VERSION ""

NS_ :

BS_:

BU_: Vector__XXX

BO_ 2566751742 EFL_P8: 8 Vector__XXX
SG_ EngIntkValveActOilPressForCyl13 : 0|16@1+ (0.1,0) [0|6425.5] "kPa" Vector__XXX
SG_ EngIntkValveActOilPressForCyl14 : 16|16@1+ (0.1,0) [0|6425.5] "kPa" Vector__XXX
SG_ EngIntkValveActOilPressForCyl15 : 32|16@1+ (0.1,0) [0|6425.5] "kPa" Vector__XXX
SG_ EngIntkValveActOilPressForCyl16 : 48|16@1+ (0.1,0) [0|6425.5] "kPa" Vector__XXX

BO_ 2566751998 EFL_P7: 8 Vector__XXX
SG_ EngIntkValveActOilPressForCyl9 : 0|16@1+ (0.1,0) [0|6425.5] "kPa" Vector__XXX
SG_ EngIntkValveActOilPressForCyl10 : 16|16@1+ (0.1,0) [0|6425.5] "kPa" Vector__XXX
SG_ EngIntkValveActOilPressForCyl11 : 32|16@1+ (0.1,0) [0|6425.5] "kPa" Vector__XXX
SG_ EngIntkValveActOilPressForCyl12 : 48|16@1+ (0.1,0) [0|6425.5] "kPa" Vector__XXX

BO_ 2566752254 EFL_P6: 8 Vector__XXX
SG_ EngIntkValveActOilPressForCyl5 : 0|16@1+ (0.1,0) [0|6425.5] "kPa" Vector__XXX
SG_ EngIntkValveActOilPressForCyl6 : 16|16@1+ (0.1,0) [0|6425.5] "kPa" Vector__XXX
SG_ EngIntkValveActOilPressForCyl7 : 32|16@1+ (0.1,0) [0|6425.5] "kPa" Vector__XXX
SG_ EngIntkValveActOilPressForCyl8 : 48|16@1+ (0.1,0) [0|6425.5] "kPa" Vector__XXX

BO_ 2566752510 EFL_P5: 8 Vector__XXX
SG_ EngIntkValveActOilPressForCyl1 : 0|16@1+ (0.1,0) [0|6425.5] "kPa" Vector__XXX
SG_ EngIntkValveActOilPressForCyl2 : 16|16@1+ (0.1,0) [0|6425.5] "kPa" Vector__XXX
SG_ EngIntkValveActOilPressForCyl3 : 32|16@1+ (0.1,0) [0|6425.5] "kPa" Vector__XXX
SG_ EngIntkValveActOilPressForCyl4 : 48|16@1+ (0.1,0) [0|6425.5] "kPa" Vector__XXX

BO_ 2566752766 VDS2: 8 Vector__XXX
SG_ VehicleRoll : 0|16@1+ (0.0078125,-200) [-200|301.99] "deg" Vector__XXX

BO_ 2633861886 J2012: 8 Vector__XXX
SG_ NumberOfJ2012DTCs : 0|8@1+ (1,0) [0|250] "" Vector__XXX
SG_ J2012DTC : 15|40@0+ (1,0) [0|0] "ASCII" Vector__XXX
SG_ J2012DTCStatus : 48|1@1+ (1,0) [0|1] "" Vector__XXX
SG_ J2012DTCOccurrenceCount : 49|7@1+ (1,0) [0|127] "" Vector__XXX

BO_ 2566753278 AT2GP: 8 Vector__XXX
SG_ Aftrtrtmnt2DslPFIntkPressure : 0|16@1+ (0.1,0) [0|6425.5] "kPa" Vector__XXX
SG_ Aftrtrtmnt2DslPFOtltPressure : 16|16@1+ (0.1,0) [0|6425.5] "kPa" Vector__XXX

BO_ 2566753534 AT1GP: 8 Vector__XXX
SG_ Aftrtrtmnt1DslPFIntkPressure : 0|16@1+ (0.1,0) [0|6425.5] "kPa" Vector__XXX
SG_ Aftrtrtmnt1DslPFOtltPressure : 16|16@1+ (0.1,0) [0|6425.5] "kPa" Vector__XXX

BO_ 2566753790 UTACER: 8 Vector__XXX
SG_ UtilityTotalKVArHoursExport : 0|32@1+ (1,0) [0|4211081215] "kVArh" Vector__XXX
SG_ UtilityTotalKVArHoursImport : 32|32@1+ (1,0) [0|4211081215] "kVArh" Vector__XXX

BO_ 2566754046 GTACER: 8 Vector__XXX
SG_ GeneratorTotalKVArHoursExport : 0|32@1+ (1,0) [0|4211081215] "kVArh" Vector__XXX
SG_ GeneratorTotalKVArHoursImport : 32|32@1+ (1,0) [0|4211081215] "kVArh" Vector__XXX

BO_ 2566754302 GTACPP: 8 Vector__XXX
SG_ GeneratorTotalPercentKW : 0|16@1+ (0.0078125,-251) [-251|250.99] "%" Vector__XXX
SG_ GeneratorTotalPercentKVA : 16|16@1+ (0.0078125,-251) [-251|250.99] "%" Vector__XXX
SG_ GeneratorTotalPercentKVAr : 32|16@1+ (0.0078125,-251) [-251|250.99] "%" Vector__XXX

BO_ 2566754558 AETC: 8 Vector__XXX
SG_ AETCDataCollectionStandard : 0|4@1+ (1,0) [0|15] "" Vector__XXX
SG_ NumberOfAETCDataPoints : 4|4@1+ (1,0) [0|15] "" Vector__XXX

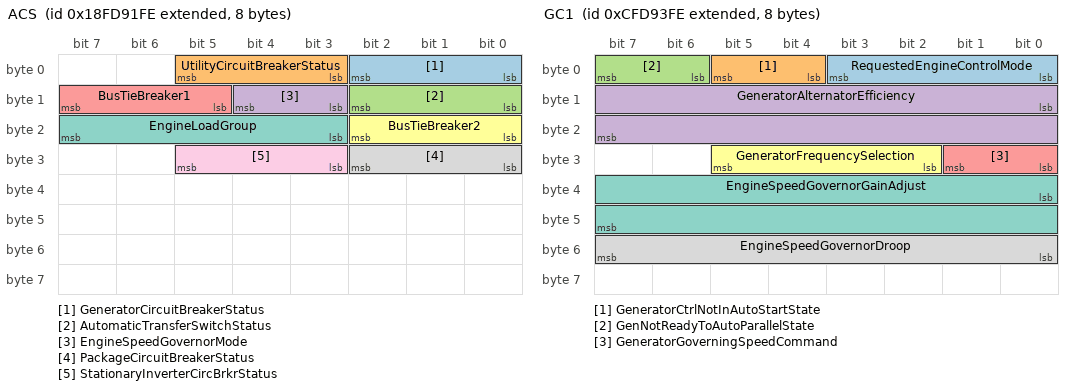
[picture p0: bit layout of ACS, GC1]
BO_ 2566754814 ACS: 8 Vector__XXX
SG_ GeneratorCircuitBreakerStatus : 0|3@1+ (1,0) [0|7] "" Vector__XXX
SG_ UtilityCircuitBreakerStatus : 3|3@1+ (1,0) [0|7] "" Vector__XXX
SG_ AutomaticTransferSwitchStatus : 8|3@1+ (1,0) [0|7] "" Vector__XXX
SG_ EngineSpeedGovernorMode : 11|2@1+ (1,0) [0|3] "" Vector__XXX
SG_ BusTieBreaker1 : 13|3@1+ (1,0) [0|7] "" Vector__XXX
SG_ BusTieBreaker2 : 16|3@1+ (1,0) [0|7] "" Vector__XXX
SG_ EngineLoadGroup : 19|5@1+ (1,0) [0|31] "" Vector__XXX
SG_ PackageCircuitBreakerStatus : 24|3@1+ (1,0) [0|7] "" Vector__XXX
SG_ StationaryInverterCircBrkrStatus : 27|3@1+ (1,0) [0|7] "" Vector__XXX

BO_ 2365428478 EOI: 8 Vector__XXX
SG_ EngineOperatingState : 0|4@1+ (1,0) [0|15] "" Vector__XXX
SG_ FuelPumpPrimerControl : 4|2@1+ (1,0) [0|3] "" Vector__XXX
SG_ EngineStarterMotorRelayControl : 6|2@1+ (1,0) [0|3] "" Vector__XXX
SG_ TimeRemainingInEngOperatingState : 8|16@1+ (1,0) [0|64255] "s" Vector__XXX
SG_ EngineFuelShutoffVentControl : 24|2@1+ (1,0) [0|3] "" Vector__XXX
SG_ EngineFuelShutoff1Control : 26|2@1+ (1,0) [0|3] "" Vector__XXX
SG_ EngineFuelShutoff2Control : 28|2@1+ (1,0) [0|3] "" Vector__XXX
SG_ EngFuelShutoffValveLeakTestCtrl : 30|2@1+ (1,0) [0|3] "" Vector__XXX
SG_ EngineOilPrimingPumpControl : 32|2@1+ (1,0) [0|3] "" Vector__XXX
SG_ EngineOilPreHeaterControl : 34|2@1+ (1,0) [0|3] "" Vector__XXX
SG_ EngElectrclSystemPwrConservCtrl : 36|2@1+ (1,0) [0|3] "" Vector__XXX
SG_ EnginePreHeaterControl : 38|2@1+ (1,0) [0|3] "" Vector__XXX
SG_ EngineCoolantPumpControl : 40|2@1+ (1,0) [0|3] "" Vector__XXX
SG_ EngineControlledShutdownRequest : 42|2@1+ (1,0) [0|3] "" Vector__XXX
SG_ EngineEmrgncyShutdownIndication : 44|2@1+ (1,0) [0|3] "" Vector__XXX
SG_ EngColdAmbientElevatedIdleStatus : 46|2@1+ (1,0) [0|3] "" Vector__XXX
SG_ EngineDesiredTorqueRequest : 48|8@1+ (1,-125) [-125|125] "%" Vector__XXX
SG_ EngineDerateRequest : 56|8@1+ (0.4,0) [0|100] "%" Vector__XXX

BO_ 2365428734 GC1: 8 Vector__XXX
SG_ RequestedEngineControlMode : 0|4@1+ (1,0) [0|15] "" Vector__XXX
SG_ GeneratorCtrlNotInAutoStartState : 4|2@1+ (1,0) [0|3] "" Vector__XXX
SG_ GenNotReadyToAutoParallelState : 6|2@1+ (1,0) [0|3] "" Vector__XXX
SG_ GeneratorAlternatorEfficiency : 8|16@1+ (0.0025,0) [0|160.6375] "%" Vector__XXX
SG_ GeneratorGoverningSpeedCommand : 24|2@1+ (1,0) [0|3] "" Vector__XXX
SG_ GeneratorFrequencySelection : 26|4@1+ (1,0) [0|15] "" Vector__XXX
SG_ EngineSpeedGovernorGainAdjust : 32|16@1+ (1,-32128) [-32128|32127] "" Vector__XXX
SG_ EngineSpeedGovernorDroop : 48|8@1+ (0.04,0) [0|10] "%" Vector__XXX

BO_ 2566755582 EEC7: 8 Vector__XXX
SG_ EngExhstGasRecirc1ValvePos : 0|16@1+ (0.0025,0) [0|160.6375] "%" Vector__XXX
SG_ EngExhstGasRecirc1Valve2Pos : 16|16@1+ (0.0025,0) [0|160.6375] "%" Vector__XXX
SG_ EngCrankCsBrearOilSeparatorSpd : 32|16@1+ (1,0) [0|64255] "rpm" Vector__XXX
SG_ EngIntakeManifoldCmdedPressure : 48|16@1+ (0.125,0) [0|8031.875] "kPa" Vector__XXX

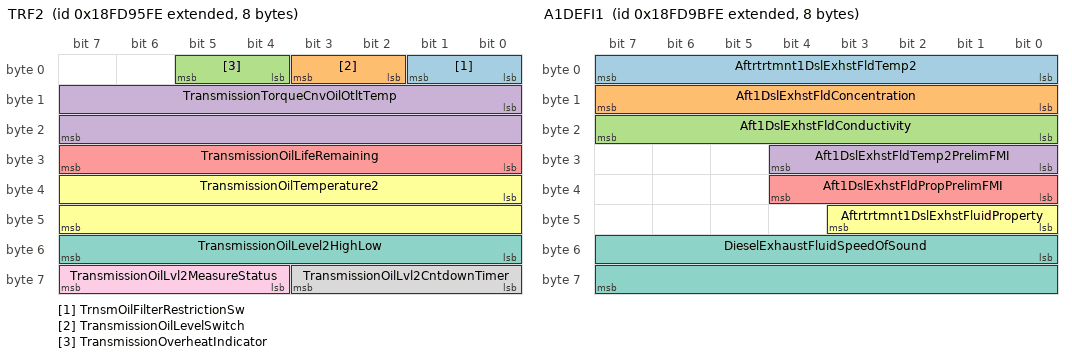
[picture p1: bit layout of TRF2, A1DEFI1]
BO_ 2566755838 TRF2: 8 Vector__XXX
SG_ TrnsmOilFilterRestrictionSw : 0|2@1+ (1,0) [0|3] "" Vector__XXX
SG_ TransmissionOilLevelSwitch : 2|2@1+ (1,0) [0|3] "" Vector__XXX
SG_ TransmissionOverheatIndicator : 4|2@1+ (1,0) [0|3] "" Vector__XXX
SG_ TransmissionTorqueCnvOilOtltTemp : 8|16@1+ (0.03125,-273) [-273|1734.96875] "deg C" Vector__XXX
SG_ TransmissionOilLifeRemaining : 24|8@1+ (0.4,0) [0|100] "%" Vector__XXX
SG_ TransmissionOilTemperature2 : 32|16@1+ (0.03125,-273) [-273|1734.96875] "deg C" Vector__XXX
SG_ TransmissionOilLevel2HighLow : 48|8@1+ (0.5,-62.5) [-62.5|62.5] "l" Vector__XXX
SG_ TransmissionOilLvl2CntdownTimer : 56|4@1+ (1,0) [0|15] "" Vector__XXX
SG_ TransmissionOilLvl2MeasureStatus : 60|4@1+ (1,0) [0|15] "" Vector__XXX

BO_ 2566756094 LFI2: 8 Vector__XXX
SG_ EngineFuelSupplyFlowRate : 0|32@1+ (0.001,0) [0|4211081.215] "l/h" Vector__XXX
SG_ EngineFuelReturnFlowRate : 32|32@1+ (0.001,0) [0|4211081.215] "l/h" Vector__XXX

BO_ 2566756350 LFI3: 8 Vector__XXX
SG_ EngineFuelSupplyTemperature : 0|8@1+ (1,-40) [-40|210] "deg C" Vector__XXX
SG_ EngineFuelReturnTemperature : 8|8@1+ (1,-40) [-40|210] "deg C" Vector__XXX

BO_ 2566756606 AT1HI1: 40 Vector__XXX
SG_ Aftertreatment1TotalFuelUsed : 0|32@1+ (0.5,0) [0|2105540607.5] "l" Vector__XXX
SG_ Aftrtrtmnt1TotalRegenerationTime : 32|32@1+ (1,0) [0|4211081215] "s" Vector__XXX
SG_ Aftertreatment1TotalDisabledTime : 64|32@1+ (1,0) [0|4211081215] "s" Vector__XXX
SG_ Aftrtrtmnt1TotalNoOfActvRegens : 96|32@1+ (1,0) [0|4211081215] "" Vector__XXX
SG_ Aft1DslPFTotalPassiveRegenTme : 128|32@1+ (1,0) [0|4211081215] "s" Vector__XXX
SG_ Aft1DslPFTotalNoOfPassiveRegens : 160|32@1+ (1,0) [0|4211081215] "" Vector__XXX
SG_ Aft1DPFTotalNoOfActRegenInhbtRqs : 192|32@1+ (1,0) [0|4211081215] "" Vector__XXX
SG_ Aft1DslPFTotalNoOfActRegenManRqs : 224|32@1+ (1,0) [0|4211081215] "" Vector__XXX
SG_ Aft1DPFAvrgTmeBetweenActvRegens : 256|32@1+ (1,0) [0|4211081215] "s" Vector__XXX
SG_ Aft1DPFAvrgDistBetweenActvRegens : 288|32@1+ (0.125,0) [0|526385151.875] "km" Vector__XXX

BO_ 2566756862 AT2HI1: 40 Vector__XXX
SG_ Aftertreatment2TotalFuelUsed : 0|32@1+ (0.5,0) [0|2105540607.5] "l" Vector__XXX
SG_ Aftrtrtmnt2TotalRegenerationTime : 32|32@1+ (1,0) [0|4211081215] "s" Vector__XXX
SG_ Aftertreatment2TotalDisabledTime : 64|32@1+ (1,0) [0|4211081215] "s" Vector__XXX
SG_ Aftrtrtmnt2TotalNoOfActvRegens : 96|32@1+ (1,0) [0|4211081215] "" Vector__XXX
SG_ Aft2DslPFTotalPassiveRegenTme : 128|32@1+ (1,0) [0|4211081215] "s" Vector__XXX
SG_ Aft2DslPFTotalNoOfPassiveRegens : 160|32@1+ (1,0) [0|4211081215] "" Vector__XXX
SG_ Aft2DPFTotalNoOfActRegenInhbtRqs : 192|32@1+ (1,0) [0|4211081215] "" Vector__XXX
SG_ Aft2DslPFTotalNoOfActRegenManRqs : 224|32@1+ (1,0) [0|4211081215] "" Vector__XXX
SG_ Aft2DPFAvrgTmeBetweenActvRegens : 256|32@1+ (1,0) [0|4211081215] "s" Vector__XXX
SG_ Aft2DPFAvrgDistBetweenActvRegens : 288|32@1+ (0.125,0) [0|526385151.875] "km" Vector__XXX

BO_ 2566757374 A1DEFI1: 8 Vector__XXX
SG_ Aftrtrtmnt1DslExhstFldTemp2 : 0|8@1+ (1,-40) [-40|210] "deg C" Vector__XXX
SG_ Aft1DslExhstFldConcentration : 8|8@1+ (0.25,0) [0|62.5] "%" Vector__XXX
SG_ Aft1DslExhstFldConductivity : 16|8@1+ (5,0) [0|1250] "uSiemens/mm" Vector__XXX
SG_ Aft1DslExhstFldTemp2PrelimFMI : 24|5@1+ (1,0) [0|31] "" Vector__XXX
SG_ Aft1DslExhstFldPropPrelimFMI : 32|5@1+ (1,0) [0|31] "" Vector__XXX
SG_ Aftrtrtmnt1DslExhstFluidProperty : 40|4@1+ (1,0) [0|15] "" Vector__XXX
SG_ DieselExhaustFluidSpeedOfSound : 48|16@1+ (0.1,0) [0|6425.5] "m/s" Vector__XXX

BO_ 2566757630 SEP2: 8 Vector__XXX
SG_ SensorSupplyVoltage5 : 0|16@1+ (0.05,0) [0|3212.75] "V" Vector__XXX
SG_ SensorSupplyVoltage6 : 16|16@1+ (0.05,0) [0|3212.75] "V" Vector__XXX
SG_ SensorSupplyVoltage7 : 32|16@1+ (0.05,0) [0|3212.75] "V" Vector__XXX
SG_ SensorSupplyVoltage8 : 48|16@1+ (0.05,0) [0|3212.75] "V" Vector__XXX

BO_ 2566757886 SEP1: 8 Vector__XXX
SG_ SensorSupplyVoltage1 : 0|16@1+ (0.05,0) [0|3212.75] "V" Vector__XXX
SG_ SensorSupplyVoltage2 : 16|16@1+ (0.05,0) [0|3212.75] "V" Vector__XXX
SG_ SensorSupplyVoltage3 : 32|16@1+ (0.05,0) [0|3212.75] "V" Vector__XXX
SG_ SensorSupplyVoltage4 : 48|16@1+ (0.05,0) [0|3212.75] "V" Vector__XXX

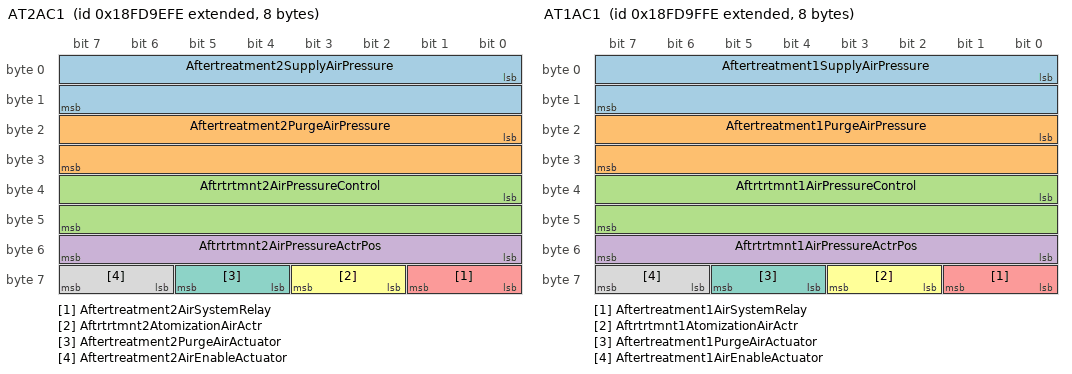
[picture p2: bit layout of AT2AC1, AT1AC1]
BO_ 2566758142 AT2AC1: 8 Vector__XXX
SG_ Aftertreatment2SupplyAirPressure : 0|16@1+ (0.1,0) [0|6425.5] "kPa" Vector__XXX
SG_ Aftertreatment2PurgeAirPressure : 16|16@1+ (0.1,0) [0|6425.5] "kPa" Vector__XXX
SG_ Aftrtrtmnt2AirPressureControl : 32|16@1+ (0.0025,0) [0|160.6375] "%" Vector__XXX
SG_ Aftrtrtmnt2AirPressureActrPos : 48|8@1+ (0.4,0) [0|100] "%" Vector__XXX
SG_ Aftertreatment2AirSystemRelay : 56|2@1+ (1,0) [0|3] "" Vector__XXX
SG_ Aftrtrtmnt2AtomizationAirActr : 58|2@1+ (1,0) [0|3] "" Vector__XXX
SG_ Aftertreatment2PurgeAirActuator : 60|2@1+ (1,0) [0|3] "" Vector__XXX
SG_ Aftertreatment2AirEnableActuator : 62|2@1+ (1,0) [0|3] "" Vector__XXX

BO_ 2566758398 AT1AC1: 8 Vector__XXX
SG_ Aftertreatment1SupplyAirPressure : 0|16@1+ (0.1,0) [0|6425.5] "kPa" Vector__XXX
SG_ Aftertreatment1PurgeAirPressure : 16|16@1+ (0.1,0) [0|6425.5] "kPa" Vector__XXX
SG_ Aftrtrtmnt1AirPressureControl : 32|16@1+ (0.0025,0) [0|160.6375] "%" Vector__XXX
SG_ Aftrtrtmnt1AirPressureActrPos : 48|8@1+ (0.4,0) [0|100] "%" Vector__XXX
SG_ Aftertreatment1AirSystemRelay : 56|2@1+ (1,0) [0|3] "" Vector__XXX
SG_ Aftrtrtmnt1AtomizationAirActr : 58|2@1+ (1,0) [0|3] "" Vector__XXX
SG_ Aftertreatment1PurgeAirActuator : 60|2@1+ (1,0) [0|3] "" Vector__XXX
SG_ Aftertreatment1AirEnableActuator : 62|2@1+ (1,0) [0|3] "" Vector__XXX

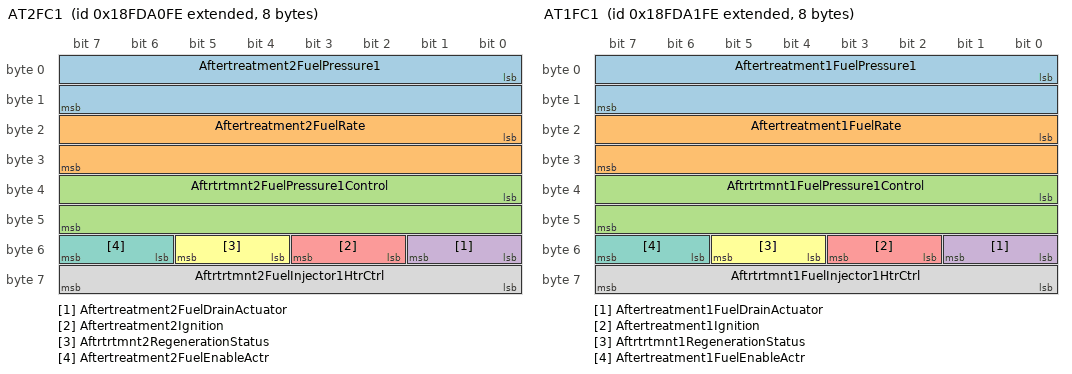
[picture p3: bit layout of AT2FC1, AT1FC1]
BO_ 2566758654 AT2FC1: 8 Vector__XXX
SG_ Aftertreatment2FuelPressure1 : 0|16@1+ (0.1,0) [0|6425.5] "kPa" Vector__XXX
SG_ Aftertreatment2FuelRate : 16|16@1+ (0.05,0) [0|3212.75] "l/h" Vector__XXX
SG_ Aftrtrtmnt2FuelPressure1Control : 32|16@1+ (0.0025,0) [0|160.6375] "%" Vector__XXX
SG_ Aftertreatment2FuelDrainActuator : 48|2@1+ (1,0) [0|3] "" Vector__XXX
SG_ Aftertreatment2Ignition : 50|2@1+ (1,0) [0|3] "" Vector__XXX
SG_ Aftrtrtmnt2RegenerationStatus : 52|2@1+ (1,0) [0|3] "" Vector__XXX
SG_ Aftertreatment2FuelEnableActr : 54|2@1+ (1,0) [0|3] "" Vector__XXX
SG_ Aftrtrtmnt2FuelInjector1HtrCtrl : 56|8@1+ (0.4,0) [0|100] "%" Vector__XXX

BO_ 2566758910 AT1FC1: 8 Vector__XXX
SG_ Aftertreatment1FuelPressure1 : 0|16@1+ (0.1,0) [0|6425.5] "kPa" Vector__XXX
SG_ Aftertreatment1FuelRate : 16|16@1+ (0.05,0) [0|3212.75] "l/h" Vector__XXX
SG_ Aftrtrtmnt1FuelPressure1Control : 32|16@1+ (0.0025,0) [0|160.6375] "%" Vector__XXX
SG_ Aftertreatment1FuelDrainActuator : 48|2@1+ (1,0) [0|3] "" Vector__XXX
SG_ Aftertreatment1Ignition : 50|2@1+ (1,0) [0|3] "" Vector__XXX
SG_ Aftrtrtmnt1RegenerationStatus : 52|2@1+ (1,0) [0|3] "" Vector__XXX
SG_ Aftertreatment1FuelEnableActr : 54|2@1+ (1,0) [0|3] "" Vector__XXX
SG_ Aftrtrtmnt1FuelInjector1HtrCtrl : 56|8@1+ (0.4,0) [0|100] "%" Vector__XXX

BO_ 2432541438 GFI3: 8 Vector__XXX
SG_ EngFuelValve2IntakeAbsPressure : 0|16@1+ (0.1,0) [0|6425.5] "kPa" Vector__XXX
SG_ EngineFuelSystem2GasMassFlowRate : 16|16@1+ (0.05,0) [0|3212.75] "kg/h" Vector__XXX
SG_ EngineFuelTemperature2 : 32|8@1+ (1,-40) [-40|210] "deg C" Vector__XXX
SG_ EngFuelValve2OutletAbsPressure : 48|16@1+ (0.1,0) [0|6425.5] "kPa" Vector__XXX

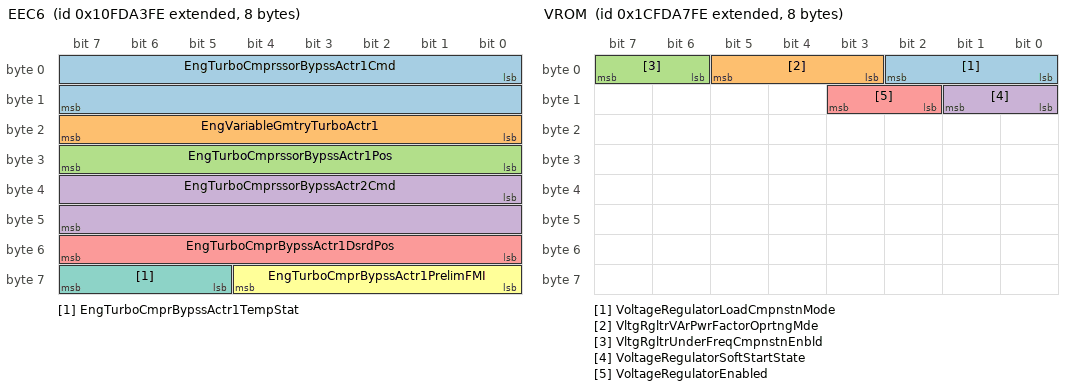
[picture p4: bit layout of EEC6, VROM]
BO_ 2432541694 EEC6: 8 Vector__XXX
SG_ EngTurboCmprssorBypssActr1Cmd : 0|16@1+ (0.0025,0) [0|160.6375] "%" Vector__XXX
SG_ EngVariableGmtryTurboActr1 : 16|8@1+ (0.4,0) [0|100] "%" Vector__XXX
SG_ EngTurboCmprssorBypssActr1Pos : 24|8@1+ (0.4,0) [0|100] "%" Vector__XXX
SG_ EngTurboCmprssorBypssActr2Cmd : 32|16@1+ (0.0025,0) [0|160.6375] "%" Vector__XXX
SG_ EngTurboCmprBypssActr1DsrdPos : 48|8@1+ (0.4,0) [0|100] "%" Vector__XXX
SG_ EngTurboCmprBypssActr1PrelimFMI : 56|5@1+ (1,0) [0|31] "" Vector__XXX
SG_ EngTurboCmprBypssActr1TempStat : 61|3@1+ (1,0) [0|7] "" Vector__XXX

BO_ 2566759678 PTODE: 8 Vector__XXX
SG_ EnblSwitchTransferCsOutptShftPTO : 0|2@1+ (1,0) [0|3] "" Vector__XXX
SG_ EnblSwTransmissionOutptShftPTO : 2|2@1+ (1,0) [0|3] "" Vector__XXX
SG_ EnblSwTransmissionInputShftPTO2 : 4|2@1+ (1,0) [0|3] "" Vector__XXX
SG_ EnblSwTransmissionInputShftPTO1 : 6|2@1+ (1,0) [0|3] "" Vector__XXX
SG_ EnableSwitchPTOEngineFlywheel : 8|2@1+ (1,0) [0|3] "" Vector__XXX
SG_ EnableSwitchPTOEngineAccssryDrv1 : 10|2@1+ (1,0) [0|3] "" Vector__XXX
SG_ EnableSwitchPTOEngineAccssryDrv2 : 12|2@1+ (1,0) [0|3] "" Vector__XXX
SG_ EngmntConsntTrnsfrCsOutptShftPTO : 16|2@1+ (1,0) [0|3] "" Vector__XXX
SG_ EngmntConsntTrnsmOutptShftPTO : 18|2@1+ (1,0) [0|3] "" Vector__XXX
SG_ EngmntConsntTrnsmInputShftPTO2 : 20|2@1+ (1,0) [0|3] "" Vector__XXX
SG_ EngmntConsntTrnsmInputShftPTO1 : 22|2@1+ (1,0) [0|3] "" Vector__XXX
SG_ EngmntConsntPTOEngineFlywheel : 24|2@1+ (1,0) [0|3] "" Vector__XXX
SG_ EngmntConsntPTOEngineAccssryDrv1 : 26|2@1+ (1,0) [0|3] "" Vector__XXX
SG_ EngmntConsntPTOEngineAccssryDrv2 : 28|2@1+ (1,0) [0|3] "" Vector__XXX
SG_ EngmntStatTransferCsOutptShftPTO : 32|2@1+ (1,0) [0|3] "" Vector__XXX
SG_ EngmntStatTrnsmOutptShftPTO : 34|2@1+ (1,0) [0|3] "" Vector__XXX
SG_ EngmntStatTrnsmInputShftPTO2 : 36|2@1+ (1,0) [0|3] "" Vector__XXX
SG_ EngmntStatTrnsmInputShftPTO1 : 38|2@1+ (1,0) [0|3] "" Vector__XXX
SG_ EngmntStatusPTOEngineFlywheel : 40|2@1+ (1,0) [0|3] "" Vector__XXX
SG_ EngmntStatusPTOEngineAccssryDrv1 : 42|2@1+ (1,0) [0|3] "" Vector__XXX
SG_ EngmntStatusPTOEngineAccssryDrv2 : 44|2@1+ (1,0) [0|3] "" Vector__XXX
SG_ AtLeastOnePTOEngaged : 48|2@1+ (1,0) [0|3] "" Vector__XXX

BO_ 2566759934 DC2: 8 Vector__XXX
SG_ LockStatusOfDoor1 : 0|2@1+ (1,0) [0|3] "" Vector__XXX
SG_ OpenStatusOfDoor1 : 2|2@1+ (1,0) [0|3] "" Vector__XXX
SG_ EnableStatusOfDoor1 : 4|2@1+ (1,0) [0|3] "" Vector__XXX
SG_ LockStatusOfDoor2 : 6|2@1+ (1,0) [0|3] "" Vector__XXX
SG_ OpenStatusOfDoor2 : 8|2@1+ (1,0) [0|3] "" Vector__XXX
SG_ EnableStatusOfDoor2 : 10|2@1+ (1,0) [0|3] "" Vector__XXX
SG_ LockStatusOfDoor3 : 12|2@1+ (1,0) [0|3] "" Vector__XXX
SG_ OpenStatusOfDoor3 : 14|2@1+ (1,0) [0|3] "" Vector__XXX
SG_ EnableStatusOfDoor3 : 16|2@1+ (1,0) [0|3] "" Vector__XXX
SG_ LockStatusOfDoor4 : 18|2@1+ (1,0) [0|3] "" Vector__XXX
SG_ OpenStatusOfDoor4 : 20|2@1+ (1,0) [0|3] "" Vector__XXX
SG_ EnableStatusOfDoor4 : 22|2@1+ (1,0) [0|3] "" Vector__XXX
SG_ LockStatusOfDoor5 : 24|2@1+ (1,0) [0|3] "" Vector__XXX
SG_ OpenStatusOfDoor5 : 26|2@1+ (1,0) [0|3] "" Vector__XXX
SG_ EnableStatusOfDoor5 : 28|2@1+ (1,0) [0|3] "" Vector__XXX
SG_ LockStatusOfDoor6 : 30|2@1+ (1,0) [0|3] "" Vector__XXX
SG_ OpenStatusOfDoor6 : 32|2@1+ (1,0) [0|3] "" Vector__XXX
SG_ EnableStatusOfDoor6 : 34|2@1+ (1,0) [0|3] "" Vector__XXX
SG_ LockStatusOfDoor7 : 36|2@1+ (1,0) [0|3] "" Vector__XXX
SG_ OpenStatusOfDoor7 : 38|2@1+ (1,0) [0|3] "" Vector__XXX
SG_ EnableStatusOfDoor7 : 40|2@1+ (1,0) [0|3] "" Vector__XXX
SG_ LockStatusOfDoor8 : 42|2@1+ (1,0) [0|3] "" Vector__XXX
SG_ OpenStatusOfDoor8 : 44|2@1+ (1,0) [0|3] "" Vector__XXX
SG_ EnableStatusOfDoor8 : 46|2@1+ (1,0) [0|3] "" Vector__XXX
SG_ LockStatusOfDoor9 : 48|2@1+ (1,0) [0|3] "" Vector__XXX
SG_ OpenStatusOfDoor9 : 50|2@1+ (1,0) [0|3] "" Vector__XXX
SG_ EnableStatusOfDoor9 : 52|2@1+ (1,0) [0|3] "" Vector__XXX
SG_ LockStatusOfDoor10 : 54|2@1+ (1,0) [0|3] "" Vector__XXX
SG_ OpenStatusOfDoor10 : 56|2@1+ (1,0) [0|3] "" Vector__XXX
SG_ EnableStatusOfDoor10 : 58|2@1+ (1,0) [0|3] "" Vector__XXX

BO_ 2365433598 VREP: 8 Vector__XXX
SG_ GeneratorExcitationFieldVoltage : 0|16@1+ (0.05,-1606) [-1606|1606.75] "V" Vector__XXX
SG_ GeneratorExcitationFieldCurrent : 16|16@1+ (0.05,0) [0|3212.75] "A" Vector__XXX
SG_ GenOutputVoltageBiasPercentage : 32|16@1+ (0.1,-3212.75) [-3212.75|3212.75] "%" Vector__XXX

BO_ 2633869310 VROM: 8 Vector__XXX
SG_ VoltageRegulatorLoadCmpnstnMode : 0|3@1+ (1,0) [0|7] "" Vector__XXX
SG_ VltgRgltrVArPwrFactorOprtngMde : 3|3@1+ (1,0) [0|7] "" Vector__XXX
SG_ VltgRgltrUnderFreqCmpnstnEnbld : 6|2@1+ (1,0) [0|3] "" Vector__XXX
SG_ VoltageRegulatorSoftStartState : 8|2@1+ (1,0) [0|3] "" Vector__XXX
SG_ VoltageRegulatorEnabled : 10|2@1+ (1,0) [0|3] "" Vector__XXX

BO_ 2566760702 WCM2: 8 Vector__XXX
SG_ NetworkTransceiverStatus2 : 0|8@1+ (1,0) [0|255] "" Vector__XXX
SG_ NetworkServiceStatus2 : 8|8@1+ (1,0) [0|255] "" Vector__XXX
SG_ NetworkAntennaStatus2 : 16|8@1+ (1,0) [0|255] "" Vector__XXX
SG_ NetworkSignalStrength2 : 24|8@1+ (0.4,0) [0|100] "%" Vector__XXX
SG_ WirelessCommNetworkType2 : 32|8@1+ (1,0) [0|255] "" Vector__XXX

BO_ 2566760958 WCM1: 8 Vector__XXX
SG_ NetworkTransceiverStatus1 : 0|8@1+ (1,0) [0|255] "" Vector__XXX
SG_ NetworkServiceStatus1 : 8|8@1+ (1,0) [0|255] "" Vector__XXX
SG_ NetworkAntennaStatus1 : 16|8@1+ (1,0) [0|255] "" Vector__XXX
SG_ NetworkSignalStrength1 : 24|8@1+ (0.4,0) [0|100] "%" Vector__XXX
SG_ WirelessCommNetworkType1 : 32|8@1+ (1,0) [0|255] "" Vector__XXX

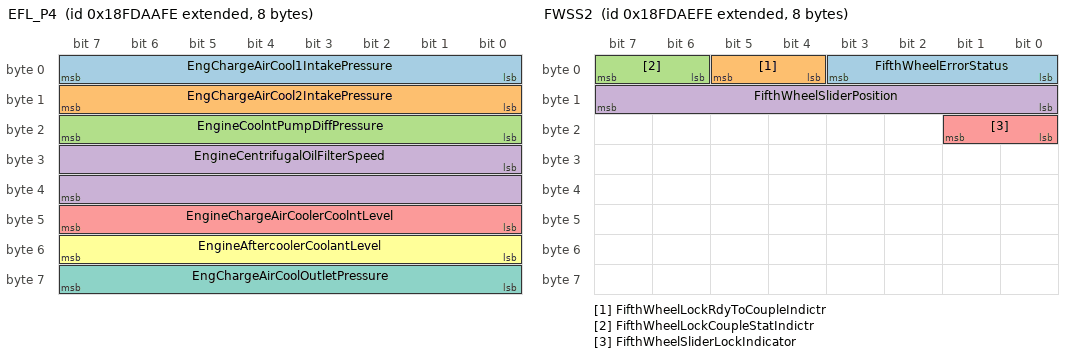
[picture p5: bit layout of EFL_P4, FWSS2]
BO_ 2566761214 EFL_P4: 8 Vector__XXX
SG_ EngChargeAirCool1IntakePressure : 0|8@1+ (2,0) [0|500] "kPa" Vector__XXX
SG_ EngChargeAirCool2IntakePressure : 8|8@1+ (2,0) [0|500] "kPa" Vector__XXX
SG_ EngineCoolntPumpDiffPressure : 16|8@1+ (1.64,-7) [-7|403] "kPa" Vector__XXX
SG_ EngineCentrifugalOilFilterSpeed : 24|16@1+ (4,0) [0|257020] "rpm" Vector__XXX
SG_ EngineChargeAirCoolerCoolntLevel : 40|8@1+ (0.4,0) [0|100] "%" Vector__XXX
SG_ EngineAftercoolerCoolantLevel : 48|8@1+ (0.4,0) [0|100] "%" Vector__XXX
SG_ EngChargeAirCoolOutletPressure : 56|8@1+ (2,0) [0|500] "kPa" Vector__XXX

BO_ 2566761726 EFI: 8 Vector__XXX
SG_ NoFuelCnsmptnMontingTransducers : 0|8@1+ (1,0) [0|250] "" Vector__XXX
SG_ EngineIdleFuelFlowRateThreshold : 8|32@1+ (0.001,0) [0|4211081.215] "l/h" Vector__XXX

BO_ 2566761982 RCMS: 8 Vector__XXX
SG_ MessageSelectionControl : 0|8@1+ (1,0) [0|250] "" Vector__XXX
SG_ PGNOfConfigurableMessageDesired : 8|24@1+ (1,0) [0|16777215] "" Vector__XXX

BO_ 2566762238 FWSS2: 8 Vector__XXX
SG_ FifthWheelErrorStatus : 0|4@1+ (1,0) [0|15] "" Vector__XXX
SG_ FifthWheelLockRdyToCoupleIndictr : 4|2@1+ (1,0) [0|3] "" Vector__XXX
SG_ FifthWheelLockCoupleStatIndictr : 6|2@1+ (1,0) [0|3] "" Vector__XXX
SG_ FifthWheelSliderPosition : 8|8@1+ (10,0) [0|2500] "mm" Vector__XXX
SG_ FifthWheelSliderLockIndicator : 16|2@1+ (1,0) [0|3] "" Vector__XXX

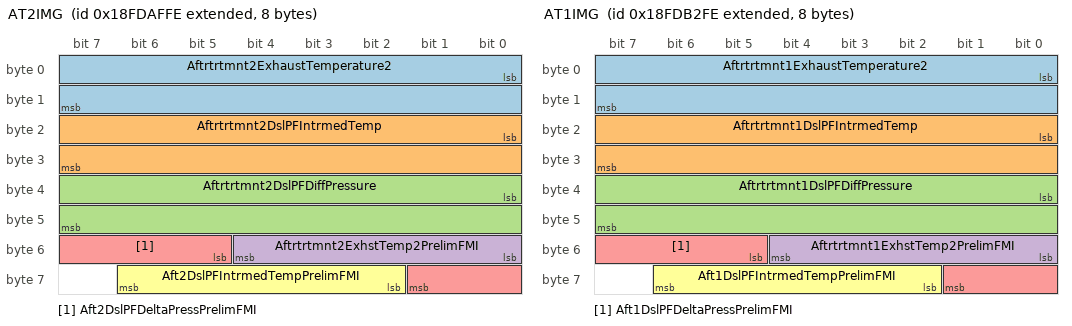
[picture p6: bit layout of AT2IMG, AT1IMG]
BO_ 2566762494 AT2IMG: 8 Vector__XXX
SG_ Aftrtrtmnt2ExhaustTemperature2 : 0|16@1+ (0.03125,-273) [-273|1734.96875] "deg C" Vector__XXX
SG_ Aftrtrtmnt2DslPFIntrmedTemp : 16|16@1+ (0.03125,-273) [-273|1734.96875] "deg C" Vector__XXX
SG_ Aftrtrtmnt2DslPFDiffPressure : 32|16@1+ (0.1,0) [0|6425.5] "kPa" Vector__XXX
SG_ Aftrtrtmnt2ExhstTemp2PrelimFMI : 48|5@1+ (1,0) [0|31] "" Vector__XXX
SG_ Aft2DslPFDeltaPressPrelimFMI : 53|5@1+ (1,0) [0|31] "" Vector__XXX
SG_ Aft2DslPFIntrmedTempPrelimFMI : 58|5@1+ (1,0) [0|31] "" Vector__XXX

BO_ 2566762750 AT2OG2: 8 Vector__XXX
SG_ Aftrtrtmnt2ExhaustTemperature3 : 0|16@1+ (0.03125,-273) [-273|1734.96875] "deg C" Vector__XXX
SG_ Aftrtrtmnt2DslPFOtltTemperature : 16|16@1+ (0.03125,-273) [-273|1734.96875] "deg C" Vector__XXX
SG_ Aftrtrtmnt2ExhstTemp3PrelimFMI : 32|5@1+ (1,0) [0|31] "" Vector__XXX
SG_ Aft2DslPFExhstTempPrelimFMI : 40|5@1+ (1,0) [0|31] "" Vector__XXX

BO_ 2566763006 AT2IG2: 8 Vector__XXX
SG_ Aftrtrtmnt2ExhaustTemperature1 : 0|16@1+ (0.03125,-273) [-273|1734.96875] "deg C" Vector__XXX
SG_ Aftrtrtmnt2DslPFIntkTemperature : 16|16@1+ (0.03125,-273) [-273|1734.96875] "deg C" Vector__XXX
SG_ Aftrtrtmnt2ExhstTemp1PrelimFMI : 32|5@1+ (1,0) [0|31] "" Vector__XXX
SG_ Aft2DslPFIntkTempPrelimFMI : 40|5@1+ (1,0) [0|31] "" Vector__XXX

BO_ 2566763262 AT1IMG: 8 Vector__XXX
SG_ Aftrtrtmnt1ExhaustTemperature2 : 0|16@1+ (0.03125,-273) [-273|1734.96875] "deg C" Vector__XXX
SG_ Aftrtrtmnt1DslPFIntrmedTemp : 16|16@1+ (0.03125,-273) [-273|1734.96875] "deg C" Vector__XXX
SG_ Aftrtrtmnt1DslPFDiffPressure : 32|16@1+ (0.1,0) [0|6425.5] "kPa" Vector__XXX
SG_ Aftrtrtmnt1ExhstTemp2PrelimFMI : 48|5@1+ (1,0) [0|31] "" Vector__XXX
SG_ Aft1DslPFDeltaPressPrelimFMI : 53|5@1+ (1,0) [0|31] "" Vector__XXX
SG_ Aft1DslPFIntrmedTempPrelimFMI : 58|5@1+ (1,0) [0|31] "" Vector__XXX

BO_ 2566763518 AT1OG2: 8 Vector__XXX
SG_ Aftrtrtmnt1ExhaustTemperature3 : 0|16@1+ (0.03125,-273) [-273|1734.96875] "deg C" Vector__XXX
SG_ Aftrtrtmnt1DslPFOtltTemperature : 16|16@1+ (0.03125,-273) [-273|1734.96875] "deg C" Vector__XXX
SG_ Aftrtrtmnt1ExhstTemp3PrelimFMI : 32|5@1+ (1,0) [0|31] "" Vector__XXX
SG_ Aft1DslPFOtltExhstTempPrelimFMI : 40|5@1+ (1,0) [0|31] "" Vector__XXX

BO_ 2566763774 AT1IG2: 8 Vector__XXX
SG_ Aftrtrtmnt1ExhaustTemperature1 : 0|16@1+ (0.03125,-273) [-273|1734.96875] "deg C" Vector__XXX
SG_ Aftrtrtmnt1DslPFIntkTemperature : 16|16@1+ (0.03125,-273) [-273|1734.96875] "deg C" Vector__XXX
SG_ Aftrtrtmnt1ExhstTemp1PrelimFMI : 32|5@1+ (1,0) [0|31] "" Vector__XXX
SG_ Aft1DslPFIntkTempPrelimFMI : 40|5@1+ (1,0) [0|31] "" Vector__XXX

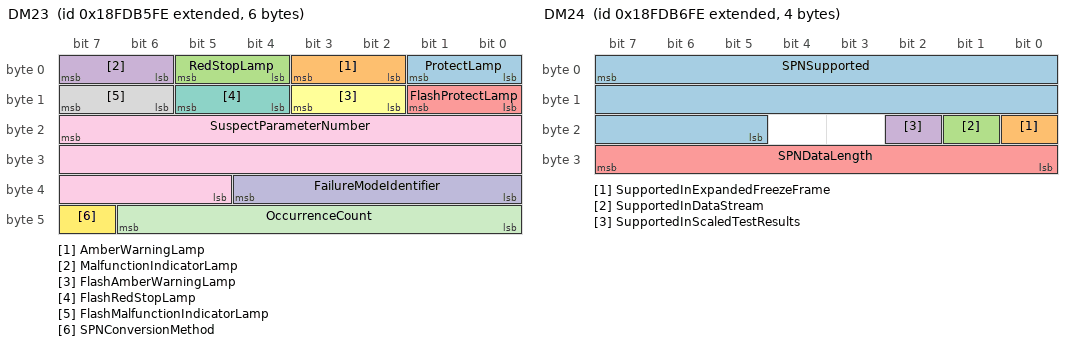
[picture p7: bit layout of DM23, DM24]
BO_ 2566764030 DM23: 6 Vector__XXX
SG_ ProtectLamp : 0|2@1+ (1,0) [0|3] "" Vector__XXX
SG_ AmberWarningLamp : 2|2@1+ (1,0) [0|3] "" Vector__XXX
SG_ RedStopLamp : 4|2@1+ (1,0) [0|3] "" Vector__XXX
SG_ MalfunctionIndicatorLamp : 6|2@1+ (1,0) [0|3] "" Vector__XXX
SG_ FlashProtectLamp : 8|2@1+ (1,0) [0|3] "" Vector__XXX
SG_ FlashAmberWarningLamp : 10|2@1+ (1,0) [0|3] "" Vector__XXX
SG_ FlashRedStopLamp : 12|2@1+ (1,0) [0|3] "" Vector__XXX
SG_ FlashMalfunctionIndicatorLamp : 14|2@1+ (1,0) [0|3] "" Vector__XXX
SG_ SuspectParameterNumber : 23|19@0+ (1,0) [0|524287] "" Vector__XXX
SG_ FailureModeIdentifier : 32|5@1+ (1,0) [0|31] "" Vector__XXX
SG_ OccurrenceCount : 40|7@1+ (1,0) [0|127] "" Vector__XXX
SG_ SPNConversionMethod : 47|1@1+ (1,0) [0|1] "" Vector__XXX

BO_ 2566764286 DM24: 4 Vector__XXX
SG_ SPNSupported : 7|19@0+ (1,0) [0|524287] "" Vector__XXX
SG_ SupportedInExpandedFreezeFrame : 16|1@1+ (1,0) [0|1] "" Vector__XXX
SG_ SupportedInDataStream : 17|1@1+ (1,0) [0|1] "" Vector__XXX
SG_ SupportedInScaledTestResults : 18|1@1+ (1,0) [0|1] "" Vector__XXX
SG_ SPNDataLength : 24|8@1+ (1,0) [0|250] "" Vector__XXX

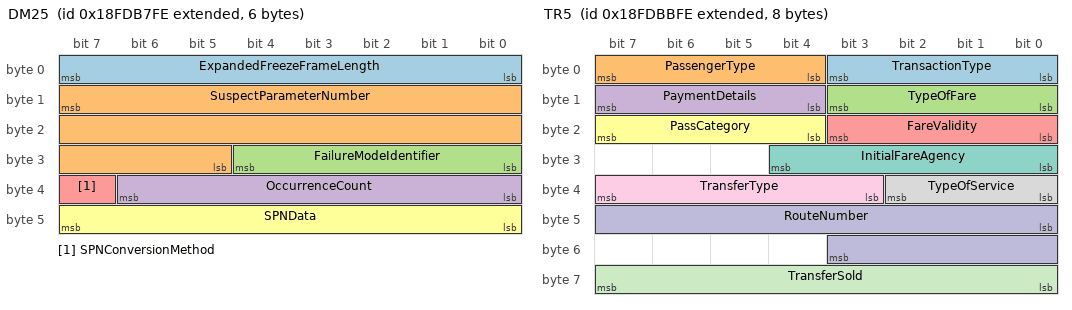
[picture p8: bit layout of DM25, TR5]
BO_ 2566764542 DM25: 6 Vector__XXX
SG_ ExpandedFreezeFrameLength : 0|8@1+ (1,0) [0|255] "" Vector__XXX
SG_ SuspectParameterNumber : 15|19@0+ (1,0) [0|524287] "" Vector__XXX
SG_ FailureModeIdentifier : 24|5@1+ (1,0) [0|31] "" Vector__XXX
SG_ OccurrenceCount : 32|7@1+ (1,0) [0|127] "" Vector__XXX
SG_ SPNConversionMethod : 39|1@1+ (1,0) [0|1] "" Vector__XXX
SG_ SPNData : 40|8@1+ (1,0) [0|255] "" Vector__XXX

BO_ 2566764798 DM26: 8 Vector__XXX
SG_ TimeSinceEngineStart : 0|16@1+ (1,0) [0|64255] "s" Vector__XXX
SG_ NoWarmUpsSncDiagTroubleCodesClrd : 16|8@1+ (1,0) [0|250] "" Vector__XXX
SG_ CntinlyMontrdSysEnbldCmpltdStat : 24|8@1+ (1,0) [0|255] "" Vector__XXX
SG_ NonCntinlyMontrdSystemsEnbldStat : 32|16@1+ (1,0) [0|65535] "" Vector__XXX
SG_ NonCntinlyMontrdSysCompleteStat : 48|16@1+ (1,0) [0|65535] "" Vector__XXX

BO_ 2566765054 TPRI: 8 Vector__XXX
SG_ TireLocation : 0|8@1+ (1,0) [0|255] "" Vector__XXX
SG_ ReferenceTirePressure : 8|8@1+ (8,0) [0|2000] "kPa" Vector__XXX

BO_ 2566765310 TR6: 8 Vector__XXX
SG_ FareboxEmergencyStatus : 0|2@1+ (1,0) [0|3] "" Vector__XXX
SG_ FareboxAlarmIdentifier : 8|7@1+ (1,0) [0|127] "" Vector__XXX

BO_ 2566765566 TR5: 8 Vector__XXX
SG_ TransactionType : 0|4@1+ (1,0) [0|15] "" Vector__XXX
SG_ PassengerType : 4|4@1+ (1,0) [0|15] "" Vector__XXX
SG_ TypeOfFare : 8|4@1+ (1,0) [0|15] "" Vector__XXX
SG_ PaymentDetails : 12|4@1+ (1,0) [0|15] "" Vector__XXX
SG_ FareValidity : 16|4@1+ (1,0) [0|15] "" Vector__XXX
SG_ PassCategory : 20|4@1+ (1,0) [0|15] "" Vector__XXX
SG_ InitialFareAgency : 24|5@1+ (1,0) [0|31] "" Vector__XXX
SG_ TypeOfService : 32|3@1+ (1,0) [0|7] "" Vector__XXX
SG_ TransferType : 35|5@1+ (1,0) [0|31] "" Vector__XXX
SG_ RouteNumber : 40|12@1+ (1,0) [0|4095] "" Vector__XXX
SG_ TransferSold : 56|8@1+ (1,0) [0|255] "" Vector__XXX

BO_ 2566765822 TR4: 15 Vector__XXX
SG_ FareboxServiceStatus : 0|2@1+ (1,0) [0|3] "" Vector__XXX
SG_ TripStatus : 2|3@1+ (1,0) [0|7] "" Vector__XXX
SG_ TripDirection : 8|4@1+ (1,0) [0|15] "" Vector__XXX
SG_ FarePresets : 16|8@1+ (1,0) [0|255] "" Vector__XXX
SG_ TripNumber : 24|16@1+ (1,0) [0|65535] "" Vector__XXX
SG_ PatternNumber : 40|16@1+ (1,0) [0|65535] "" Vector__XXX
SG_ AssignedRoute : 56|16@1+ (1,0) [0|65535] "" Vector__XXX
SG_ AssignedRun : 72|16@1+ (1,0) [0|65535] "" Vector__XXX
SG_ AssignedBlock : 88|16@1+ (1,0) [0|65535] "" Vector__XXX
SG_ DriversFareboxSecurityCode : 104|16@1+ (1,0) [0|65535] "" Vector__XXX

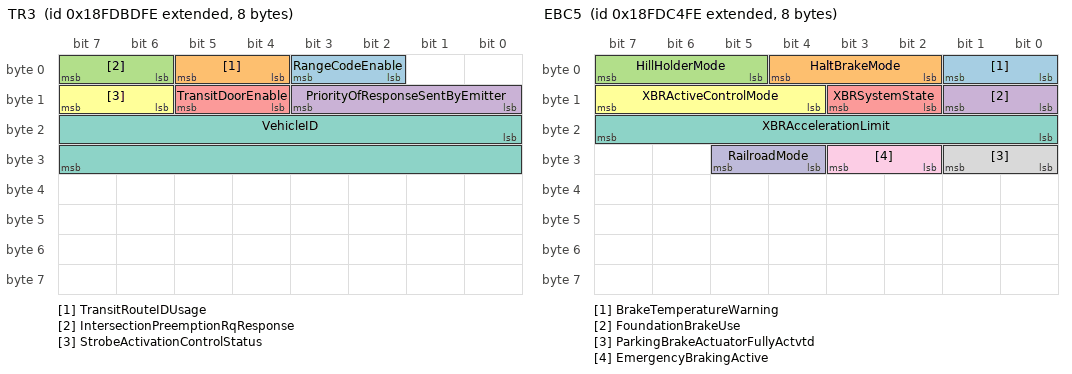
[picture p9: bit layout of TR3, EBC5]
BO_ 2566766078 TR3: 8 Vector__XXX
SG_ RangeCodeEnable : 2|2@1+ (1,0) [0|3] "" Vector__XXX
SG_ TransitRouteIDUsage : 4|2@1+ (1,0) [0|3] "" Vector__XXX
SG_ IntersectionPreemptionRqResponse : 6|2@1+ (1,0) [0|3] "" Vector__XXX
SG_ PriorityOfResponseSentByEmitter : 8|4@1+ (1,0) [0|15] "" Vector__XXX
SG_ TransitDoorEnable : 12|2@1+ (1,0) [0|3] "" Vector__XXX
SG_ StrobeActivationControlStatus : 14|2@1+ (1,0) [0|3] "" Vector__XXX
SG_ VehicleID : 16|16@1+ (1,0) [0|65535] "" Vector__XXX

BO_ 2566766334 TR1: 8 Vector__XXX
SG_ Agency : 0|8@1+ (1,0) [0|255] "" Vector__XXX
SG_ NoOfBytsInTrnstAssgndRteIdntty : 8|8@1+ (1,0) [0|250] "Bytes" Vector__XXX
SG_ NoOfBytsInTrnstAssgndRunIdntty : 16|8@1+ (1,0) [0|250] "Bytes" Vector__XXX
SG_ NoOfBytsInTrnstAssgndBlckIdntty : 24|8@1+ (1,0) [0|250] "Bytes" Vector__XXX

BO_ 2566766590 TR2: 100 Vector__XXX
SG_ NoOfBytsInMilePstIdentification : 0|8@1+ (1,0) [0|250] "Bytes" Vector__XXX
SG_ MilepostIdentification : 7|800@0+ (1,0) [0|0] "ASCII" Vector__XXX

BO_ 2566766846 TR7: 8 Vector__XXX
SG_ TypeOfPassengerCount : 0|8@1+ (1,0) [0|255] "" Vector__XXX
SG_ PatronCount : 8|8@1+ (1,0) [0|250] "" Vector__XXX
SG_ SilentAlarmStatus : 16|2@1+ (1,0) [0|3] "" Vector__XXX
SG_ VehicleUseStatus : 18|2@1+ (1,0) [0|3] "" Vector__XXX
SG_ TransitRunStatus : 20|2@1+ (1,0) [0|3] "" Vector__XXX

BO_ 2566767102 EFL_P3: 8 Vector__XXX
SG_ EngIntkValveActSystemOilPressure : 0|16@1+ (0.00390625,0) [0|250.996] "MPa" Vector__XXX
SG_ EngExhstGasRecirc1IntkPress : 16|8@1+ (2,0) [0|500] "kPa" Vector__XXX
SG_ EngExhstValveActSystemOilPress : 24|16@1+ (0.00390625,0) [0|250.996] "MPa" Vector__XXX
SG_ EngExhstGasRecirc1OtltPress : 40|8@1+ (2,0) [0|500] "kPa" Vector__XXX
SG_ EngineThrottleValve1DiffPressure : 48|16@1+ (0.1,0) [0|6425.5] "kPa" Vector__XXX

BO_ 2566767358 EEC14: 8 Vector__XXX
SG_ EngExhstGasRecirc1Valve1PosError : 0|16@1+ (0.004,-125) [-125|132.02] "%" Vector__XXX
SG_ EngExhstGasRecirc1Valve2PosError : 16|16@1+ (0.004,-125) [-125|132.02] "%" Vector__XXX
SG_ EngineFuelMassFlowRate : 32|16@1+ (0.005,0) [0|321.275] "g/s" Vector__XXX
SG_ FuelType : 48|8@1+ (1,0) [0|255] "" Vector__XXX
SG_ EngineFuelIsolationControl : 56|2@1+ (1,0) [0|3] "" Vector__XXX

BO_ 2566767614 EEC15: 8 Vector__XXX
SG_ AcceleratorPedal1Channel2 : 0|8@1+ (0.4,0) [0|100] "%" Vector__XXX
SG_ AcceleratorPedal1Channel3 : 8|8@1+ (0.4,0) [0|100] "%" Vector__XXX
SG_ AcceleratorPedal2Channel2 : 16|8@1+ (0.4,0) [0|100] "%" Vector__XXX
SG_ AcceleratorPedal2Channel3 : 24|8@1+ (0.4,0) [0|100] "%" Vector__XXX
SG_ EngExhstGasRestrictionValveCtrl : 32|16@1+ (0.0025,0) [0|160.6375] "%" Vector__XXX

BO_ 2566767870 EBC5: 8 Vector__XXX
SG_ BrakeTemperatureWarning : 0|2@1+ (1,0) [0|3] "" Vector__XXX
SG_ HaltBrakeMode : 2|3@1+ (1,0) [0|7] "" Vector__XXX
SG_ HillHolderMode : 5|3@1+ (1,0) [0|7] "" Vector__XXX
SG_ FoundationBrakeUse : 8|2@1+ (1,0) [0|3] "" Vector__XXX
SG_ XBRSystemState : 10|2@1+ (1,0) [0|3] "" Vector__XXX
SG_ XBRActiveControlMode : 12|4@1+ (1,0) [0|15] "" Vector__XXX
SG_ XBRAccelerationLimit : 16|8@1+ (0.1,-12.5) [-12.5|12.5] "m/s^2" Vector__XXX
SG_ ParkingBrakeActuatorFullyActvtd : 24|2@1+ (1,0) [0|3] "" Vector__XXX
SG_ EmergencyBrakingActive : 26|2@1+ (1,0) [0|3] "" Vector__XXX
SG_ RailroadMode : 28|2@1+ (1,0) [0|3] "" Vector__XXX

BO_ 2566768126 ECUID: 200 Vector__XXX
SG_ ECUHardwareID : 7|1600@0+ (1,0) [0|0] "ASCII" Vector__XXX
SG_ ECUDateOfManufacture : 7|1600@0+ (1,0) [0|0] "ASCII" Vector__XXX

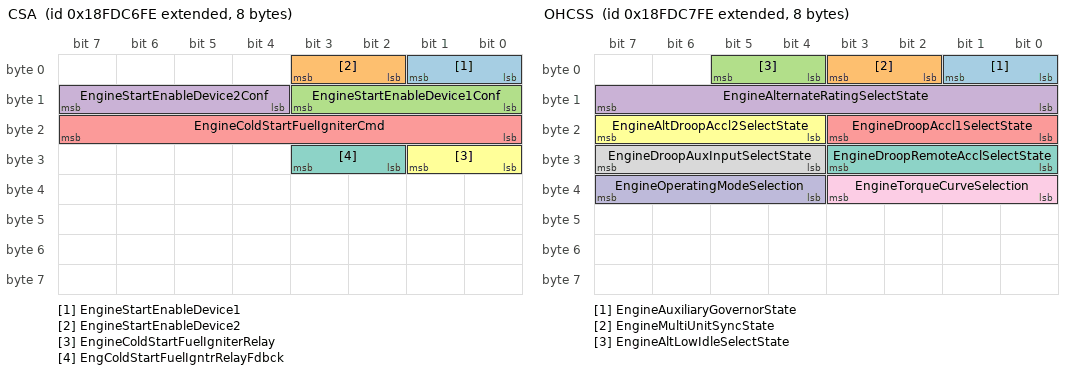
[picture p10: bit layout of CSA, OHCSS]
BO_ 2566768382 CSA: 8 Vector__XXX
SG_ EngineStartEnableDevice1 : 0|2@1+ (1,0) [0|3] "" Vector__XXX
SG_ EngineStartEnableDevice2 : 2|2@1+ (1,0) [0|3] "" Vector__XXX
SG_ EngineStartEnableDevice1Conf : 8|4@1+ (1,0) [0|15] "" Vector__XXX
SG_ EngineStartEnableDevice2Conf : 12|4@1+ (1,0) [0|15] "" Vector__XXX
SG_ EngineColdStartFuelIgniterCmd : 16|8@1+ (0.4,0) [0|100] "%" Vector__XXX
SG_ EngineColdStartFuelIgniterRelay : 24|2@1+ (1,0) [0|3] "" Vector__XXX
SG_ EngColdStartFuelIgntrRelayFdbck : 26|2@1+ (1,0) [0|3] "" Vector__XXX

BO_ 2566768638 OHCSS: 8 Vector__XXX
SG_ EngineAuxiliaryGovernorState : 0|2@1+ (1,0) [0|3] "" Vector__XXX
SG_ EngineMultiUnitSyncState : 2|2@1+ (1,0) [0|3] "" Vector__XXX
SG_ EngineAltLowIdleSelectState : 4|2@1+ (1,0) [0|3] "" Vector__XXX
SG_ EngineAlternateRatingSelectState : 8|8@1+ (1,0) [0|255] "" Vector__XXX
SG_ EngineDroopAccl1SelectState : 16|4@1+ (1,0) [0|15] "" Vector__XXX
SG_ EngineAltDroopAccl2SelectState : 20|4@1+ (1,0) [0|15] "" Vector__XXX
SG_ EngineDroopRemoteAcclSelectState : 24|4@1+ (1,0) [0|15] "" Vector__XXX
SG_ EngineDroopAuxInputSelectState : 28|4@1+ (1,0) [0|15] "" Vector__XXX
SG_ EngineTorqueCurveSelection : 32|4@1+ (1,0) [0|15] "" Vector__XXX
SG_ EngineOperatingModeSelection : 36|4@1+ (1,0) [0|15] "" Vector__XXX

BO_ 2566768894 ISCS: 8 Vector__XXX
SG_ EngOprtrPrmryIntrmedSpdSlctState : 0|4@1+ (1,0) [0|15] "" Vector__XXX

BO_ 2633878014 CMI: 8 Vector__XXX
SG_ TotalCountOfConfChangesMade : 0|16@1+ (1,0) [0|64255] "" Vector__XXX

BO_ 2566769406 ISC: 8 Vector__XXX
SG_ EngOprtrPrmryIntrmedSpeedSelect : 0|4@1+ (1,0) [0|15] "" Vector__XXX

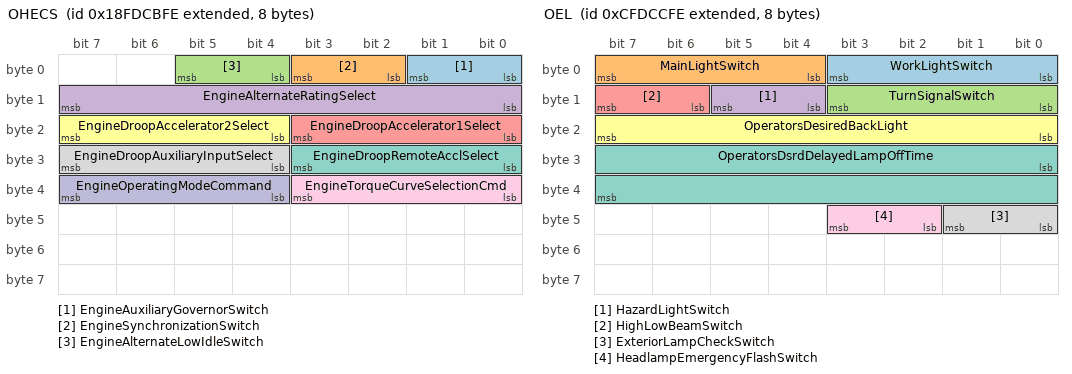
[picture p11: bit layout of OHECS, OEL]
BO_ 2566769662 OHECS: 8 Vector__XXX
SG_ EngineAuxiliaryGovernorSwitch : 0|2@1+ (1,0) [0|3] "" Vector__XXX
SG_ EngineSynchronizationSwitch : 2|2@1+ (1,0) [0|3] "" Vector__XXX
SG_ EngineAlternateLowIdleSwitch : 4|2@1+ (1,0) [0|3] "" Vector__XXX
SG_ EngineAlternateRatingSelect : 8|8@1+ (1,0) [0|255] "" Vector__XXX
SG_ EngineDroopAccelerator1Select : 16|4@1+ (1,0) [0|15] "" Vector__XXX
SG_ EngineDroopAccelerator2Select : 20|4@1+ (1,0) [0|15] "" Vector__XXX
SG_ EngineDroopRemoteAcclSelect : 24|4@1+ (1,0) [0|15] "" Vector__XXX
SG_ EngineDroopAuxiliaryInputSelect : 28|4@1+ (1,0) [0|15] "" Vector__XXX
SG_ EngineTorqueCurveSelectionCmd : 32|4@1+ (1,0) [0|15] "" Vector__XXX
SG_ EngineOperatingModeCommand : 36|4@1+ (1,0) [0|15] "" Vector__XXX

BO_ 2365443326 OEL: 8 Vector__XXX
SG_ WorkLightSwitch : 0|4@1+ (1,0) [0|15] "" Vector__XXX
SG_ MainLightSwitch : 4|4@1+ (1,0) [0|15] "" Vector__XXX
SG_ TurnSignalSwitch : 8|4@1+ (1,0) [0|15] "" Vector__XXX
SG_ HazardLightSwitch : 12|2@1+ (1,0) [0|3] "" Vector__XXX
SG_ HighLowBeamSwitch : 14|2@1+ (1,0) [0|3] "" Vector__XXX
SG_ OperatorsDesiredBackLight : 16|8@1+ (0.4,0) [0|100] "%" Vector__XXX
SG_ OperatorsDsrdDelayedLampOffTime : 24|16@1+ (1,0) [0|64255] "s" Vector__XXX
SG_ ExteriorLampCheckSwitch : 40|2@1+ (1,0) [0|3] "" Vector__XXX
SG_ HeadlampEmergencyFlashSwitch : 42|2@1+ (1,0) [0|3] "" Vector__XXX

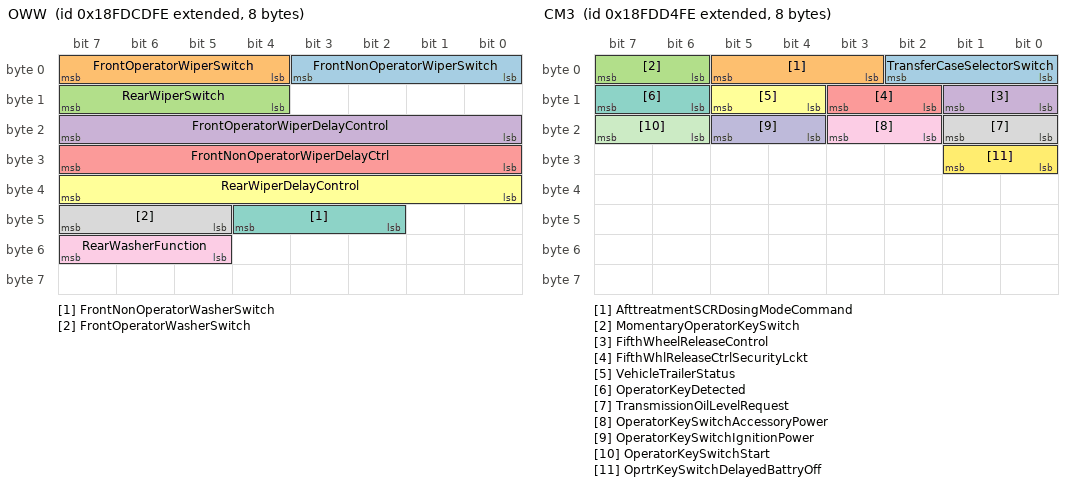
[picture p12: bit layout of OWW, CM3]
BO_ 2566770174 OWW: 8 Vector__XXX
SG_ FrontNonOperatorWiperSwitch : 0|4@1+ (1,0) [0|15] "" Vector__XXX
SG_ FrontOperatorWiperSwitch : 4|4@1+ (1,0) [0|15] "" Vector__XXX
SG_ RearWiperSwitch : 12|4@1+ (1,0) [0|15] "" Vector__XXX
SG_ FrontOperatorWiperDelayControl : 16|8@1+ (0.4,0) [0|100] "%" Vector__XXX
SG_ FrontNonOperatorWiperDelayCtrl : 24|8@1+ (0.4,0) [0|100] "%" Vector__XXX
SG_ RearWiperDelayControl : 32|8@1+ (0.4,0) [0|100] "%" Vector__XXX
SG_ FrontNonOperatorWasherSwitch : 42|3@1+ (1,0) [0|7] "" Vector__XXX
SG_ FrontOperatorWasherSwitch : 45|3@1+ (1,0) [0|7] "" Vector__XXX
SG_ RearWasherFunction : 53|3@1+ (1,0) [0|7] "" Vector__XXX

BO_ 2566770430 WSMM: 8 Vector__XXX
SG_ NAMEOfWorkingSetMember : 0|64@1+ (1,0) [0|1.84467440737096E019] "" Vector__XXX

BO_ 2566770686 WSM: 8 Vector__XXX
SG_ NumberOfMembersInWorkingSet : 0|8@1+ (1,0) [0|250] "" Vector__XXX

BO_ 2566770942 IC2: 8 Vector__XXX
SG_ EngineAirFilter2DiffPressure : 0|8@1+ (0.05,0) [0|12.5] "kPa" Vector__XXX
SG_ EngineAirFilter3DiffPressure : 8|8@1+ (0.05,0) [0|12.5] "kPa" Vector__XXX
SG_ EngineAirFilter4DiffPressure : 16|8@1+ (0.05,0) [0|12.5] "kPa" Vector__XXX
SG_ EngineIntakeManifold2Pressure : 24|8@1+ (2,0) [0|500] "kPa" Vector__XXX
SG_ EngineIntakeManifold1AbsPressure : 32|8@1+ (2,0) [0|500] "kPa" Vector__XXX
SG_ EngineIntkManifld1AbsPressHghRes : 40|16@1+ (0.1,0) [0|6425.5] "kPa" Vector__XXX
SG_ EngineIntakeManifold2AbsPressure : 56|8@1+ (2,0) [0|500] "kPa" Vector__XXX

BO_ 2633880062 FMS: 8 Vector__XXX
SG_ FMSStandardDiagnosticsSupported : 0|2@1+ (1,0) [0|3] "" Vector__XXX
SG_ FMSStandardRequestsSupported : 2|2@1+ (1,0) [0|3] "" Vector__XXX
SG_ FMSStandardSWVersionSupported : 15|32@0+ (1,0) [0|0] "ASCII" Vector__XXX

BO_ 2566771454 EP: 8 Vector__XXX
SG_ KeepAliveBatteryConsumption : 0|16@1+ (1,0) [0|64255] "mAh" Vector__XXX
SG_ DataMemoryUsage : 16|8@1+ (0.4,0) [0|100] "%" Vector__XXX

BO_ 2566771710 TCI6: 8 Vector__XXX
SG_ EngTurbocharger1CmprssorOtltTemp : 0|16@1+ (0.03125,-273) [-273|1734.96875] "deg C" Vector__XXX
SG_ EngTurbocharger2CmprssorOtltTemp : 16|16@1+ (0.03125,-273) [-273|1734.96875] "deg C" Vector__XXX
SG_ EngTurbocharger3CmprssorOtltTemp : 32|16@1+ (0.03125,-273) [-273|1734.96875] "deg C" Vector__XXX
SG_ EngTurbocharger4CmprssorOtltTemp : 48|16@1+ (0.03125,-273) [-273|1734.96875] "deg C" Vector__XXX

BO_ 2566771966 CM3: 8 Vector__XXX
SG_ TransferCaseSelectorSwitch : 0|3@1+ (1,0) [0|7] "" Vector__XXX
SG_ AfttreatmentSCRDosingModeCommand : 3|3@1+ (1,0) [0|7] "" Vector__XXX
SG_ MomentaryOperatorKeySwitch : 6|2@1+ (1,0) [0|3] "" Vector__XXX
SG_ FifthWheelReleaseControl : 8|2@1+ (1,0) [0|3] "" Vector__XXX
SG_ FifthWhlReleaseCtrlSecurityLckt : 10|2@1+ (1,0) [0|3] "" Vector__XXX
SG_ VehicleTrailerStatus : 12|2@1+ (1,0) [0|3] "" Vector__XXX
SG_ OperatorKeyDetected : 14|2@1+ (1,0) [0|3] "" Vector__XXX
SG_ TransmissionOilLevelRequest : 16|2@1+ (1,0) [0|3] "" Vector__XXX
SG_ OperatorKeySwitchAccessoryPower : 18|2@1+ (1,0) [0|3] "" Vector__XXX
SG_ OperatorKeySwitchIgnitionPower : 20|2@1+ (1,0) [0|3] "" Vector__XXX
SG_ OperatorKeySwitchStart : 22|2@1+ (1,0) [0|3] "" Vector__XXX
SG_ OprtrKeySwitchDelayedBattryOff : 24|2@1+ (1,0) [0|3] "" Vector__XXX

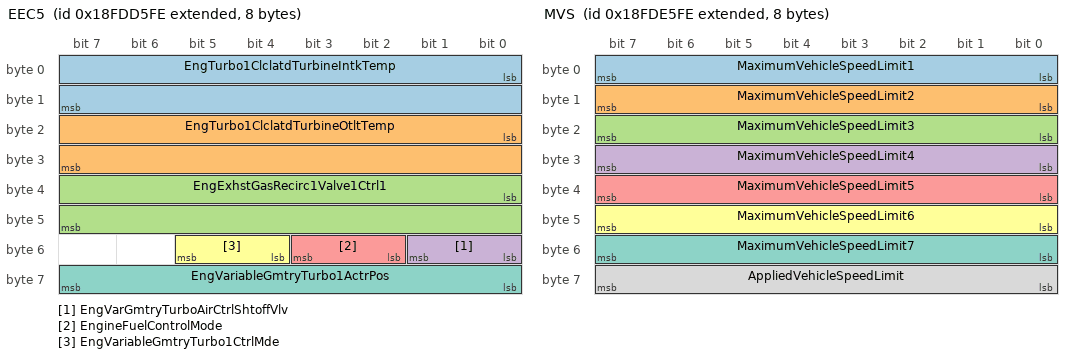
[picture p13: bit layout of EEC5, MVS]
BO_ 2566772222 EEC5: 8 Vector__XXX
SG_ EngTurbo1ClclatdTurbineIntkTemp : 0|16@1+ (0.03125,-273) [-273|1734.96875] "deg C" Vector__XXX
SG_ EngTurbo1ClclatdTurbineOtltTemp : 16|16@1+ (0.03125,-273) [-273|1734.96875] "deg C" Vector__XXX
SG_ EngExhstGasRecirc1Valve1Ctrl1 : 32|16@1+ (0.0025,0) [0|160.6375] "%" Vector__XXX
SG_ EngVarGmtryTurboAirCtrlShtoffVlv : 48|2@1+ (1,0) [0|3] "" Vector__XXX
SG_ EngineFuelControlMode : 50|2@1+ (1,0) [0|3] "" Vector__XXX
SG_ EngVariableGmtryTurbo1CtrlMde : 52|2@1+ (1,0) [0|3] "" Vector__XXX
SG_ EngVariableGmtryTurbo1ActrPos : 56|8@1+ (0.4,0) [0|100] "%" Vector__XXX

BO_ 2365445886 BJM1: 8 Vector__XXX
SG_ Jystck1XAxsNeutralPositionStatus : 0|2@1+ (1,0) [0|3] "" Vector__XXX
SG_ Jystck1XAxsLvrLftNegPosStatus : 2|2@1+ (1,0) [0|3] "" Vector__XXX
SG_ Jystck1XAxsLvrRightPstvPosStatus : 4|2@1+ (1,0) [0|3] "" Vector__XXX
SG_ Joystick1XAxisPosition : 6|10@1+ (0.1,0) [0|102] "%" Vector__XXX
SG_ Jystck1YAxsNeutralPositionStatus : 16|2@1+ (1,0) [0|3] "" Vector__XXX
SG_ Jystck1YAxsLvrBackNegPosStatus : 18|2@1+ (1,0) [0|3] "" Vector__XXX
SG_ Jystck1YAxsLvrFrwdPstvPosStatus : 20|2@1+ (1,0) [0|3] "" Vector__XXX
SG_ Joystick1YAxisPosition : 22|10@1+ (0.1,0) [0|102] "%" Vector__XXX
SG_ Jystck1YAxsDetentPositionStatus : 36|2@1+ (1,0) [0|3] "" Vector__XXX
SG_ Jystck1XAxsDetentPositionStatus : 38|2@1+ (1,0) [0|3] "" Vector__XXX
SG_ Joystick1Button4PressedStatus : 40|2@1+ (1,0) [0|3] "" Vector__XXX
SG_ Joystick1Button3PressedStatus : 42|2@1+ (1,0) [0|3] "" Vector__XXX
SG_ Joystick1Button2PressedStatus : 44|2@1+ (1,0) [0|3] "" Vector__XXX
SG_ Joystick1Button1PressedStatus : 46|2@1+ (1,0) [0|3] "" Vector__XXX
SG_ Joystick1Button8PressedStatus : 48|2@1+ (1,0) [0|3] "" Vector__XXX
SG_ Joystick1Button7PressedStatus : 50|2@1+ (1,0) [0|3] "" Vector__XXX
SG_ Joystick1Button6PressedStatus : 52|2@1+ (1,0) [0|3] "" Vector__XXX
SG_ Joystick1Button5PressedStatus : 54|2@1+ (1,0) [0|3] "" Vector__XXX
SG_ Joystick1Button12PressedStatus : 56|2@1+ (1,0) [0|3] "" Vector__XXX
SG_ Joystick1Button11PressedStatus : 58|2@1+ (1,0) [0|3] "" Vector__XXX
SG_ Joystick1Button10PressedStatus : 60|2@1+ (1,0) [0|3] "" Vector__XXX
SG_ Joystick1Button9PressedStatus : 62|2@1+ (1,0) [0|3] "" Vector__XXX

BO_ 2365446142 EJM1: 8 Vector__XXX
SG_ Jystck1GrpXAxsNtrlPositionStatus : 0|2@1+ (1,0) [0|3] "" Vector__XXX
SG_ Jystck1GrpXAxsLvrLftNegPosStatus : 2|2@1+ (1,0) [0|3] "" Vector__XXX
SG_ Jystck1GrpXAxsLvrRghtPstvPosStat : 4|2@1+ (1,0) [0|3] "" Vector__XXX
SG_ Joystick1GripXAxisPosition : 6|10@1+ (0.1,0) [0|102] "%" Vector__XXX
SG_ Jystck1GrpYAxsNtrlPositionStatus : 16|2@1+ (1,0) [0|3] "" Vector__XXX
SG_ Jystck1GrpYAxsLvrBackNegPosStat : 18|2@1+ (1,0) [0|3] "" Vector__XXX
SG_ Jystck1GrpYAxsLvrFrwdPstvPosStat : 20|2@1+ (1,0) [0|3] "" Vector__XXX
SG_ Joystick1GripYAxisPosition : 22|10@1+ (0.1,0) [0|102] "%" Vector__XXX
SG_ Jystck1ThetaAxsNtrlPosStatus : 32|2@1+ (1,0) [0|3] "" Vector__XXX
SG_ Jystck1ThtAxsCntrClckwsNegPsStat : 34|2@1+ (1,0) [0|3] "" Vector__XXX
SG_ Jystck1ThetaAxsClckwsPstvPosStat : 36|2@1+ (1,0) [0|3] "" Vector__XXX
SG_ Joystick1ThetaAxisPosition : 38|10@1+ (0.1,0) [0|102] "%" Vector__XXX
SG_ Jystck1ThetaAxsDetentPosStatus : 50|2@1+ (1,0) [0|3] "" Vector__XXX
SG_ Jystck1GrpYAxsDetentPosStatus : 52|2@1+ (1,0) [0|3] "" Vector__XXX
SG_ Jystck1GrpXAxsDetentPosStatus : 54|2@1+ (1,0) [0|3] "" Vector__XXX
SG_ Joystick1Button16PressedStatus : 56|2@1+ (1,0) [0|3] "" Vector__XXX
SG_ Joystick1Button15PressedStatus : 58|2@1+ (1,0) [0|3] "" Vector__XXX
SG_ Joystick1Button14PressedStatus : 60|2@1+ (1,0) [0|3] "" Vector__XXX
SG_ Joystick1Button13PressedStatus : 62|2@1+ (1,0) [0|3] "" Vector__XXX

BO_ 2365446398 BJM2: 8 Vector__XXX
SG_ Jystck2XAxsNeutralPositionStatus : 0|2@1+ (1,0) [0|3] "" Vector__XXX
SG_ Jystck2XAxsLvrLftNegPosStatus : 2|2@1+ (1,0) [0|3] "" Vector__XXX
SG_ Jystck2XAxsLvrRightPstvPosStatus : 4|2@1+ (1,0) [0|3] "" Vector__XXX
SG_ Joystick2XAxisPosition : 6|10@1+ (0.1,0) [0|102] "%" Vector__XXX
SG_ Jystck2YAxsNeutralPositionStatus : 16|2@1+ (1,0) [0|3] "" Vector__XXX
SG_ Jystck2YAxsLvrBackNegPosStatus : 18|2@1+ (1,0) [0|3] "" Vector__XXX
SG_ Jystck2YAxsLvrFrwdPstvPosStatus : 20|2@1+ (1,0) [0|3] "" Vector__XXX
SG_ Joystick2YAxisPosition : 22|10@1+ (0.1,0) [0|102] "%" Vector__XXX
SG_ Jystck2YAxsDetentPositionStatus : 36|2@1+ (1,0) [0|3] "" Vector__XXX
SG_ Jystck2XAxsDetentPositionStatus : 38|2@1+ (1,0) [0|3] "" Vector__XXX
SG_ Joystick2Button4PressedStatus : 40|2@1+ (1,0) [0|3] "" Vector__XXX
SG_ Joystick2Button3PressedStatus : 42|2@1+ (1,0) [0|3] "" Vector__XXX
SG_ Joystick2Button2PressedStatus : 44|2@1+ (1,0) [0|3] "" Vector__XXX
SG_ Joystick2Button1PressedStatus : 46|2@1+ (1,0) [0|3] "" Vector__XXX
SG_ Joystick2Button8PressedStatus : 48|2@1+ (1,0) [0|3] "" Vector__XXX
SG_ Joystick2Button7PressedStatus : 50|2@1+ (1,0) [0|3] "" Vector__XXX
SG_ Joystick2Button6PressedStatus : 52|2@1+ (1,0) [0|3] "" Vector__XXX
SG_ Joystick2Button5PressedStatus : 54|2@1+ (1,0) [0|3] "" Vector__XXX
SG_ Joystick2Button12PressedStatus : 56|2@1+ (1,0) [0|3] "" Vector__XXX
SG_ Joystick2Button11PressedStatus : 58|2@1+ (1,0) [0|3] "" Vector__XXX
SG_ Joystick2Button10PressedStatus : 60|2@1+ (1,0) [0|3] "" Vector__XXX
SG_ Joystick2Button9PressedStatus : 62|2@1+ (1,0) [0|3] "" Vector__XXX

BO_ 2365446654 EJM2: 8 Vector__XXX
SG_ Jystck2GrpXAxsNtrlPositionStatus : 0|2@1+ (1,0) [0|3] "" Vector__XXX
SG_ Jystck2GrpXAxsLvrLftNegPosStatus : 2|2@1+ (1,0) [0|3] "" Vector__XXX
SG_ Jystck2GrpXAxsLvrRghtPstvPosStat : 4|2@1+ (1,0) [0|3] "" Vector__XXX
SG_ Joystick2GripXAxisPosition : 6|10@1+ (0.1,0) [0|102] "%" Vector__XXX
SG_ Jystck2GrpYAxsNtrlPositionStatus : 16|2@1+ (1,0) [0|3] "" Vector__XXX
SG_ Jystck2GrpYAxsLvrBackNegPosStat : 18|2@1+ (1,0) [0|3] "" Vector__XXX
SG_ Jystck2GrpYAxsLvrFrwdPstvPosStat : 20|2@1+ (1,0) [0|3] "" Vector__XXX
SG_ Joystick2GripYAxisPosition : 22|10@1+ (0.1,0) [0|102] "%" Vector__XXX
SG_ Jystck2ThetaAxsNtrlPosStatus : 32|2@1+ (1,0) [0|3] "" Vector__XXX
SG_ Jystck2ThtAxsCntrClckwsNegPsStat : 34|2@1+ (1,0) [0|3] "" Vector__XXX
SG_ Jystck2ThetaAxsClckwsPstvPosStat : 36|2@1+ (1,0) [0|3] "" Vector__XXX
SG_ Joystick2ThetaAxisPosition : 38|10@1+ (0.1,0) [0|102] "%" Vector__XXX
SG_ Jystck2ThetaAxsDetentPosStatus : 50|2@1+ (1,0) [0|3] "" Vector__XXX
SG_ Jystck2GrpYAxsDetentPosStatus : 52|2@1+ (1,0) [0|3] "" Vector__XXX
SG_ Jystck2GrpXAxsDetentPosStatus : 54|2@1+ (1,0) [0|3] "" Vector__XXX
SG_ Joystick2Button16PressedStatus : 56|2@1+ (1,0) [0|3] "" Vector__XXX
SG_ Joystick2Button15PressedStatus : 58|2@1+ (1,0) [0|3] "" Vector__XXX
SG_ Joystick2Button14PressedStatus : 60|2@1+ (1,0) [0|3] "" Vector__XXX
SG_ Joystick2Button13PressedStatus : 62|2@1+ (1,0) [0|3] "" Vector__XXX

BO_ 2365446910 BJM3: 8 Vector__XXX
SG_ Jystck3XAxsNeutralPositionStatus : 0|2@1+ (1,0) [0|3] "" Vector__XXX
SG_ Jystck3XAxsLvrLftNegPosStatus : 2|2@1+ (1,0) [0|3] "" Vector__XXX
SG_ Jystck3XAxsLvrRightPstvPosStatus : 4|2@1+ (1,0) [0|3] "" Vector__XXX
SG_ Joystick3XAxisPosition : 6|10@1+ (0.1,0) [0|102] "%" Vector__XXX
SG_ Jystck3YAxsNeutralPositionStatus : 16|2@1+ (1,0) [0|3] "" Vector__XXX
SG_ Jystck3YAxsLvrBackNegPosStatus : 18|2@1+ (1,0) [0|3] "" Vector__XXX
SG_ Jystck3YAxsLvrFrwdPstvPosStatus : 20|2@1+ (1,0) [0|3] "" Vector__XXX
SG_ Joystick3YAxisPosition : 22|10@1+ (0.1,0) [0|102] "%" Vector__XXX
SG_ Jystck3YAxsDetentPositionStatus : 36|2@1+ (1,0) [0|3] "" Vector__XXX
SG_ Jystck3XAxsDetentPositionStatus : 38|2@1+ (1,0) [0|3] "" Vector__XXX
SG_ Joystick3Button4PressedStatus : 40|2@1+ (1,0) [0|3] "" Vector__XXX
SG_ Joystick3Button3PressedStatus : 42|2@1+ (1,0) [0|3] "" Vector__XXX
SG_ Joystick3Button2PressedStatus : 44|2@1+ (1,0) [0|3] "" Vector__XXX
SG_ Joystick3Button1PressedStatus : 46|2@1+ (1,0) [0|3] "" Vector__XXX
SG_ Joystick3Button8PressedStatus : 48|2@1+ (1,0) [0|3] "" Vector__XXX
SG_ Joystick3Button7PressedStatus : 50|2@1+ (1,0) [0|3] "" Vector__XXX
SG_ Joystick3Button6PressedStatus : 52|2@1+ (1,0) [0|3] "" Vector__XXX
SG_ Joystick3Button5PressedStatus : 54|2@1+ (1,0) [0|3] "" Vector__XXX
SG_ Joystick3Button12PressedStatus : 56|2@1+ (1,0) [0|3] "" Vector__XXX
SG_ Joystick3Button11PressedStatus : 58|2@1+ (1,0) [0|3] "" Vector__XXX
SG_ Joystick3Button10PressedStatus : 60|2@1+ (1,0) [0|3] "" Vector__XXX
SG_ Joystick3Button9PressedStatus : 62|2@1+ (1,0) [0|3] "" Vector__XXX

BO_ 2365447166 EJM3: 8 Vector__XXX
SG_ Jystck3GrpXAxsNtrlPositionStatus : 0|2@1+ (1,0) [0|3] "" Vector__XXX
SG_ Jystck3GrpXAxsLvrLftNegPosStatus : 2|2@1+ (1,0) [0|3] "" Vector__XXX
SG_ Jystck3GrpXAxsLvrRghtPstvPosStat : 4|2@1+ (1,0) [0|3] "" Vector__XXX
SG_ Joystick3GripXAxisPosition : 6|10@1+ (0.1,0) [0|102] "%" Vector__XXX
SG_ Jystck3GrpYAxsNtrlPositionStatus : 16|2@1+ (1,0) [0|3] "" Vector__XXX
SG_ Jystck3GrpYAxsLvrBackNegPosStat : 18|2@1+ (1,0) [0|3] "" Vector__XXX
SG_ Jystck3GrpYAxsLvrFrwdPstvPosStat : 20|2@1+ (1,0) [0|3] "" Vector__XXX
SG_ Joystick3GripYAxisPosition : 22|10@1+ (0.1,0) [0|102] "%" Vector__XXX
SG_ Jystck3ThetaAxsNtrlPosStatus : 32|2@1+ (1,0) [0|3] "" Vector__XXX
SG_ Jystck3ThtAxsCntrClckwsNegPsStat : 34|2@1+ (1,0) [0|3] "" Vector__XXX
SG_ Jystck3ThetaAxsClckwsPstvPosStat : 36|2@1+ (1,0) [0|3] "" Vector__XXX
SG_ Joystick3ThetaAxisPosition : 38|10@1+ (0.1,0) [0|102] "%" Vector__XXX
SG_ Jystck3ThetaAxsDetentPosStatus : 50|2@1+ (1,0) [0|3] "" Vector__XXX
SG_ Jystck3GrpYAxsDetentPosStatus : 52|2@1+ (1,0) [0|3] "" Vector__XXX
SG_ Jystck3GrpXAxsDetentPosStatus : 54|2@1+ (1,0) [0|3] "" Vector__XXX
SG_ Joystick3Button16PressedStatus : 56|2@1+ (1,0) [0|3] "" Vector__XXX
SG_ Joystick3Button15PressedStatus : 58|2@1+ (1,0) [0|3] "" Vector__XXX
SG_ Joystick3Button14PressedStatus : 60|2@1+ (1,0) [0|3] "" Vector__XXX
SG_ Joystick3Button13PressedStatus : 62|2@1+ (1,0) [0|3] "" Vector__XXX

BO_ 2566774014 MCI: 8 Vector__XXX
SG_ EngThrottleSyncMdeStat : 0|4@1+ (1,0) [0|15] "" Vector__XXX
SG_ TrollingModeStatus : 4|2@1+ (1,0) [0|3] "" Vector__XXX
SG_ SlowVesselModeStatus : 6|2@1+ (1,0) [0|3] "" Vector__XXX
SG_ EngineMarineOperatingModeStatus : 8|3@1+ (1,0) [0|7] "" Vector__XXX

BO_ 2633883646 FWD: 8 Vector__XXX
SG_ FrontWheelDriveActuatorStatus : 0|2@1+ (1,0) [0|3] "" Vector__XXX

BO_ 2566775038 AMB2: 8 Vector__XXX
SG_ SolarIntensityPercent : 0|8@1+ (0.4,0) [0|100] "%" Vector__XXX
SG_ SolarSensorMaximum : 8|8@1+ (0.4,0) [0|100] "mW/cm^2" Vector__XXX
SG_ SpecificHumidity : 16|16@1+ (0.01,0) [0|642.55] "g/kg" Vector__XXX
SG_ CalculatedAmbientAirTemperature : 32|16@1+ (0.03125,-273) [-273|1734.96875] "deg C" Vector__XXX
SG_ BarometricAbsolutePressure : 48|16@1+ (0.1,0) [0|6425.5] "kPa" Vector__XXX

BO_ 2566775294 CCSI1: 8 Vector__XXX
SG_ CabACRefrigCmprssorOtltPress : 0|8@1+ (16,0) [0|4000] "kPa" Vector__XXX
SG_ AirConditionerCompressorStatus : 8|2@1+ (1,0) [0|3] "" Vector__XXX

BO_ 2566775550 SPR: 8 Vector__XXX
SG_ PneumaticSupplyPressureRequest : 0|8@1+ (8,0) [0|2000] "kPa" Vector__XXX
SG_ PrkAndOrTrailerAirPressRequest : 8|8@1+ (8,0) [0|2000] "kPa" Vector__XXX
SG_ ServiceBrkAirPressRq_Circuit1 : 16|8@1+ (8,0) [0|2000] "kPa" Vector__XXX
SG_ ServiceBrkAirPressRq_Circuit2 : 24|8@1+ (8,0) [0|2000] "kPa" Vector__XXX
SG_ AuxEquipmentSupplyPressRequest : 32|8@1+ (8,0) [0|2000] "kPa" Vector__XXX
SG_ AirSuspensionSupplyPressRequest : 40|8@1+ (8,0) [0|2000] "kPa" Vector__XXX
SG_ PwrtrainCircuitAirSupplyPressRq : 48|8@1+ (8,0) [0|2000] "kPa" Vector__XXX

BO_ 2566775806 EOAC: 8 Vector__XXX
SG_ TravelVelocityControlPosition : 0|8@1+ (1,-125) [-125|125] "%" Vector__XXX

BO_ 2566776062 EPD: 8 Vector__XXX
SG_ PayloadPercentage : 0|8@1+ (1,0) [0|250] "%" Vector__XXX
SG_ PayloadWeight : 8|24@1+ (2,0) [0|32899070] "kg" Vector__XXX
SG_ PayloadWeightConfidence : 32|8@1+ (0.5,0) [0|125] "%" Vector__XXX
SG_ PayloadCarryBackWeight : 40|16@1+ (2,0) [0|128510] "kg" Vector__XXX
SG_ PayloadCapacityPercentage : 56|8@1+ (1,0) [0|250] "%" Vector__XXX

BO_ 2566776318 MVS: 8 Vector__XXX
SG_ MaximumVehicleSpeedLimit1 : 0|8@1+ (1,0) [0|250] "km/h" Vector__XXX
SG_ MaximumVehicleSpeedLimit2 : 8|8@1+ (1,0) [0|250] "km/h" Vector__XXX
SG_ MaximumVehicleSpeedLimit3 : 16|8@1+ (1,0) [0|250] "km/h" Vector__XXX
SG_ MaximumVehicleSpeedLimit4 : 24|8@1+ (1,0) [0|250] "km/h" Vector__XXX
SG_ MaximumVehicleSpeedLimit5 : 32|8@1+ (1,0) [0|250] "km/h" Vector__XXX
SG_ MaximumVehicleSpeedLimit6 : 40|8@1+ (1,0) [0|250] "km/h" Vector__XXX
SG_ MaximumVehicleSpeedLimit7 : 48|8@1+ (1,0) [0|250] "km/h" Vector__XXX
SG_ AppliedVehicleSpeedLimit : 56|8@1+ (1,0) [0|250] "km/h" Vector__XXX

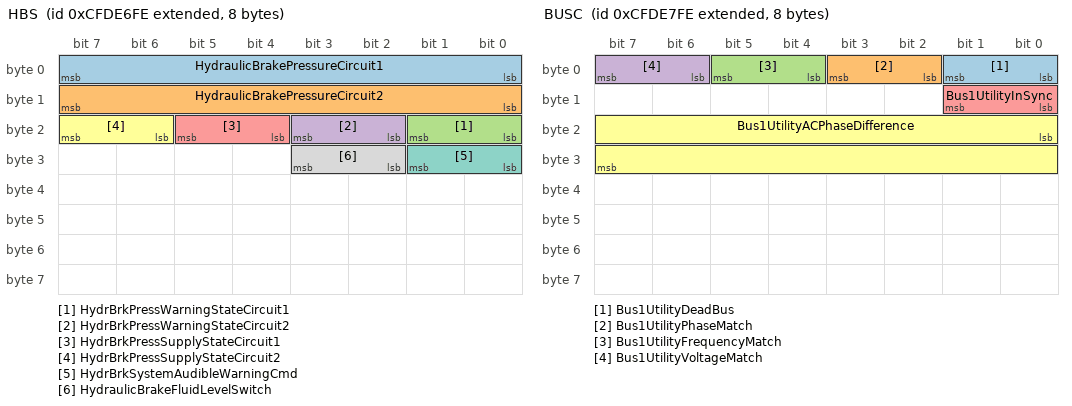
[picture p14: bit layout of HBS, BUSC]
BO_ 2365449982 HBS: 8 Vector__XXX
SG_ HydraulicBrakePressureCircuit1 : 0|8@1+ (100,0) [0|25000] "kPa" Vector__XXX
SG_ HydraulicBrakePressureCircuit2 : 8|8@1+ (100,0) [0|25000] "kPa" Vector__XXX
SG_ HydrBrkPressWarningStateCircuit1 : 16|2@1+ (1,0) [0|3] "" Vector__XXX
SG_ HydrBrkPressWarningStateCircuit2 : 18|2@1+ (1,0) [0|3] "" Vector__XXX
SG_ HydrBrkPressSupplyStateCircuit1 : 20|2@1+ (1,0) [0|3] "" Vector__XXX
SG_ HydrBrkPressSupplyStateCircuit2 : 22|2@1+ (1,0) [0|3] "" Vector__XXX
SG_ HydrBrkSystemAudibleWarningCmd : 24|2@1+ (1,0) [0|3] "" Vector__XXX
SG_ HydraulicBrakeFluidLevelSwitch : 26|2@1+ (1,0) [0|3] "" Vector__XXX

BO_ 2365450238 BUSC: 8 Vector__XXX
SG_ Bus1UtilityDeadBus : 0|2@1+ (1,0) [0|3] "" Vector__XXX
SG_ Bus1UtilityPhaseMatch : 2|2@1+ (1,0) [0|3] "" Vector__XXX
SG_ Bus1UtilityFrequencyMatch : 4|2@1+ (1,0) [0|3] "" Vector__XXX
SG_ Bus1UtilityVoltageMatch : 6|2@1+ (1,0) [0|3] "" Vector__XXX
SG_ Bus1UtilityInSync : 8|2@1+ (1,0) [0|3] "" Vector__XXX
SG_ Bus1UtilityACPhaseDifference : 16|16@1+ (0.0078125,-200) [-200|301.99] "deg" Vector__XXX

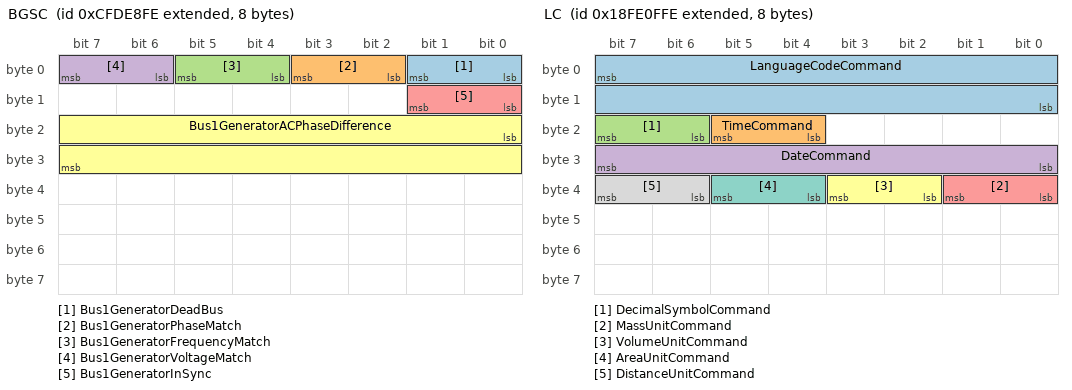
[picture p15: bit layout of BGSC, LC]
BO_ 2365450494 BGSC: 8 Vector__XXX
SG_ Bus1GeneratorDeadBus : 0|2@1+ (1,0) [0|3] "" Vector__XXX
SG_ Bus1GeneratorPhaseMatch : 2|2@1+ (1,0) [0|3] "" Vector__XXX
SG_ Bus1GeneratorFrequencyMatch : 4|2@1+ (1,0) [0|3] "" Vector__XXX
SG_ Bus1GeneratorVoltageMatch : 6|2@1+ (1,0) [0|3] "" Vector__XXX
SG_ Bus1GeneratorInSync : 8|2@1+ (1,0) [0|3] "" Vector__XXX
SG_ Bus1GeneratorACPhaseDifference : 16|16@1+ (0.0078125,-200) [-200|301.99] "deg" Vector__XXX

BO_ 2365450750 BPCAC: 8 Vector__XXX
SG_ Bus1PhaseCALineLineACRMSVoltage : 0|16@1+ (1,0) [0|64255] "V" Vector__XXX
SG_ Bus1PhaseCLineNtrlACRMSVoltage : 16|16@1+ (1,0) [0|64255] "V" Vector__XXX
SG_ Bus1PhaseCACFrequency : 32|16@1+ (0.0078125,0) [0|501.9921875] "Hz" Vector__XXX

BO_ 2365451006 BPBAC: 8 Vector__XXX
SG_ Bus1PhaseBCLineLineACRMSVoltage : 0|16@1+ (1,0) [0|64255] "V" Vector__XXX
SG_ Bus1PhaseBLineNtrlACRMSVoltage : 16|16@1+ (1,0) [0|64255] "V" Vector__XXX
SG_ Bus1PhaseBACFrequency : 32|16@1+ (0.0078125,0) [0|501.9921875] "Hz" Vector__XXX

BO_ 2365451262 BPAAC: 8 Vector__XXX
SG_ Bus1PhaseABLineLineACRMSVoltage : 0|16@1+ (1,0) [0|64255] "V" Vector__XXX
SG_ Bus1PhaseALineNtrlACRMSVoltage : 16|16@1+ (1,0) [0|64255] "V" Vector__XXX
SG_ Bus1PhaseAACFrequency : 32|16@1+ (0.0078125,0) [0|501.9921875] "Hz" Vector__XXX

BO_ 2365451518 BAAC: 8 Vector__XXX
SG_ Bus1AverageLineLineACRMSVoltage : 0|16@1+ (1,0) [0|64255] "V" Vector__XXX
SG_ Bus1AvrgLineNeutralACRMSVoltage : 16|16@1+ (1,0) [0|64255] "V" Vector__XXX
SG_ Bus1AverageACFrequency : 32|16@1+ (0.0078125,0) [0|501.9921875] "Hz" Vector__XXX

BO_ 2365451774 UTACE: 8 Vector__XXX
SG_ UtilityTotalKWHoursExport : 0|32@1+ (1,0) [0|4211081215] "kWh" Vector__XXX
SG_ UtilityTotalKWHoursImport : 32|32@1+ (1,0) [0|4211081215] "kWh" Vector__XXX

BO_ 2365452030 UPCACR: 8 Vector__XXX
SG_ UtilityPhaseCReactivePower : 0|32@1+ (1,-2000000000) [-2000000000|2211081215] "VAr" Vector__XXX
SG_ UtilityPhaseCPowerFactor : 32|16@1+ (6.103515625E-005,-1) [-1|2.921814] "" Vector__XXX
SG_ UtilityPhaseCPowerFactorLagging : 48|2@1+ (1,0) [0|3] "" Vector__XXX

BO_ 2365452286 UPCACP: 8 Vector__XXX
SG_ UtilityPhaseCRealPower : 0|32@1+ (1,-2000000000) [-2000000000|2211081215] "W" Vector__XXX
SG_ UtilityPhaseCApparentPower : 32|32@1+ (1,-2000000000) [-2000000000|2211081215] "VA" Vector__XXX

BO_ 2365452542 UPCAC: 8 Vector__XXX
SG_ UtilityPhaseCALineLineACRMSVltg : 0|16@1+ (1,0) [0|64255] "V" Vector__XXX
SG_ UtilityPhaseCLineNtrlACRMSVltg : 16|16@1+ (1,0) [0|64255] "V" Vector__XXX
SG_ UtilityPhaseCACFrequency : 32|16@1+ (0.0078125,0) [0|501.9921875] "Hz" Vector__XXX
SG_ UtilityPhaseCACRMSCurrent : 48|16@1+ (1,0) [0|64255] "A" Vector__XXX

BO_ 2365452798 UPBACR: 8 Vector__XXX
SG_ UtilityPhaseBReactivePower : 0|32@1+ (1,-2000000000) [-2000000000|2211081215] "VAr" Vector__XXX
SG_ UtilityPhaseBPowerFactor : 32|16@1+ (6.103515625E-005,-1) [-1|2.921814] "" Vector__XXX
SG_ UtilityPhaseBPowerFactorLagging : 48|2@1+ (1,0) [0|3] "" Vector__XXX

BO_ 2365453054 UPBACP: 8 Vector__XXX
SG_ UtilityPhaseBRealPower : 0|32@1+ (1,-2000000000) [-2000000000|2211081215] "W" Vector__XXX
SG_ UtilityPhaseBApparentPower : 32|32@1+ (1,-2000000000) [-2000000000|2211081215] "VA" Vector__XXX

BO_ 2365453310 UPBAC: 8 Vector__XXX
SG_ UtilityPhaseBCLineLineACRMSVltg : 0|16@1+ (1,0) [0|64255] "V" Vector__XXX
SG_ UtilityPhaseBLineNtrlACRMSVltg : 16|16@1+ (1,0) [0|64255] "V" Vector__XXX
SG_ UtilityPhaseBACFrequency : 32|16@1+ (0.0078125,0) [0|501.9921875] "Hz" Vector__XXX
SG_ UtilityPhaseBACRMSCurrent : 48|16@1+ (1,0) [0|64255] "A" Vector__XXX

BO_ 2365453566 UPACCR: 8 Vector__XXX
SG_ UtilityPhaseAReactivePower : 0|32@1+ (1,-2000000000) [-2000000000|2211081215] "VAr" Vector__XXX
SG_ UtilityPhaseAPowerFactor : 32|16@1+ (6.103515625E-005,-1) [-1|2.921814] "" Vector__XXX
SG_ UtilityPhaseAPowerFactorLagging : 48|2@1+ (1,0) [0|3] "" Vector__XXX

BO_ 2365453822 UPAACP: 8 Vector__XXX
SG_ UtilityPhaseARealPower : 0|32@1+ (1,-2000000000) [-2000000000|2211081215] "W" Vector__XXX
SG_ UtilityPhaseAApparentPower : 32|32@1+ (1,-2000000000) [-2000000000|2211081215] "VA" Vector__XXX

BO_ 2365454078 UPAAC: 8 Vector__XXX
SG_ UtilityPhaseABLineLineACRMSVltg : 0|16@1+ (1,0) [0|64255] "V" Vector__XXX
SG_ UtilityPhaseALineNtrlACRMSVltg : 16|16@1+ (1,0) [0|64255] "V" Vector__XXX
SG_ UtilityPhaseAACFrequency : 32|16@1+ (0.0078125,0) [0|501.9921875] "Hz" Vector__XXX
SG_ UtilityPhaseAACRMSCurrent : 48|16@1+ (1,0) [0|64255] "A" Vector__XXX

BO_ 2365454334 UTACR: 8 Vector__XXX
SG_ UtilityTotalReactivePower : 0|32@1+ (1,-2000000000) [-2000000000|2211081215] "VAr" Vector__XXX
SG_ UtilityOverallPowerFactor : 32|16@1+ (6.103515625E-005,-1) [-1|2.921814] "" Vector__XXX
SG_ UtilityOverallPowerFactorLagging : 48|2@1+ (1,0) [0|3] "" Vector__XXX

BO_ 2365454590 UTACP: 8 Vector__XXX
SG_ UtilityTotalRealPower : 0|32@1+ (1,-2000000000) [-2000000000|2211081215] "W" Vector__XXX
SG_ UtilityTotalApparentPower : 32|32@1+ (1,-2000000000) [-2000000000|2211081215] "VA" Vector__XXX

BO_ 2365454846 UAAC: 8 Vector__XXX
SG_ UtilityAvrgLineLineACRMSVoltage : 0|16@1+ (1,0) [0|64255] "V" Vector__XXX
SG_ UtilityAvrgLineNtrlACRMSVoltage : 16|16@1+ (1,0) [0|64255] "V" Vector__XXX
SG_ UtilityAverageACFrequency : 32|16@1+ (0.0078125,0) [0|501.9921875] "Hz" Vector__XXX
SG_ UtilityAverageACRMSCurrent : 48|16@1+ (1,0) [0|64255] "A" Vector__XXX

BO_ 2365455102 GTACE: 8 Vector__XXX
SG_ GeneratorTotalKWHoursExport : 0|32@1+ (1,0) [0|4211081215] "kWh" Vector__XXX
SG_ GeneratorTotalKWHoursImport : 32|32@1+ (1,0) [0|4211081215] "kWh" Vector__XXX

BO_ 2365455358 GPCACR: 8 Vector__XXX
SG_ GeneratorPhaseCReactivePower : 0|32@1+ (1,-2000000000) [-2000000000|2211081215] "VAr" Vector__XXX
SG_ GeneratorPhaseCPowerFactor : 32|16@1+ (6.103515625E-005,-1) [-1|2.921814] "" Vector__XXX
SG_ GenPhaseCPowerFactorLagging : 48|2@1+ (1,0) [0|3] "" Vector__XXX

BO_ 2365455614 GPCACP: 8 Vector__XXX
SG_ GeneratorPhaseCRealPower : 0|32@1+ (1,-2000000000) [-2000000000|2211081215] "W" Vector__XXX
SG_ GeneratorPhaseCApparentPower : 32|32@1+ (1,-2000000000) [-2000000000|2211081215] "VA" Vector__XXX

BO_ 2365455870 GPCAC: 8 Vector__XXX
SG_ GenPhaseCALineLineACRMSVoltage : 0|16@1+ (1,0) [0|64255] "V" Vector__XXX
SG_ GenPhaseCLineNeutralACRMSVoltage : 16|16@1+ (1,0) [0|64255] "V" Vector__XXX
SG_ GeneratorPhaseCACFrequency : 32|16@1+ (0.0078125,0) [0|501.9921875] "Hz" Vector__XXX
SG_ GeneratorPhaseCACRMSCurrent : 48|16@1+ (1,0) [0|64255] "A" Vector__XXX

BO_ 2365456126 GPBACRP: 8 Vector__XXX
SG_ GeneratorPhaseBReactivePower : 0|32@1+ (1,-2000000000) [-2000000000|2211081215] "VAr" Vector__XXX
SG_ GeneratorPhaseBPowerFactor : 32|16@1+ (6.103515625E-005,-1) [-1|2.921814] "" Vector__XXX
SG_ GenPhaseBPowerFactorLagging : 48|2@1+ (1,0) [0|3] "" Vector__XXX

BO_ 2365456382 GPBACP: 8 Vector__XXX
SG_ GeneratorPhaseBRealPower : 0|32@1+ (1,-2000000000) [-2000000000|2211081215] "W" Vector__XXX
SG_ GeneratorPhaseBApparentPower : 32|32@1+ (1,-2000000000) [-2000000000|2211081215] "VA" Vector__XXX

BO_ 2365456638 GPBAC: 8 Vector__XXX
SG_ GenPhaseBCLineLineACRMSVoltage : 0|16@1+ (1,0) [0|64255] "V" Vector__XXX
SG_ GenPhaseBLineNeutralACRMSVoltage : 16|16@1+ (1,0) [0|64255] "V" Vector__XXX
SG_ GeneratorPhaseBACFrequency : 32|16@1+ (0.0078125,0) [0|501.9921875] "Hz" Vector__XXX
SG_ GeneratorPhaseBACRMSCurrent : 48|16@1+ (1,0) [0|64255] "A" Vector__XXX

BO_ 2365456894 GPAACR: 8 Vector__XXX
SG_ GeneratorPhaseAReactivePower : 0|32@1+ (1,-2000000000) [-2000000000|2211081215] "VAr" Vector__XXX
SG_ GeneratorPhaseAPowerFactor : 32|16@1+ (6.103515625E-005,-1) [-1|2.921814] "" Vector__XXX
SG_ GenPhaseAPowerFactorLagging : 48|2@1+ (1,0) [0|3] "" Vector__XXX

BO_ 2365457150 GPAACP: 8 Vector__XXX
SG_ GeneratorPhaseARealPower : 0|32@1+ (1,-2000000000) [-2000000000|2211081215] "W" Vector__XXX
SG_ GeneratorPhaseAApparentPower : 32|32@1+ (1,-2000000000) [-2000000000|2211081215] "VA" Vector__XXX

BO_ 2365457406 GPAAC: 8 Vector__XXX
SG_ GenPhaseABLineLineACRMSVoltage : 0|16@1+ (1,0) [0|64255] "V" Vector__XXX
SG_ GenPhaseALineNeutralACRMSVoltage : 16|16@1+ (1,0) [0|64255] "V" Vector__XXX
SG_ GeneratorPhaseAACFrequency : 32|16@1+ (0.0078125,0) [0|501.9921875] "Hz" Vector__XXX
SG_ GeneratorPhaseAACRMSCurrent : 48|16@1+ (1,0) [0|64255] "A" Vector__XXX

BO_ 2365457662 GTACR: 8 Vector__XXX
SG_ GeneratorTotalReactivePower : 0|32@1+ (1,-2000000000) [-2000000000|2211081215] "VAr" Vector__XXX
SG_ GeneratorOverallPowerFactor : 32|16@1+ (6.103515625E-005,-1) [-1|2.921814] "" Vector__XXX
SG_ GenOverallPowerFactorLagging : 48|2@1+ (1,0) [0|3] "" Vector__XXX

BO_ 2365457918 GTACP: 8 Vector__XXX
SG_ GeneratorTotalRealPower : 0|32@1+ (1,-2000000000) [-2000000000|2211081215] "W" Vector__XXX
SG_ GeneratorTotalApparentPower : 32|32@1+ (1,-2000000000) [-2000000000|2211081215] "VA" Vector__XXX

BO_ 2365458174 GAAC: 8 Vector__XXX
SG_ GenAvrgLineLineACRMSVoltage : 0|16@1+ (1,0) [0|64255] "V" Vector__XXX
SG_ GenAvrgLineNeutralACRMSVoltage : 16|16@1+ (1,0) [0|64255] "V" Vector__XXX
SG_ GeneratorAverageACFrequency : 32|16@1+ (0.0078125,0) [0|501.9921875] "Hz" Vector__XXX
SG_ GeneratorAverageACRMSCurrent : 48|16@1+ (1,0) [0|64255] "A" Vector__XXX

BO_ 2566785022 ET: 8 Vector__XXX
SG_ EngExhstManifoldBnk2Temperature1 : 0|16@1+ (0.03125,-273) [-273|1734.96875] "deg C" Vector__XXX
SG_ EngExhstManifoldBnk1Temperature1 : 16|16@1+ (0.03125,-273) [-273|1734.96875] "deg C" Vector__XXX
SG_ EngExhstManifoldBnk2Temperature2 : 32|16@1+ (0.03125,-273) [-273|1734.96875] "deg C" Vector__XXX
SG_ EngExhstManifoldBnk1Temperature2 : 48|16@1+ (0.03125,-273) [-273|1734.96875] "deg C" Vector__XXX

BO_ 2566785278 RTF: 0 Vector__XXX

BO_ 2566785534 TFR: 0 Vector__XXX

BO_ 2566785790 IRCR: 0 Vector__XXX

BO_ 2566786046 IRC: 0 Vector__XXX

BO_ 2566786302 WSMEM: 0 Vector__XXX

BO_ 2566786558 WSMSTR: 8 Vector__XXX
SG_ NumberOfMembersInWorkingSet : 0|8@1+ (1,0) [0|250] "" Vector__XXX

BO_ 2566786814 RESRR: 8 Vector__XXX
SG_ RepetitionRateParameter : 24|16@1+ (1,0) [0|64.255] "ms" Vector__XXX

BO_ 2566787070 LC: 8 Vector__XXX
SG_ LanguageCodeCommand : 7|16@0+ (1,0) [0|0] "ASCII" Vector__XXX
SG_ TimeCommand : 20|2@1+ (1,0) [0|3] "" Vector__XXX
SG_ DecimalSymbolCommand : 22|2@1+ (1,0) [0|3] "" Vector__XXX
SG_ DateCommand : 24|8@1+ (1,0) [0|255] "" Vector__XXX
SG_ MassUnitCommand : 32|2@1+ (1,0) [0|3] "" Vector__XXX
SG_ VolumeUnitCommand : 34|2@1+ (1,0) [0|3] "" Vector__XXX
SG_ AreaUnitCommand : 36|2@1+ (1,0) [0|3] "" Vector__XXX
SG_ DistanceUnitCommand : 38|2@1+ (1,0) [0|3] "" Vector__XXX

BO_ 2566787326 AV00EF: 8 Vector__XXX
SG_ AuxValve0ExtendPortEstimatedFlow : 0|8@1+ (1,-125) [-125|125] "%" Vector__XXX
SG_ AuxValve0RetractPortEstFlow : 8|8@1+ (1,-125) [-125|125] "%" Vector__XXX
SG_ AuxValve0State : 16|4@1+ (1,0) [0|15] "" Vector__XXX
SG_ AuxValve0FailSafeMode : 22|2@1+ (1,0) [0|3] "" Vector__XXX
SG_ AuxiliaryValve0ExitReasonCode : 32|6@1+ (1,0) [0|63] "" Vector__XXX

BO_ 2566787582 AV01EF: 8 Vector__XXX
SG_ AuxValve1ExtendPortEstimatedFlow : 0|8@1+ (1,-125) [-125|125] "%" Vector__XXX
SG_ AuxValve1RetractPortEstFlow : 8|8@1+ (1,-125) [-125|125] "%" Vector__XXX
SG_ AuxValve1State : 16|4@1+ (1,0) [0|15] "" Vector__XXX
SG_ AuxValve1FailSafeMode : 22|2@1+ (1,0) [0|3] "" Vector__XXX
SG_ AuxiliaryValve1ExitReasonCode : 32|6@1+ (1,0) [0|63] "" Vector__XXX

BO_ 2566787838 AV02EF: 8 Vector__XXX
SG_ AuxValve2ExtendPortEstimatedFlow : 0|8@1+ (1,-125) [-125|125] "%" Vector__XXX
SG_ AuxValve2RetractPortEstFlow : 8|8@1+ (1,-125) [-125|125] "%" Vector__XXX
SG_ AuxValve2State : 16|4@1+ (1,0) [0|15] "" Vector__XXX
SG_ AuxValve2FailSafeMode : 22|2@1+ (1,0) [0|3] "" Vector__XXX
SG_ AuxiliaryValve2ExitReasonCode : 32|6@1+ (1,0) [0|63] "" Vector__XXX

BO_ 2566788094 AV03EF: 8 Vector__XXX
SG_ AuxValve3ExtendPortEstimatedFlow : 0|8@1+ (1,-125) [-125|125] "%" Vector__XXX
SG_ AuxValve3RetractPortEstFlow : 8|8@1+ (1,-125) [-125|125] "%" Vector__XXX
SG_ AuxValve3State : 16|4@1+ (1,0) [0|15] "" Vector__XXX
SG_ AuxValve3FailSafeMode : 22|2@1+ (1,0) [0|3] "" Vector__XXX
SG_ AuxiliaryValve3ExitReasonCode : 32|6@1+ (1,0) [0|63] "" Vector__XXX

BO_ 2566788350 AV04EF: 8 Vector__XXX
SG_ AuxValve4ExtendPortEstimatedFlow : 0|8@1+ (1,-125) [-125|125] "%" Vector__XXX
SG_ AuxValve4RetractPortEstFlow : 8|8@1+ (1,-125) [-125|125] "%" Vector__XXX
SG_ AuxValve4State : 16|4@1+ (1,0) [0|15] "" Vector__XXX
SG_ AuxValve4FailSafeMode : 22|2@1+ (1,0) [0|3] "" Vector__XXX
SG_ AuxiliaryValve4ExitReasonCode : 32|6@1+ (1,0) [0|63] "" Vector__XXX

BO_ 2566788606 AV05EF: 8 Vector__XXX
SG_ AuxValve5ExtendPortEstimatedFlow : 0|8@1+ (1,-125) [-125|125] "%" Vector__XXX
SG_ AuxValve5RetractPortEstFlow : 8|8@1+ (1,-125) [-125|125] "%" Vector__XXX
SG_ AuxValve5State : 16|4@1+ (1,0) [0|15] "" Vector__XXX
SG_ AuxValve5FailSafeMode : 22|2@1+ (1,0) [0|3] "" Vector__XXX
SG_ AuxiliaryValve5ExitReasonCode : 32|6@1+ (1,0) [0|63] "" Vector__XXX

BO_ 2566788862 AV06EF: 8 Vector__XXX
SG_ AuxValve6ExtendPortEstimatedFlow : 0|8@1+ (1,-125) [-125|125] "%" Vector__XXX
SG_ AuxValve6RetractPortEstFlow : 8|8@1+ (1,-125) [-125|125] "%" Vector__XXX
SG_ AuxValve6State : 16|4@1+ (1,0) [0|15] "" Vector__XXX
SG_ AuxValve6FailSafeMode : 22|2@1+ (1,0) [0|3] "" Vector__XXX
SG_ AuxiliaryValve6ExitReasonCode : 32|6@1+ (1,0) [0|63] "" Vector__XXX

BO_ 2566789118 AV07EF: 8 Vector__XXX
SG_ AuxValve7ExtendPortEstimatedFlow : 0|8@1+ (1,-125) [-125|125] "%" Vector__XXX
SG_ AuxValve7RetractPortEstFlow : 8|8@1+ (1,-125) [-125|125] "%" Vector__XXX
SG_ AuxValve7State : 16|4@1+ (1,0) [0|15] "" Vector__XXX
SG_ AuxValve7FailSafeMode : 22|2@1+ (1,0) [0|3] "" Vector__XXX
SG_ AuxiliaryValve7ExitReasonCode : 32|6@1+ (1,0) [0|63] "" Vector__XXX

BO_ 2566789374 AV08EF: 8 Vector__XXX
SG_ AuxValve8ExtendPortEstimatedFlow : 0|8@1+ (1,-125) [-125|125] "%" Vector__XXX
SG_ AuxValve8RetractPortEstFlow : 8|8@1+ (1,-125) [-125|125] "%" Vector__XXX
SG_ AuxValve8State : 16|4@1+ (1,0) [0|15] "" Vector__XXX
SG_ AuxValve8FailSafeMode : 22|2@1+ (1,0) [0|3] "" Vector__XXX
SG_ AuxiliaryValve8ExitReasonCode : 32|6@1+ (1,0) [0|63] "" Vector__XXX

BO_ 2566789630 AV09EF: 8 Vector__XXX
SG_ AuxValve9ExtendPortEstimatedFlow : 0|8@1+ (1,-125) [-125|125] "%" Vector__XXX
SG_ AuxValve9RetractPortEstFlow : 8|8@1+ (1,-125) [-125|125] "%" Vector__XXX
SG_ AuxValve9State : 16|4@1+ (1,0) [0|15] "" Vector__XXX
SG_ AuxValve9FailSafeMode : 22|2@1+ (1,0) [0|3] "" Vector__XXX
SG_ AuxiliaryValve9ExitReasonCode : 32|6@1+ (1,0) [0|63] "" Vector__XXX

BO_ 2566789886 AV10EF: 8 Vector__XXX
SG_ AuxValve10ExtendPortEstFlow : 0|8@1+ (1,-125) [-125|125] "%" Vector__XXX
SG_ AuxValve10RetractPortEstFlow : 8|8@1+ (1,-125) [-125|125] "%" Vector__XXX
SG_ AuxValve10State : 16|4@1+ (1,0) [0|15] "" Vector__XXX
SG_ AuxValve10FailSafeMode : 22|2@1+ (1,0) [0|3] "" Vector__XXX
SG_ AuxiliaryValve10ExitReasonCode : 32|6@1+ (1,0) [0|63] "" Vector__XXX

BO_ 2566790142 AV11EF: 8 Vector__XXX
SG_ AuxValve11ExtendPortEstFlow : 0|8@1+ (1,-125) [-125|125] "%" Vector__XXX
SG_ AuxValve11RetractPortEstFlow : 8|8@1+ (1,-125) [-125|125] "%" Vector__XXX
SG_ AuxValve11State : 16|4@1+ (1,0) [0|15] "" Vector__XXX
SG_ AuxValve11FailSafeMode : 22|2@1+ (1,0) [0|3] "" Vector__XXX
SG_ AuxiliaryValve11ExitReasonCode : 32|6@1+ (1,0) [0|63] "" Vector__XXX

BO_ 2566790398 AV12EF: 8 Vector__XXX
SG_ AuxValve12ExtendPortEstFlow : 0|8@1+ (1,-125) [-125|125] "%" Vector__XXX
SG_ AuxValve12RetractPortEstFlow : 8|8@1+ (1,-125) [-125|125] "%" Vector__XXX
SG_ AuxValve12State : 16|4@1+ (1,0) [0|15] "" Vector__XXX
SG_ AuxValve12FailSafeMode : 22|2@1+ (1,0) [0|3] "" Vector__XXX
SG_ AuxiliaryValve12ExitReasonCode : 32|6@1+ (1,0) [0|63] "" Vector__XXX

BO_ 2566790654 AV13EF: 8 Vector__XXX
SG_ AuxValve13ExtendPortEstFlow : 0|8@1+ (1,-125) [-125|125] "%" Vector__XXX
SG_ AuxValve13RetractPortEstFlow : 8|8@1+ (1,-125) [-125|125] "%" Vector__XXX
SG_ AuxValve13State : 16|4@1+ (1,0) [0|15] "" Vector__XXX
SG_ AuxValve13FailSafeMode : 22|2@1+ (1,0) [0|3] "" Vector__XXX
SG_ AuxiliaryValve13ExitReasonCode : 32|6@1+ (1,0) [0|63] "" Vector__XXX

BO_ 2566790910 AV14EF: 8 Vector__XXX
SG_ AuxValve14ExtendPortEstFlow : 0|8@1+ (1,-125) [-125|125] "%" Vector__XXX
SG_ AuxValve14RetractPortEstFlow : 8|8@1+ (1,-125) [-125|125] "%" Vector__XXX
SG_ AuxValve14State : 16|4@1+ (1,0) [0|15] "" Vector__XXX
SG_ AuxValve14FailSafeMode : 22|2@1+ (1,0) [0|3] "" Vector__XXX
SG_ AuxiliaryValve14ExitReasonCode : 32|6@1+ (1,0) [0|63] "" Vector__XXX

BO_ 2566791166 AV15EF: 8 Vector__XXX
SG_ AuxValve15ExtendPortEstFlow : 0|8@1+ (1,-125) [-125|125] "%" Vector__XXX
SG_ AuxValve15RetractPortEstFlow : 8|8@1+ (1,-125) [-125|125] "%" Vector__XXX
SG_ AuxValve15State : 16|4@1+ (1,0) [0|15] "" Vector__XXX
SG_ AuxValve15FailSafeMode : 22|2@1+ (1,0) [0|3] "" Vector__XXX
SG_ AuxiliaryValve15ExitReasonCode : 32|6@1+ (1,0) [0|63] "" Vector__XXX

BO_ 2566791422 AV00MF: 8 Vector__XXX
SG_ AuxValve0ExtendPortMeasuredFlow : 0|8@1+ (1,-125) [-125|125] "%" Vector__XXX
SG_ AuxValve0RetractPortMeasuredFlow : 8|8@1+ (1,-125) [-125|125] "%" Vector__XXX
SG_ AuxValve0ExtendPortPressure : 16|16@1+ (5,0) [0|321275] "kPa" Vector__XXX
SG_ AuxValve0RetractPortPressure : 32|16@1+ (5,0) [0|321275] "kPa" Vector__XXX
SG_ AuxValve0ReturnPortPressure : 48|8@1+ (16,0) [0|4000] "kPa" Vector__XXX

BO_ 2566791678 AV01MF: 8 Vector__XXX
SG_ AuxValve1ExtendPortMeasuredFlow : 0|8@1+ (1,-125) [-125|125] "%" Vector__XXX
SG_ AuxValve1RetractPortMeasuredFlow : 8|8@1+ (1,-125) [-125|125] "%" Vector__XXX
SG_ AuxValve1ExtendPortPressure : 16|16@1+ (5,0) [0|321275] "kPa" Vector__XXX
SG_ AuxValve1RetractPortPressure : 32|16@1+ (5,0) [0|321275] "kPa" Vector__XXX
SG_ AuxValve1ReturnPortPressure : 48|8@1+ (16,0) [0|4000] "kPa" Vector__XXX

BO_ 2566791934 AV02MF: 8 Vector__XXX
SG_ AuxValve2ExtendPortMeasuredFlow : 0|8@1+ (1,-125) [-125|125] "%" Vector__XXX
SG_ AuxValve2RetractPortMeasuredFlow : 8|8@1+ (1,-125) [-125|125] "%" Vector__XXX
SG_ AuxValve2ExtendPortPressure : 16|16@1+ (5,0) [0|321275] "kPa" Vector__XXX
SG_ AuxValve2RetractPortPressure : 32|16@1+ (5,0) [0|321275] "kPa" Vector__XXX
SG_ AuxValve2ReturnPortPressure : 48|8@1+ (16,0) [0|4000] "kPa" Vector__XXX

BO_ 2566792190 AV03MF: 8 Vector__XXX
SG_ AuxValve3ExtendPortMeasuredFlow : 0|8@1+ (1,-125) [-125|125] "%" Vector__XXX
SG_ AuxValve3RetractPortMeasuredFlow : 8|8@1+ (1,-125) [-125|125] "%" Vector__XXX
SG_ AuxValve3ExtendPortPressure : 16|16@1+ (5,0) [0|321275] "kPa" Vector__XXX
SG_ AuxValve3RetractPortPressure : 32|16@1+ (5,0) [0|321275] "kPa" Vector__XXX
SG_ AuxValve3ReturnPortPressure : 48|8@1+ (16,0) [0|4000] "kPa" Vector__XXX

BO_ 2566792446 AV04MF: 8 Vector__XXX
SG_ AuxValve4ExtendPortMeasuredFlow : 0|8@1+ (1,-125) [-125|125] "%" Vector__XXX
SG_ AuxValve4RetractPortMeasuredFlow : 8|8@1+ (1,-125) [-125|125] "%" Vector__XXX
SG_ AuxValve4ExtendPortPressure : 16|16@1+ (5,0) [0|321275] "kPa" Vector__XXX
SG_ AuxValve4RetractPortPressure : 32|16@1+ (5,0) [0|321275] "kPa" Vector__XXX
SG_ AuxValve4ReturnPortPressure : 48|8@1+ (16,0) [0|4000] "kPa" Vector__XXX

BO_ 2566792702 AV05MF: 8 Vector__XXX
SG_ AuxValve5ExtendPortMeasuredFlow : 0|8@1+ (1,-125) [-125|125] "%" Vector__XXX
SG_ AuxValve5RetractPortMeasuredFlow : 8|8@1+ (1,-125) [-125|125] "%" Vector__XXX
SG_ AuxValve5ExtendPortPressure : 16|16@1+ (5,0) [0|321275] "kPa" Vector__XXX
SG_ AuxValve5RetractPortPressure : 32|16@1+ (5,0) [0|321275] "kPa" Vector__XXX
SG_ AuxValve5ReturnPortPressure : 48|8@1+ (16,0) [0|4000] "kPa" Vector__XXX

BO_ 2566792958 AV06MF: 8 Vector__XXX
SG_ AuxValve6ExtendPortMeasuredFlow : 0|8@1+ (1,-125) [-125|125] "%" Vector__XXX
SG_ AuxValve6RetractPortMeasuredFlow : 8|8@1+ (1,-125) [-125|125] "%" Vector__XXX
SG_ AuxValve6ExtendPortPressure : 16|16@1+ (5,0) [0|321275] "kPa" Vector__XXX
SG_ AuxValve6RetractPortPressure : 32|16@1+ (5,0) [0|321275] "kPa" Vector__XXX
SG_ AuxValve6ReturnPortPressure : 48|8@1+ (16,0) [0|4000] "kPa" Vector__XXX

BO_ 2566793214 AV07MF: 8 Vector__XXX
SG_ AuxValve7ExtendPortMeasuredFlow : 0|8@1+ (1,-125) [-125|125] "%" Vector__XXX
SG_ AuxValve7RetractPortMeasuredFlow : 8|8@1+ (1,-125) [-125|125] "%" Vector__XXX
SG_ AuxValve7ExtendPortPressure : 16|16@1+ (5,0) [0|321275] "kPa" Vector__XXX
SG_ AuxValve7RetractPortPressure : 32|16@1+ (5,0) [0|321275] "kPa" Vector__XXX
SG_ AuxValve7ReturnPortPressure : 48|8@1+ (16,0) [0|4000] "kPa" Vector__XXX

BO_ 2566793470 AV08MF: 8 Vector__XXX
SG_ AuxValve8ExtendPortMeasuredFlow : 0|8@1+ (1,-125) [-125|125] "%" Vector__XXX
SG_ AuxValve8RetractPortMeasuredFlow : 8|8@1+ (1,-125) [-125|125] "%" Vector__XXX
SG_ AuxValve8ExtendPortPressure : 16|16@1+ (5,0) [0|321275] "kPa" Vector__XXX
SG_ AuxValve8RetractPortPressure : 32|16@1+ (5,0) [0|321275] "kPa" Vector__XXX
SG_ AuxValve8ReturnPortPressure : 48|8@1+ (16,0) [0|4000] "kPa" Vector__XXX

BO_ 2566793726 AV09MF: 8 Vector__XXX
SG_ AuxValve9ExtendPortMeasuredFlow : 0|8@1+ (1,-125) [-125|125] "%" Vector__XXX
SG_ AuxValve9RetractPortMeasuredFlow : 8|8@1+ (1,-125) [-125|125] "%" Vector__XXX
SG_ AuxValve9ExtendPortPressure : 16|16@1+ (5,0) [0|321275] "kPa" Vector__XXX
SG_ AuxValve9RetractPortPressure : 32|16@1+ (5,0) [0|321275] "kPa" Vector__XXX
SG_ AuxValve9ReturnPortPressure : 48|8@1+ (16,0) [0|4000] "kPa" Vector__XXX

BO_ 2566793982 AV10MF: 8 Vector__XXX
SG_ AuxValve10ExtendPortMeasuredFlow : 0|8@1+ (1,-125) [-125|125] "%" Vector__XXX
SG_ AuxValve10RetractPortMeasuredFlw : 8|8@1+ (1,-125) [-125|125] "%" Vector__XXX
SG_ AuxValve10ExtendPortPressure : 16|16@1+ (5,0) [0|321275] "kPa" Vector__XXX
SG_ AuxValve10RetractPortPressure : 32|16@1+ (5,0) [0|321275] "kPa" Vector__XXX
SG_ AuxValve10ReturnPortPressure : 48|8@1+ (16,0) [0|4000] "kPa" Vector__XXX

BO_ 2566794238 AV11MF: 8 Vector__XXX
SG_ AuxValve11ExtendPortMeasuredFlow : 0|8@1+ (1,-125) [-125|125] "%" Vector__XXX
SG_ AuxValve11RetractPortMeasuredFlw : 8|8@1+ (1,-125) [-125|125] "%" Vector__XXX
SG_ AuxValve11ExtendPortPressure : 16|16@1+ (5,0) [0|321275] "kPa" Vector__XXX
SG_ AuxValve11RetractPortPressure : 32|16@1+ (5,0) [0|321275] "kPa" Vector__XXX
SG_ AuxValve11ReturnPortPressure : 48|8@1+ (16,0) [0|4000] "kPa" Vector__XXX

BO_ 2566794494 AV12MF: 8 Vector__XXX
SG_ AuxValve12ExtendPortMeasuredFlow : 0|8@1+ (1,-125) [-125|125] "%" Vector__XXX
SG_ AuxValve12RetractPortMeasuredFlw : 8|8@1+ (1,-125) [-125|125] "%" Vector__XXX
SG_ AuxValve12ExtendPortPressure : 16|16@1+ (5,0) [0|321275] "kPa" Vector__XXX
SG_ AuxValve12RetractPortPressure : 32|16@1+ (5,0) [0|321275] "kPa" Vector__XXX
SG_ AuxValve12ReturnPortPressure : 48|8@1+ (16,0) [0|4000] "kPa" Vector__XXX

BO_ 2566794750 AV13MF: 8 Vector__XXX
SG_ AuxValve13ExtendPortMeasuredFlow : 0|8@1+ (1,-125) [-125|125] "%" Vector__XXX
SG_ AuxValve13RetractPortMeasuredFlw : 8|8@1+ (1,-125) [-125|125] "%" Vector__XXX
SG_ AuxValve13ExtendPortPressure : 16|16@1+ (5,0) [0|321275] "kPa" Vector__XXX
SG_ AuxValve13RetractPortPressure : 32|16@1+ (5,0) [0|321275] "kPa" Vector__XXX
SG_ AuxValve13ReturnPortPressure : 48|8@1+ (16,0) [0|4000] "kPa" Vector__XXX

BO_ 2566795006 AV14MF: 8 Vector__XXX
SG_ AuxValve14ExtendPortMeasuredFlow : 0|8@1+ (1,-125) [-125|125] "%" Vector__XXX
SG_ AuxValve14RetractPortMeasuredFlw : 8|8@1+ (1,-125) [-125|125] "%" Vector__XXX
SG_ AuxValve14ExtendPortPressure : 16|16@1+ (5,0) [0|321275] "kPa" Vector__XXX
SG_ AuxValve14RetractPortPressure : 32|16@1+ (5,0) [0|321275] "kPa" Vector__XXX
SG_ AuxValve14ReturnPortPressure : 48|8@1+ (16,0) [0|4000] "kPa" Vector__XXX

BO_ 2566795262 AV15MF: 8 Vector__XXX
SG_ AuxValve15ExtendPortMeasuredFlow : 0|8@1+ (1,-125) [-125|125] "%" Vector__XXX
SG_ AuxValve15RetractPortMeasuredFlw : 8|8@1+ (1,-125) [-125|125] "%" Vector__XXX
SG_ AuxValve15ExtendPortPressure : 16|16@1+ (5,0) [0|321275] "kPa" Vector__XXX
SG_ AuxValve15RetractPortPressure : 32|16@1+ (5,0) [0|321275] "kPa" Vector__XXX
SG_ AuxValve15ReturnPortPressure : 48|8@1+ (16,0) [0|4000] "kPa" Vector__XXX

BO_ 2566795518 AV00C: 8 Vector__XXX
SG_ AuxValve0PortFlowCommand : 0|8@1+ (0.4,0) [0|100] "%" Vector__XXX
SG_ AuxValve0StateCommand : 16|4@1+ (1,0) [0|15] "" Vector__XXX
SG_ AuxValve0FailSafeModeCommand : 22|2@1+ (1,0) [0|3] "" Vector__XXX

BO_ 2566795774 AV01C: 8 Vector__XXX
SG_ AuxValve1PortFlowCommand : 0|8@1+ (0.4,0) [0|100] "%" Vector__XXX
SG_ AuxValve1StateCommand : 16|4@1+ (1,0) [0|15] "" Vector__XXX
SG_ AuxValve1FailSafeModeCommand : 22|2@1+ (1,0) [0|3] "" Vector__XXX

BO_ 2566796030 AV02C: 8 Vector__XXX
SG_ AuxValve2PortFlowCommand : 0|8@1+ (0.4,0) [0|100] "%" Vector__XXX
SG_ AuxValve2StateCommand : 16|4@1+ (1,0) [0|15] "" Vector__XXX
SG_ AuxValve2FailSafeModeCommand : 22|2@1+ (1,0) [0|3] "" Vector__XXX

BO_ 2566796286 AV03C: 8 Vector__XXX
SG_ AuxValve3PortFlowCommand : 0|8@1+ (0.4,0) [0|100] "%" Vector__XXX
SG_ AuxValve3StateCommand : 16|4@1+ (1,0) [0|15] "" Vector__XXX
SG_ AuxValve3FailSafeModeCommand : 22|2@1+ (1,0) [0|3] "" Vector__XXX

BO_ 2566796542 AV04C: 8 Vector__XXX
SG_ AuxValve4PortFlowCommand : 0|8@1+ (0.4,0) [0|100] "%" Vector__XXX
SG_ AuxValve4StateCommand : 16|4@1+ (1,0) [0|15] "" Vector__XXX
SG_ AuxValve4FailSafeModeCommand : 22|2@1+ (1,0) [0|3] "" Vector__XXX

BO_ 2566796798 AV05C: 8 Vector__XXX
SG_ AuxValve5PortFlowCommand : 0|8@1+ (0.4,0) [0|100] "%" Vector__XXX
SG_ AuxValve5StateCommand : 16|4@1+ (1,0) [0|15] "" Vector__XXX
SG_ AuxValve5FailSafeModeCommand : 22|2@1+ (1,0) [0|3] "" Vector__XXX

BO_ 2566797054 AV06C: 8 Vector__XXX
SG_ AuxValve6PortFlowCommand : 0|8@1+ (0.4,0) [0|100] "%" Vector__XXX
SG_ AuxValve6StateCommand : 16|4@1+ (1,0) [0|15] "" Vector__XXX
SG_ AuxValve6FailSafeModeCommand : 22|2@1+ (1,0) [0|3] "" Vector__XXX

BO_ 2566797310 AV07C: 8 Vector__XXX
SG_ AuxValve7PortFlowCommand : 0|8@1+ (0.4,0) [0|100] "%" Vector__XXX
SG_ AuxValve7StateCommand : 16|4@1+ (1,0) [0|15] "" Vector__XXX
SG_ AuxValve7FailSafeModeCommand : 22|2@1+ (1,0) [0|3] "" Vector__XXX

BO_ 2566797566 AV08C: 8 Vector__XXX
SG_ AuxValve8PortFlowCommand : 0|8@1+ (0.4,0) [0|100] "%" Vector__XXX
SG_ AuxValve8StateCommand : 16|4@1+ (1,0) [0|15] "" Vector__XXX
SG_ AuxValve8FailSafeModeCommand : 22|2@1+ (1,0) [0|3] "" Vector__XXX

BO_ 2566797822 AV09C: 8 Vector__XXX
SG_ AuxValve9PortFlowCommand : 0|8@1+ (0.4,0) [0|100] "%" Vector__XXX
SG_ AuxValve9StateCommand : 16|4@1+ (1,0) [0|15] "" Vector__XXX
SG_ AuxValve9FailSafeModeCommand : 22|2@1+ (1,0) [0|3] "" Vector__XXX

BO_ 2566798078 AV10C: 8 Vector__XXX
SG_ AuxValve10PortFlowCommand : 0|8@1+ (0.4,0) [0|100] "%" Vector__XXX
SG_ AuxValve10StateCommand : 16|4@1+ (1,0) [0|15] "" Vector__XXX
SG_ AuxValve10FailSafeModeCommand : 22|2@1+ (1,0) [0|3] "" Vector__XXX

BO_ 2566798334 AV11C: 8 Vector__XXX
SG_ AuxValve11PortFlowCommand : 0|8@1+ (0.4,0) [0|100] "%" Vector__XXX
SG_ AuxValve11StateCommand : 16|4@1+ (1,0) [0|15] "" Vector__XXX
SG_ AuxValve11FailSafeModeCommand : 22|2@1+ (1,0) [0|3] "" Vector__XXX

BO_ 2566798590 AV12C: 8 Vector__XXX
SG_ AuxValve12PortFlowCommand : 0|8@1+ (0.4,0) [0|100] "%" Vector__XXX
SG_ AuxValve12StateCommand : 16|4@1+ (1,0) [0|15] "" Vector__XXX
SG_ AuxValve12FailSafeModeCommand : 22|2@1+ (1,0) [0|3] "" Vector__XXX

BO_ 2566798846 AV13C: 8 Vector__XXX
SG_ AuxValve13PortFlowCommand : 0|8@1+ (0.4,0) [0|100] "%" Vector__XXX
SG_ AuxValve13StateCommand : 16|4@1+ (1,0) [0|15] "" Vector__XXX
SG_ AuxValve13FailSafeModeCommand : 22|2@1+ (1,0) [0|3] "" Vector__XXX

BO_ 2566799102 AV14C: 8 Vector__XXX
SG_ AuxValve14PortFlowCommand : 0|8@1+ (0.4,0) [0|100] "%" Vector__XXX
SG_ AuxValve14StateCommand : 16|4@1+ (1,0) [0|15] "" Vector__XXX
SG_ AuxValve14FailSafeModeCommand : 22|2@1+ (1,0) [0|3] "" Vector__XXX

BO_ 2566799358 AV15C: 8 Vector__XXX
SG_ AuxValve15PortFlowCommand : 0|8@1+ (0.4,0) [0|100] "%" Vector__XXX
SG_ AuxValve15StateCommand : 16|4@1+ (1,0) [0|15] "" Vector__XXX
SG_ AuxValve15FailSafeModeCommand : 22|2@1+ (1,0) [0|3] "" Vector__XXX

BO_ 2566799614 LD: 8 Vector__XXX
SG_ RunningLight : 0|2@1+ (1,0) [0|3] "" Vector__XXX
SG_ AlternateBeamHeadLightData : 2|2@1+ (1,0) [0|3] "" Vector__XXX
SG_ LowBeamHeadLightData : 4|2@1+ (1,0) [0|3] "" Vector__XXX
SG_ HighBeamHeadLightData : 6|2@1+ (1,0) [0|3] "" Vector__XXX
SG_ TractorFrontFogLights : 8|2@1+ (1,0) [0|3] "" Vector__XXX
SG_ RotatingBeaconLight : 10|2@1+ (1,0) [0|3] "" Vector__XXX
SG_ RightTurnSignalLights : 12|2@1+ (1,0) [0|3] "" Vector__XXX
SG_ LeftTurnSignalLights : 14|2@1+ (1,0) [0|3] "" Vector__XXX
SG_ BackUpLightAndAlarmHorn : 16|2@1+ (1,0) [0|3] "" Vector__XXX
SG_ CenterStopLight : 18|2@1+ (1,0) [0|3] "" Vector__XXX
SG_ RightStopLight : 20|2@1+ (1,0) [0|3] "" Vector__XXX
SG_ LeftStopLight : 22|2@1+ (1,0) [0|3] "" Vector__XXX
SG_ ImplementClearanceLight : 24|2@1+ (1,0) [0|3] "" Vector__XXX
SG_ TractorClearanceLight : 26|2@1+ (1,0) [0|3] "" Vector__XXX
SG_ ImplementMarkerLight : 28|2@1+ (1,0) [0|3] "" Vector__XXX
SG_ TractorMarkerLight : 30|2@1+ (1,0) [0|3] "" Vector__XXX
SG_ RearFogLights : 32|2@1+ (1,0) [0|3] "" Vector__XXX
SG_ TractorUndersideMntdWorkLights : 34|2@1+ (1,0) [0|3] "" Vector__XXX
SG_ TractorRearLowMountedWorkLights : 36|2@1+ (1,0) [0|3] "" Vector__XXX
SG_ TractorRearHighMountedWorkLights : 38|2@1+ (1,0) [0|3] "" Vector__XXX
SG_ TractorSideLowMountedWorkLights : 40|2@1+ (1,0) [0|3] "" Vector__XXX
SG_ TractorSideHighMountedWorkLights : 42|2@1+ (1,0) [0|3] "" Vector__XXX
SG_ TractorFrontLowMountedWorkLights : 44|2@1+ (1,0) [0|3] "" Vector__XXX
SG_ TractorFrntHighMountedWorkLights : 46|2@1+ (1,0) [0|3] "" Vector__XXX
SG_ ImplementOEMOption2Light : 48|2@1+ (1,0) [0|3] "" Vector__XXX
SG_ ImplementOEMOption1Light : 50|2@1+ (1,0) [0|3] "" Vector__XXX
SG_ ImplementRightFacingWorkLight : 52|2@1+ (1,0) [0|3] "" Vector__XXX
SG_ ImplementLeftForwardWorkLight : 54|2@1+ (1,0) [0|3] "" Vector__XXX
SG_ ImplementRightForwardWorkLight : 58|2@1+ (1,0) [0|3] "" Vector__XXX
SG_ ImplementLeftFacingWorkLight : 60|2@1+ (1,0) [0|3] "" Vector__XXX
SG_ ImplementRearWorkLight : 62|2@1+ (1,0) [0|3] "" Vector__XXX

BO_ 2365473278 LCMD: 8 Vector__XXX
SG_ RunningLightCommand : 0|2@1+ (1,0) [0|3] "" Vector__XXX
SG_ AlternateBeamHeadLightCommand : 2|2@1+ (1,0) [0|3] "" Vector__XXX
SG_ LowBeamHeadLightCommand : 4|2@1+ (1,0) [0|3] "" Vector__XXX
SG_ HighBeamHeadLightCommand : 6|2@1+ (1,0) [0|3] "" Vector__XXX
SG_ TractorFrontFogLightsCommand : 8|2@1+ (1,0) [0|3] "" Vector__XXX
SG_ RotatingBeaconLightCommand : 10|2@1+ (1,0) [0|3] "" Vector__XXX
SG_ RightTurnSignalLightsCommand : 12|2@1+ (1,0) [0|3] "" Vector__XXX
SG_ LeftTurnSignalLightsCommand : 14|2@1+ (1,0) [0|3] "" Vector__XXX
SG_ BackUpLightAndAlarmHornCommand : 16|2@1+ (1,0) [0|3] "" Vector__XXX
SG_ CenterStopLightCommand : 18|2@1+ (1,0) [0|3] "" Vector__XXX
SG_ RightStopLightCommand : 20|2@1+ (1,0) [0|3] "" Vector__XXX
SG_ LeftStopLightCommand : 22|2@1+ (1,0) [0|3] "" Vector__XXX
SG_ ImplementClearanceLightCommand : 24|2@1+ (1,0) [0|3] "" Vector__XXX
SG_ TractorClearanceLightCommand : 26|2@1+ (1,0) [0|3] "" Vector__XXX
SG_ ImplementMarkerLightCommand : 28|2@1+ (1,0) [0|3] "" Vector__XXX
SG_ TractorMarkerLightCommand : 30|2@1+ (1,0) [0|3] "" Vector__XXX
SG_ RearFogLightCommand : 32|2@1+ (1,0) [0|3] "" Vector__XXX
SG_ TractorUnderSdeMntdWorkLightsCmd : 34|2@1+ (1,0) [0|3] "" Vector__XXX
SG_ TractorRearLowMntdWorkLightsCmd : 36|2@1+ (1,0) [0|3] "" Vector__XXX
SG_ TractorRearHghMntdWorkLightsCmd : 38|2@1+ (1,0) [0|3] "" Vector__XXX
SG_ TractorSideLowMntdWorkLightsCmd : 40|2@1+ (1,0) [0|3] "" Vector__XXX
SG_ TractorSideHghMntdWorkLightsCmd : 42|2@1+ (1,0) [0|3] "" Vector__XXX
SG_ TractorFrntLowMntdWorkLightsCmd : 44|2@1+ (1,0) [0|3] "" Vector__XXX
SG_ TractorFrntHghMntdWorkLightsCmd : 46|2@1+ (1,0) [0|3] "" Vector__XXX
SG_ ImplementOEMOption2LightCommand : 48|2@1+ (1,0) [0|3] "" Vector__XXX
SG_ ImplementOEMOption1LightCommand : 50|2@1+ (1,0) [0|3] "" Vector__XXX
SG_ ImplementRightFacingWorkLightCmd : 52|2@1+ (1,0) [0|3] "" Vector__XXX
SG_ ImplementLeftForwardWorkLightCmd : 54|2@1+ (1,0) [0|3] "" Vector__XXX
SG_ LightingDataRequestCommand : 56|2@1+ (1,0) [0|3] "" Vector__XXX
SG_ ImplementRightFrwdWorkLightCmd : 58|2@1+ (1,0) [0|3] "" Vector__XXX
SG_ ImplementLeftFacingWorkLightCmd : 60|2@1+ (1,0) [0|3] "" Vector__XXX
SG_ ImplementRearWorkLightCommand : 62|2@1+ (1,0) [0|3] "" Vector__XXX

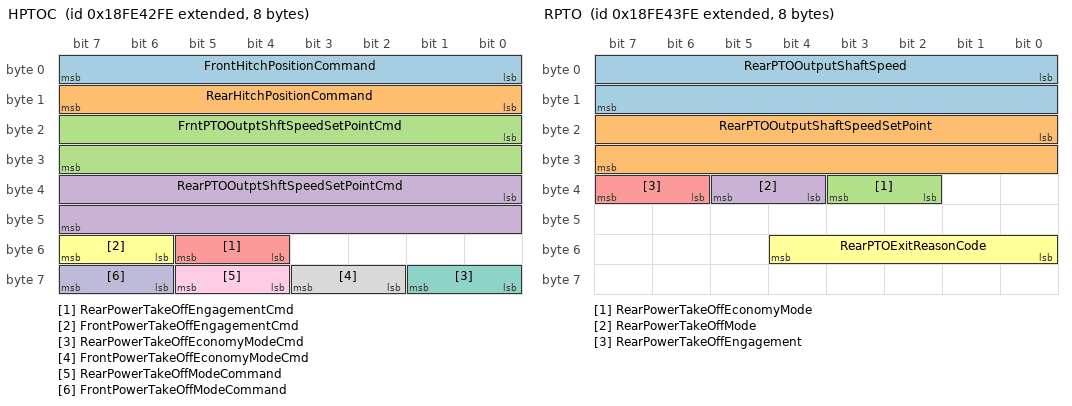
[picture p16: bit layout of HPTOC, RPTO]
BO_ 2566800126 HPTOC: 8 Vector__XXX
SG_ FrontHitchPositionCommand : 0|8@1+ (0.4,0) [0|100] "%" Vector__XXX
SG_ RearHitchPositionCommand : 8|8@1+ (0.4,0) [0|100] "%" Vector__XXX
SG_ FrntPTOOutptShftSpeedSetPointCmd : 16|16@1+ (0.125,0) [0|8031.875] "rpm" Vector__XXX
SG_ RearPTOOutptShftSpeedSetPointCmd : 32|16@1+ (0.125,0) [0|8031.875] "rpm" Vector__XXX
SG_ RearPowerTakeOffEngagementCmd : 52|2@1+ (1,0) [0|3] "" Vector__XXX
SG_ FrontPowerTakeOffEngagementCmd : 54|2@1+ (1,0) [0|3] "" Vector__XXX
SG_ RearPowerTakeOffEconomyModeCmd : 56|2@1+ (1,0) [0|3] "" Vector__XXX
SG_ FrontPowerTakeOffEconomyModeCmd : 58|2@1+ (1,0) [0|3] "" Vector__XXX
SG_ RearPowerTakeOffModeCommand : 60|2@1+ (1,0) [0|3] "" Vector__XXX
SG_ FrontPowerTakeOffModeCommand : 62|2@1+ (1,0) [0|3] "" Vector__XXX

BO_ 2566800382 RPTO: 8 Vector__XXX
SG_ RearPTOOutputShaftSpeed : 0|16@1+ (0.125,0) [0|8031.875] "rpm" Vector__XXX
SG_ RearPTOOutputShaftSpeedSetPoint : 16|16@1+ (0.125,0) [0|8031.875] "rpm" Vector__XXX
SG_ RearPowerTakeOffEconomyMode : 34|2@1+ (1,0) [0|3] "" Vector__XXX
SG_ RearPowerTakeOffMode : 36|2@1+ (1,0) [0|3] "" Vector__XXX
SG_ RearPowerTakeOffEngagement : 38|2@1+ (1,0) [0|3] "" Vector__XXX
SG_ RearPTOExitReasonCode : 48|5@1+ (1,0) [0|31] "" Vector__XXX

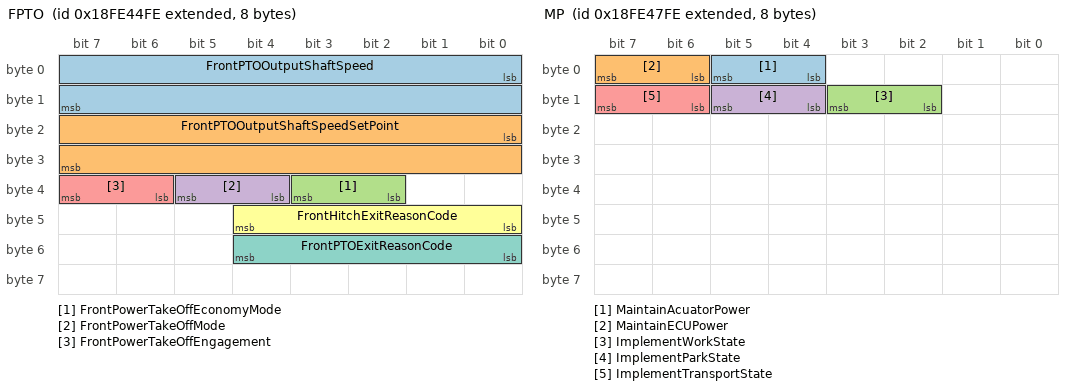
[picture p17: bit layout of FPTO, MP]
BO_ 2566800638 FPTO: 8 Vector__XXX
SG_ FrontPTOOutputShaftSpeed : 0|16@1+ (0.125,0) [0|8031.875] "rpm" Vector__XXX
SG_ FrontPTOOutputShaftSpeedSetPoint : 16|16@1+ (0.125,0) [0|8031.875] "rpm" Vector__XXX
SG_ FrontPowerTakeOffEconomyMode : 34|2@1+ (1,0) [0|3] "" Vector__XXX
SG_ FrontPowerTakeOffMode : 36|2@1+ (1,0) [0|3] "" Vector__XXX
SG_ FrontPowerTakeOffEngagement : 38|2@1+ (1,0) [0|3] "" Vector__XXX
SG_ FrontHitchExitReasonCode : 40|5@1+ (1,0) [0|31] "" Vector__XXX
SG_ FrontPTOExitReasonCode : 48|5@1+ (1,0) [0|31] "" Vector__XXX

BO_ 2566800894 RHS: 8 Vector__XXX
SG_ RearHitchPosition : 0|8@1+ (0.4,0) [0|100] "%" Vector__XXX
SG_ RearHitchInWorkIndication : 14|2@1+ (1,0) [0|3] "" Vector__XXX
SG_ RearNominalLowerLinkForce : 16|8@1+ (0.8,-100) [-100|100] "%" Vector__XXX
SG_ RearDraft : 24|16@1+ (10,-320000) [-320000|322550] "N" Vector__XXX
SG_ RearHitchExitReasonCode : 40|5@1+ (1,0) [0|31] "" Vector__XXX

BO_ 2566801150 FHS: 8 Vector__XXX
SG_ FrontHitchPosition : 0|8@1+ (0.4,0) [0|100] "%" Vector__XXX
SG_ FrontHitchInWorkIndication : 14|2@1+ (1,0) [0|3] "" Vector__XXX
SG_ FrontNominalLowerLinkForce : 16|8@1+ (0.8,-100) [-100|100] "%" Vector__XXX
SG_ FrontDraft : 24|16@1+ (10,-320000) [-320000|322550] "N" Vector__XXX

BO_ 2566801406 MP: 8 Vector__XXX
SG_ MaintainAcuatorPower : 4|2@1+ (1,0) [0|3] "" Vector__XXX
SG_ MaintainECUPower : 6|2@1+ (1,0) [0|3] "" Vector__XXX
SG_ ImplementWorkState : 10|2@1+ (1,0) [0|3] "" Vector__XXX
SG_ ImplementParkState : 12|2@1+ (1,0) [0|3] "" Vector__XXX
SG_ ImplementTransportState : 14|2@1+ (1,0) [0|3] "" Vector__XXX

BO_ 2566801662 WBSD: 8 Vector__XXX
SG_ WheelBasedSpeed : 0|16@1+ (0.001,0) [0|64.255] "m/s" Vector__XXX
SG_ WheelBasedDistance : 16|32@1+ (0.001,0) [0|4211081.215] "m" Vector__XXX
SG_ MaximumTimeOfTractorPower : 48|8@1+ (1,0) [0|250] "min" Vector__XXX
SG_ WheelBasedDirection : 56|2@1+ (1,0) [0|3] "" Vector__XXX
SG_ KeySwitchNOTOFF : 58|2@1+ (1,0) [0|3] "" Vector__XXX

BO_ 2566801918 GBSD: 8 Vector__XXX
SG_ GroundBasedImplementSpeed : 0|16@1+ (0.001,0) [0|64.255] "m/s" Vector__XXX
SG_ GroundBasedImplementDistance : 16|32@1+ (0.001,0) [0|4211081.215] "m" Vector__XXX
SG_ GroundBasedDirection : 56|2@1+ (1,0) [0|3] "" Vector__XXX

BO_ 2566802174 ETC7: 8 Vector__XXX
SG_ TrnsmCurrentRngDisplayBlankStat : 0|2@1+ (1,0) [0|3] "" Vector__XXX
SG_ TransmissionServiceIndicator : 2|2@1+ (1,0) [0|3] "" Vector__XXX
SG_ TrnsmRqedRngDisplayBlankStat : 4|2@1+ (1,0) [0|3] "" Vector__XXX
SG_ TrnsmRqedRngDisplayFlashStat : 6|2@1+ (1,0) [0|3] "" Vector__XXX
SG_ TransmissionReadyForBrakeRelease : 8|2@1+ (1,0) [0|3] "" Vector__XXX
SG_ ActiveShiftConsoleIndicator : 10|2@1+ (1,0) [0|3] "" Vector__XXX
SG_ TransmissionEngineCrankEnable : 12|2@1+ (1,0) [0|3] "" Vector__XXX
SG_ TransmissionShiftInhibitIndictr : 14|2@1+ (1,0) [0|3] "" Vector__XXX
SG_ TransmissionMode4Indicator : 16|2@1+ (1,0) [0|3] "" Vector__XXX
SG_ TransmissionMode3Indicator : 18|2@1+ (1,0) [0|3] "" Vector__XXX
SG_ TransmissionMode2Indicator : 20|2@1+ (1,0) [0|3] "" Vector__XXX
SG_ TransmissionMode1Indicator : 22|2@1+ (1,0) [0|3] "" Vector__XXX
SG_ TransmissionRequestedGearFdbck : 24|8@1+ (1,-125) [-125|125] "" Vector__XXX
SG_ TransmissionMode5Indicator : 32|2@1+ (1,0) [0|3] "" Vector__XXX
SG_ TransmissionMode6Indicator : 34|2@1+ (1,0) [0|3] "" Vector__XXX
SG_ TransmissionMode7Indicator : 36|2@1+ (1,0) [0|3] "" Vector__XXX
SG_ TransmissionMode8Indicator : 38|2@1+ (1,0) [0|3] "" Vector__XXX
SG_ TrnsmReverseGearShftInhbtStat : 40|2@1+ (1,0) [0|3] "" Vector__XXX
SG_ TransmissionWarningIndicator : 42|2@1+ (1,0) [0|3] "" Vector__XXX
SG_ TransmissionMode9Indicator : 44|2@1+ (1,0) [0|3] "" Vector__XXX
SG_ TransmissionMode10Indicator : 46|2@1+ (1,0) [0|3] "" Vector__XXX
SG_ TrnsmAirSupplyPressIndictr : 48|3@1+ (1,0) [0|7] "" Vector__XXX
SG_ TransmissionAutoNeutralState : 51|3@1+ (1,0) [0|7] "" Vector__XXX
SG_ TransmissionManualModeIndicator : 54|2@1+ (1,0) [0|3] "" Vector__XXX
SG_ TransmissionLoadReductionIndictr : 56|2@1+ (1,0) [0|3] "" Vector__XXX
SG_ TrnsmPreDefinedRngLmtIndictr : 58|2@1+ (1,0) [0|3] "" Vector__XXX
SG_ TransmissionCoastModeIndicator : 60|2@1+ (1,0) [0|3] "" Vector__XXX

BO_ 2566802430 TCFG2: 8 Vector__XXX
SG_ TransmissionTorqueLimit : 0|16@1+ (1,0) [0|64255] "Nm" Vector__XXX
SG_ TransmissionReferenceTorque : 16|16@1+ (1,0) [0|64255] "Nm" Vector__XXX
SG_ TrnsmCommsFailureIdlTrqLmt : 32|8@1+ (1,-125) [-125|125] "%" Vector__XXX

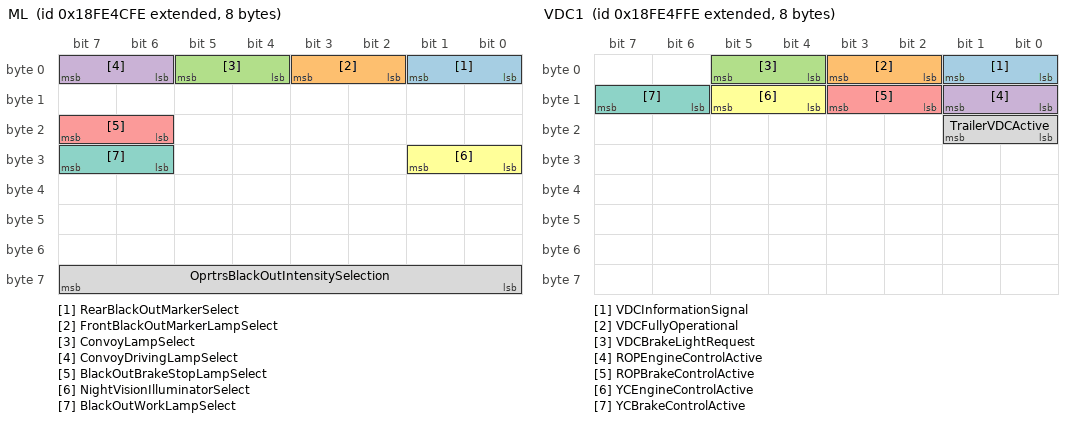
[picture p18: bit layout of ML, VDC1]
BO_ 2566802686 ML: 8 Vector__XXX
SG_ RearBlackOutMarkerSelect : 0|2@1+ (1,0) [0|3] "" Vector__XXX
SG_ FrontBlackOutMarkerLampSelect : 2|2@1+ (1,0) [0|3] "" Vector__XXX
SG_ ConvoyLampSelect : 4|2@1+ (1,0) [0|3] "" Vector__XXX
SG_ ConvoyDrivingLampSelect : 6|2@1+ (1,0) [0|3] "" Vector__XXX
SG_ BlackOutBrakeStopLampSelect : 22|2@1+ (1,0) [0|3] "" Vector__XXX
SG_ NightVisionIlluminatorSelect : 24|2@1+ (1,0) [0|3] "" Vector__XXX
SG_ BlackOutWorkLampSelect : 30|2@1+ (1,0) [0|3] "" Vector__XXX
SG_ OprtrsBlackOutIntensitySelection : 56|8@1+ (0.4,0) [0|100] "%" Vector__XXX

BO_ 2633911806 TAVG: 8 Vector__XXX
SG_ EngineTotalAverageFuelRate : 0|16@1+ (0.05,0) [0|3212.75] "l/h" Vector__XXX
SG_ EngineTotalAverageFuelEconomy : 16|16@1+ (0.001953125,0) [0|125.498046875] "km/l" Vector__XXX

BO_ 2566803198 DC1: 8 Vector__XXX
SG_ PositionOfDoors : 0|4@1+ (1,0) [0|15] "" Vector__XXX
SG_ RampWheelChairLiftPosition : 4|2@1+ (1,0) [0|3] "" Vector__XXX
SG_ Status2OfDoors : 6|2@1+ (1,0) [0|3] "" Vector__XXX

BO_ 2566803454 VDC1: 8 Vector__XXX
SG_ VDCInformationSignal : 0|2@1+ (1,0) [0|3] "" Vector__XXX
SG_ VDCFullyOperational : 2|2@1+ (1,0) [0|3] "" Vector__XXX
SG_ VDCBrakeLightRequest : 4|2@1+ (1,0) [0|3] "" Vector__XXX
SG_ ROPEngineControlActive : 8|2@1+ (1,0) [0|3] "" Vector__XXX
SG_ ROPBrakeControlActive : 10|2@1+ (1,0) [0|3] "" Vector__XXX
SG_ YCEngineControlActive : 12|2@1+ (1,0) [0|3] "" Vector__XXX
SG_ YCBrakeControlActive : 14|2@1+ (1,0) [0|3] "" Vector__XXX
SG_ TrailerVDCActive : 16|2@1+ (1,0) [0|3] "" Vector__XXX

BO_ 2566803710 BT1: 8 Vector__XXX
SG_ Battery1Temperature : 0|8@1+ (1,-40) [-40|210] "deg C" Vector__XXX
SG_ Battery2Temperature : 8|8@1+ (1,-40) [-40|210] "deg C" Vector__XXX
SG_ SLIBattery3Temperature : 16|8@1+ (1,-40) [-40|210] "deg C" Vector__XXX
SG_ SLIBattery4Temperature : 24|8@1+ (1,-40) [-40|210] "deg C" Vector__XXX

BO_ 2566803966 ACC2: 8 Vector__XXX
SG_ ACCUsageDemand : 0|2@1+ (1,0) [0|3] "" Vector__XXX
SG_ RequestedACCDistanceMode : 5|3@1+ (1,0) [0|7] "" Vector__XXX

BO_ 2566804222 VEP3: 8 Vector__XXX
SG_ AlternatorCurrent : 0|16@1+ (0.05,-1600) [-1600|1612.75] "A" Vector__XXX
SG_ NetBatteryCurrent : 16|16@1+ (0.05,-1600) [-1600|1612.75] "A" Vector__XXX
SG_ SLIBattery2NetCurrent : 32|16@1+ (0.05,-1600) [-1600|1612.75] "A" Vector__XXX

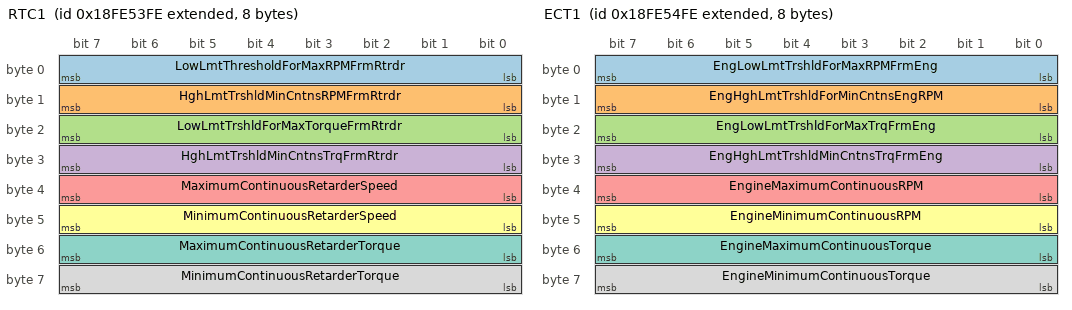
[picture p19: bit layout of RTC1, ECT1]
BO_ 2566804478 RTC1: 8 Vector__XXX
SG_ LowLmtThresholdForMaxRPMFrmRtrdr : 0|8@1+ (32,0) [0|8000] "rpm" Vector__XXX
SG_ HghLmtTrshldMinCntnsRPMFrmRtrdr : 8|8@1+ (32,0) [0|8000] "rpm" Vector__XXX
SG_ LowLmtTrshldForMaxTorqueFrmRtrdr : 16|8@1+ (1,-125) [-125|125] "%" Vector__XXX
SG_ HghLmtTrshldMinCntnsTrqFrmRtrdr : 24|8@1+ (1,-125) [-125|125] "%" Vector__XXX
SG_ MaximumContinuousRetarderSpeed : 32|8@1+ (32,0) [0|8000] "rpm" Vector__XXX
SG_ MinimumContinuousRetarderSpeed : 40|8@1+ (32,0) [0|8000] "rpm" Vector__XXX
SG_ MaximumContinuousRetarderTorque : 48|8@1+ (1,-125) [-125|125] "%" Vector__XXX
SG_ MinimumContinuousRetarderTorque : 56|8@1+ (1,-125) [-125|125] "%" Vector__XXX

BO_ 2566804734 ECT1: 8 Vector__XXX
SG_ EngLowLmtTrshldForMaxRPMFrmEng : 0|8@1+ (32,0) [0|8000] "rpm" Vector__XXX
SG_ EngHghLmtTrshldForMinCntnsEngRPM : 8|8@1+ (32,0) [0|8000] "rpm" Vector__XXX
SG_ EngLowLmtTrshldForMaxTrqFrmEng : 16|8@1+ (1,-125) [-125|125] "%" Vector__XXX
SG_ EngHghLmtTrshldMinCntnsTrqFrmEng : 24|8@1+ (1,-125) [-125|125] "%" Vector__XXX
SG_ EngineMaximumContinuousRPM : 32|8@1+ (32,0) [0|8000] "rpm" Vector__XXX
SG_ EngineMinimumContinuousRPM : 40|8@1+ (32,0) [0|8000] "rpm" Vector__XXX
SG_ EngineMaximumContinuousTorque : 48|8@1+ (1,-125) [-125|125] "%" Vector__XXX
SG_ EngineMinimumContinuousTorque : 56|8@1+ (1,-125) [-125|125] "%" Vector__XXX

BO_ 2566804990 GFD: 8 Vector__XXX
SG_ SpecificHeatRatio : 0|16@1+ (0.001,0) [0|64.255] "" Vector__XXX
SG_ ReferenceEngineGasMassFlowRate : 16|16@1+ (0.05,0) [0|3212.75] "kg/h" Vector__XXX
SG_ FuelEnergyContent : 32|16@1+ (0.00390625,0) [0|250.996] "MJ/Nm^3" Vector__XXX

CM_ BO_ 2566751742 "Engine Fluid Level/Pressure 8";
CM_ BO_ 2566751998 "Engine Fluid Level/Pressure 7";
CM_ BO_ 2566752254 "Engine Fluid Level/Pressure 6";
CM_ BO_ 2566752510 "Engine Fluid Level/Pressure 5";
CM_ BO_ 2566752766 "Vehicle Direction/Speed 2";
CM_ BO_ 2633861886 "SAE J2012 DTC Display";
CM_ BO_ 2566753278 "Aftertreatment 2 Gas Parameters";
CM_ BO_ 2566753534 "Aftertreatment 1 Gas Parameters";
CM_ BO_ 2566753790 "Utility Total AC Reactive Energy";
CM_ BO_ 2566754046 "Generator Total AC Reactive Energy";
CM_ BO_ 2566754302 "Generator Total AC Percent Power";
CM_ BO_ 2566754558 "Advertised Engine Torque Curve";
CM_ BO_ 2566754814 "AC Switching Device Status";
CM_ BO_ 2365428478 "Engine Operating Information";
CM_ BO_ 2365428734 "Generator Control 1";
CM_ BO_ 2566755582 "Electronic Engine Controller 7";
CM_ BO_ 2566755838 "Transmission Fluids 2";
CM_ BO_ 2566756094 "Fuel Information 2 (Liquid)";
CM_ BO_ 2566756350 "Fuel Information 3 (Liquid)";
CM_ BO_ 2566756606 "Aftertreatment 1 Historical Information 1";
CM_ BO_ 2566756862 "Aftertreatment 2 Historical information 1";
CM_ BO_ 2566757374 "Aftertreatment 1 Diesel Exhaust Fluid Information 1";
CM_ BO_ 2566757630 "Sensor Electrical Power #2";
CM_ BO_ 2566757886 "Sensor Electrical Power #1";
CM_ BO_ 2566758142 "Aftertreatment 2 Air Control 1";
CM_ BO_ 2566758398 "Aftertreatment 1 Air Control 1";
CM_ BO_ 2566758654 "Aftertreatment 2 Fuel Control 1";
CM_ BO_ 2566758910 "Aftertreatment 1 Fuel Control 1";
CM_ BO_ 2432541438 "Fuel Information 3 (Gaseous)";
CM_ BO_ 2432541694 "Electronic Engine Controller 6";
CM_ BO_ 2566759678 "PTO Drive Engagement";
CM_ BO_ 2566759934 "Door Control 2";
CM_ BO_ 2365433598 "Voltage Regulator Excitation Status";
CM_ BO_ 2633869310 "Voltage Regulator Operating Mode";
CM_ BO_ 2566760702 "Wireless Communications Message 2";
CM_ BO_ 2566760958 "Wireless Communications Message 1";
CM_ BO_ 2566761214 "Engine Fluid Level/Pressure 4";
CM_ BO_ 2566761726 "Engine Fuel Information";
CM_ BO_ 2566761982 "Request For Complete Configurable Message Set";
CM_ BO_ 2566762238 "Fifth Wheel Smart Systems 2";
CM_ BO_ 2566762494 "Aftertreatment 2 Intermediate Gas";
CM_ BO_ 2566762750 "Aftertreatment 2 Outlet Gas 2";
CM_ BO_ 2566763006 "Aftertreatment 2 Intake Gas 2";
CM_ BO_ 2566763262 "Aftertreatment 1 Intermediate Gas";
CM_ BO_ 2566763518 "Aftertreatment 1 Outlet Gas 2";
CM_ BO_ 2566763774 "Aftertreatment 1 Intake Gas 2";
CM_ BO_ 2566764030 "Emission-Related Previously MIL-On Diagnostic Trouble Codes";
CM_ BO_ 2566764286 "SPN Support";
CM_ BO_ 2566764542 "Expanded Freeze Frame";
CM_ BO_ 2566764798 "Diagnostic Readiness 3";
CM_ BO_ 2566765054 "Tire Pressure Reference Information";
CM_ BO_ 2566765310 "Farebox Status";
CM_ BO_ 2566765566 "Farebox Point of Sale";
CM_ BO_ 2566765822 "Farebox Service Detail";
CM_ BO_ 2566766078 "Signal Preemption";
CM_ BO_ 2566766334 "Transit Route";
CM_ BO_ 2566766590 "Transit Milepost";
CM_ BO_ 2566766846 "Passenger Counter";
CM_ BO_ 2566767102 "Engine Fluid Level/Pressure 3";
CM_ BO_ 2566767358 "Electronic Engine Controller 14";
CM_ BO_ 2566767614 "Electronic Engine Controller 15";
CM_ BO_ 2566767870 "Electronic Brake Controller 5";
CM_ BO_ 2566768126 "ECU Identification Information";
CM_ BO_ 2566768382 "Cold Start Aids";
CM_ BO_ 2566768638 "Off-Highway Engine Control Selection States";
CM_ BO_ 2566768894 "Operator Primary Intermediate Speed Control state";
CM_ BO_ 2633878014 "Electronic Control Module Information";
CM_ BO_ 2566769406 "Intermediate Speed Control";
CM_ BO_ 2566769662 "Off-Highway Engine Control Selection";
CM_ BO_ 2365443326 "Operators External Light Controls Message";
CM_ BO_ 2566770174 "Operator Wiper and Washer Controls Message";
CM_ BO_ 2566770430 "ISO 11783: Working Set Member Message (Obsolete - See PGN 65088)";
CM_ BO_ 2566770686 "ISO 11783: Working Set Master Message  (Obsolete - See PGN 65089)";
CM_ BO_ 2566770942 "Intake/Exhaust Conditions 2";
CM_ BO_ 2633880062 "FMS-standard Interface Identity/Capabilities";
CM_ BO_ 2566771454 "ECU Performance";
CM_ BO_ 2566771710 "Turbocharger Information 6";
CM_ BO_ 2566771966 "Cab Message 3";
CM_ BO_ 2566772222 "Electronic Engine Controller 5";
CM_ BO_ 2365445886 "Basic Joystick Message 1";
CM_ BO_ 2365446142 "Extended Joystick Message 1";
CM_ BO_ 2365446398 "Basic Joystick Message 2";
CM_ BO_ 2365446654 "Extended Joystick Message 2";
CM_ BO_ 2365446910 "Basic Joystick Message 3";
CM_ BO_ 2365447166 "Extended Joystick Message 3";
CM_ BO_ 2566774014 "Marine Control Information";
CM_ BO_ 2633883646 "Front Wheel Drive Status";
CM_ BO_ 2566775038 "Ambient Conditions 2";
CM_ BO_ 2566775294 "Cab Climate System Information 1";
CM_ BO_ 2566775550 "Supply Pressure Demand";
CM_ BO_ 2566775806 "Equipment Operation and Control";
CM_ BO_ 2566776062 "Equipment Performance Data";
CM_ BO_ 2566776318 "Maximum Vehicle Speed Limit Status";
CM_ BO_ 2365449982 "Hydraulic Braking System";
CM_ BO_ 2365450238 "Bus #1/Utility Sync Check Status";
CM_ BO_ 2365450494 "Bus #1/Generator Sync Check Status";
CM_ BO_ 2365450750 "Bus #1 Phase C  Basic AC Quantities";
CM_ BO_ 2365451006 "Bus #1 Phase B  Basic AC Quantities";
CM_ BO_ 2365451262 "Bus #1 Phase A  Basic AC Quantities";
CM_ BO_ 2365451518 "Bus #1 Average Basic AC Quantities";
CM_ BO_ 2365451774 "Utility Total AC Energy";
CM_ BO_ 2365452030 "Utility Phase C AC Reactive Power";
CM_ BO_ 2365452286 "Utility Phase C AC Power";
CM_ BO_ 2365452542 "Utility Phase C AC Basic Quantities";
CM_ BO_ 2365452798 "Utility Phase B AC Reactive Power";
CM_ BO_ 2365453054 "Utility Phase B AC Power";
CM_ BO_ 2365453310 "Utility Phase B AC Basic Quantities";
CM_ BO_ 2365453566 "Utility Phase A AC Reactive Power";
CM_ BO_ 2365453822 "Utility Phase A AC Power";
CM_ BO_ 2365454078 "Utility Phase A Basic AC Quantities";
CM_ BO_ 2365454334 "Utility Total AC Reactive Power";
CM_ BO_ 2365454590 "Utility Total AC Power";
CM_ BO_ 2365454846 "Utility Average Basic AC Quantities";
CM_ BO_ 2365455102 "Generator Total AC Energy";
CM_ BO_ 2365455358 "Generator Phase C AC Reactive Power";
CM_ BO_ 2365455614 "Generator Phase C AC Power";
CM_ BO_ 2365455870 "Generator Phase C Basic AC Quantities";
CM_ BO_ 2365456126 "Generator Phase B AC Reactive Power";
CM_ BO_ 2365456382 "Generator Phase B AC Power";
CM_ BO_ 2365456638 "Generator Phase B Basic AC Quantities";
CM_ BO_ 2365456894 "Generator Phase A AC Reactive Power";
CM_ BO_ 2365457150 "Generator Phase A AC Power";
CM_ BO_ 2365457406 "Generator Phase A Basic AC Quantities";
CM_ BO_ 2365457662 "Generator Total AC Reactive Power";
CM_ BO_ 2365457918 "Generator Total AC Power";
CM_ BO_ 2365458174 "Generator Average Basic AC Quantities";
CM_ BO_ 2566785022 "Exhaust Temperature";
CM_ BO_ 2566785278 "ISO 11783-7: Required Tractor Facilities message";
CM_ BO_ 2566785534 "ISO 11783-7: Tractor Facilities response message";
CM_ BO_ 2566785790 "ISO 11783-7: Implement Remote Control Command Tractor Response";
CM_ BO_ 2566786046 "ISO 11783-7: Implement Remote Control Command";
CM_ BO_ 2566786302 "ISO 11783: Working Set Member";
CM_ BO_ 2566786558 "ISO 11783: Working Set Master";
CM_ BO_ 2566786814 "ISO 11783-7: Response for Repetition Rate (Obsolete)";
CM_ BO_ 2566787070 "ISO 11783-7: Language Command";
CM_ BO_ 2566787326 "ISO 11783-7: Auxiliary Valve Number 0 Estimated Flow";
CM_ BO_ 2566787582 "ISO 11783-7: Auxiliary Valve Number 1 Estimated Flow";
CM_ BO_ 2566787838 "ISO 11783-7: Auxiliary Valve Number 2 Estimated Flow";
CM_ BO_ 2566788094 "ISO 11783-7: Auxiliary Valve Number 3 Estimated Flow";
CM_ BO_ 2566788350 "ISO 11783-7: Auxiliary Valve Number 4 Estimated Flow";
CM_ BO_ 2566788606 "ISO 11783-7: Auxiliary Valve Number 5 Estimated Flow";
CM_ BO_ 2566788862 "ISO 11783-7: Auxiliary Valve Number 6 Estimated Flow";
CM_ BO_ 2566789118 "ISO 11783-7: Auxiliary Valve Number 7 Estimated Flow";
CM_ BO_ 2566789374 "ISO 11783-7: Auxiliary Valve Number 8 Estimated Flow";
CM_ BO_ 2566789630 "ISO 11783-7: Auxiliary Valve Number 9 Estimated Flow";
CM_ BO_ 2566789886 "ISO 11783-7: Auxiliary Valve Number 10 Estimated Flow";
CM_ BO_ 2566790142 "ISO 11783-7: Auxiliary Valve Number 11 Estimated Flow";
CM_ BO_ 2566790398 "ISO 11783-7: Auxiliary Valve Number 12 Estimated Flow";
CM_ BO_ 2566790654 "ISO 11783-7: Auxiliary Valve Number 13 Estimated Flow";
CM_ BO_ 2566790910 "ISO 11783-7: Auxiliary Valve Number 14 Estimated Flow";
CM_ BO_ 2566791166 "ISO 11783-7: Auxiliary Valve Number 15 Estimated Flow";
CM_ BO_ 2566791422 "ISO 11783-7: Auxiliary Valve Number 0 Measured Flow";
CM_ BO_ 2566791678 "ISO 11783-7: Auxiliary Valve Number 1 Measured Flow";
CM_ BO_ 2566791934 "ISO 11783-7: Auxiliary Valve Number 2 Measured Flow";
CM_ BO_ 2566792190 "ISO 11783-7: Auxiliary Valve Number 3 Measured Flow";
CM_ BO_ 2566792446 "ISO 11783-7: Auxiliary Valve Number 4 Measured Flow";
CM_ BO_ 2566792702 "ISO 11783-7: Auxiliary Valve Number 5 Measured Flow";
CM_ BO_ 2566792958 "ISO 11783-7: Auxiliary Valve Number 6 Measured Flow";
CM_ BO_ 2566793214 "ISO 11783-7: Auxiliary Valve Number 7 Measured Flow";
CM_ BO_ 2566793470 "ISO 11783-7: Auxiliary Valve Number 8 Measured Flow";
CM_ BO_ 2566793726 "ISO 11783-7: Auxiliary Valve Number 9 Measured Flow";
CM_ BO_ 2566793982 "ISO 11783-7: Auxiliary Valve Number 10 Measured Flow";
CM_ BO_ 2566794238 "ISO 11783-7: Auxiliary Valve Number 11 Measured Flow";
CM_ BO_ 2566794494 "ISO 11783-7: Auxiliary Valve Number 12 Measured Flow";
CM_ BO_ 2566794750 "ISO 11783-7: Auxiliary Valve Number 13 Measured Flow";
CM_ BO_ 2566795006 "ISO 11783-7: Auxiliary Valve Number 14 Measured Flow";
CM_ BO_ 2566795262 "ISO 11783-7: Auxiliary Valve Number 15 Measured Flow";
CM_ BO_ 2566795518 "ISO 11783-7: Auxiliary Valve Number 0 Command";
CM_ BO_ 2566795774 "ISO 11783-7: Auxiliary Valve Number 1 Command";
CM_ BO_ 2566796030 "ISO 11783-7: Auxiliary Valve Number 2 Command";
CM_ BO_ 2566796286 "ISO 11783-7: Auxiliary Valve Number 3 Command";
CM_ BO_ 2566796542 "ISO 11783-7: Auxiliary Valve Number 4 Command";
CM_ BO_ 2566796798 "ISO 11783-7: Auxiliary Valve Number 5 Command";
CM_ BO_ 2566797054 "ISO 11783-7: Auxiliary Valve Number 6 Command";
CM_ BO_ 2566797310 "ISO 11783-7: Auxiliary Valve Number 7 Command";
CM_ BO_ 2566797566 "ISO 11783-7: Auxiliary Valve Number 8 Command";
CM_ BO_ 2566797822 "ISO 11783-7: Auxiliary Valve Number 9 Command";
CM_ BO_ 2566798078 "ISO 11783-7: Auxiliary Valve Number 10 Command";
CM_ BO_ 2566798334 "ISO 11783-7: Auxiliary Valve Number 11 Command";
CM_ BO_ 2566798590 "ISO 11783-7: Auxiliary Valve Number 12 Command";
CM_ BO_ 2566798846 "ISO 11783-7: Auxiliary Valve Number 13 Command";
CM_ BO_ 2566799102 "ISO 11783-7: Auxiliary Valve Number 14 Command";
CM_ BO_ 2566799358 "ISO 11783-7: Auxiliary Valve Number 15 Command";
CM_ BO_ 2566799614 "Lighting Data";
CM_ BO_ 2365473278 "Lighting Command";
CM_ BO_ 2566800126 "ISO 11783-7: Hitch and PTO Commands";
CM_ BO_ 2566800382 "ISO 11783-7: Primary or Rear Power Take off Output Shaft";
CM_ BO_ 2566800638 "ISO 11783-7: Secondary or Front Power Take off Output Shaft";
CM_ BO_ 2566800894 "ISO 11783-7: Primary or Rear Hitch Status";
CM_ BO_ 2566801150 "ISO 11783-7: Secondary or Front Hitch Status";
CM_ BO_ 2566801406 "ISO 11783-7: Maintain Power";
CM_ BO_ 2566801662 "ISO 11783-7: Wheel-based Speed and Distance";
CM_ BO_ 2566801918 "ISO 11783-7: Ground-based Speed and Distance";
CM_ BO_ 2566802174 "Electronic Transmission Controller 7";
CM_ BO_ 2566802430 "Transmission Configuration 2";
CM_ BO_ 2566802686 "Military Lighting Command";
CM_ BO_ 2633911806 "Total Averaged Information";
CM_ BO_ 2566803198 "Door Control 1";
CM_ BO_ 2566803454 "Vehicle Dynamic Stability Control 1";
CM_ BO_ 2566803710 "Battery Temperature";
CM_ BO_ 2566803966 "Adaptive Cruise Control, Operator Input";
CM_ BO_ 2566804222 "Vehicle Electrical Power 3";
CM_ BO_ 2566804478 "Retarder Continuous Torque & Speed Limit";
CM_ BO_ 2566804734 "Engine Continuous Torque & Speed Limit";
CM_ BO_ 2566804990 "Gaseous Fuel Properties";
BA_DEF_ BO_  "GenMsgCycleTime" INT 0 65535;
BA_DEF_ SG_  "SigType" ENUM "Default","Range","RangeSigned","ASCII","Discrete","Control","ReferencePGN","DTC","StringDelimiter","StringLength","StringLengthControl","MessageCounter","MessageChecksum";
BA_DEF_DEF_  "GenMsgCycleTime" 0;
BA_DEF_DEF_  "SigType" "Default";
BA_ "GenMsgCycleTime" BO_ 2566751742 500;
BA_ "GenMsgCycleTime" BO_ 2566751998 500;
BA_ "GenMsgCycleTime" BO_ 2566752254 500;
BA_ "GenMsgCycleTime" BO_ 2566752510 500;
BA_ "GenMsgCycleTime" BO_ 2566753278 500;
BA_ "GenMsgCycleTime" BO_ 2566753534 500;
BA_ "GenMsgCycleTime" BO_ 2566753790 250;
BA_ "GenMsgCycleTime" BO_ 2566754046 250;
BA_ "GenMsgCycleTime" BO_ 2566754302 250;
BA_ "GenMsgCycleTime" BO_ 2566754814 250;
BA_ "GenMsgCycleTime" BO_ 2365428478 250;
BA_ "GenMsgCycleTime" BO_ 2365428734 100;
BA_ "GenMsgCycleTime" BO_ 2566755582 100;
BA_ "GenMsgCycleTime" BO_ 2566755838 1000;
BA_ "GenMsgCycleTime" BO_ 2566756094 1000;
BA_ "GenMsgCycleTime" BO_ 2566756350 1000;
BA_ "GenMsgCycleTime" BO_ 2566757374 1000;
BA_ "GenMsgCycleTime" BO_ 2566757630 1000;
BA_ "GenMsgCycleTime" BO_ 2566757886 1000;
BA_ "GenMsgCycleTime" BO_ 2566758142 500;
BA_ "GenMsgCycleTime" BO_ 2566758398 500;
BA_ "GenMsgCycleTime" BO_ 2566758654 500;
BA_ "GenMsgCycleTime" BO_ 2566758910 500;
BA_ "GenMsgCycleTime" BO_ 2432541438 500;
BA_ "GenMsgCycleTime" BO_ 2432541694 100;
BA_ "GenMsgCycleTime" BO_ 2566759678 100;
BA_ "GenMsgCycleTime" BO_ 2566759934 100;
BA_ "GenMsgCycleTime" BO_ 2365433598 100;
BA_ "GenMsgCycleTime" BO_ 2633869310 1000;
BA_ "GenMsgCycleTime" BO_ 2566761214 500;
BA_ "GenMsgCycleTime" BO_ 2566762494 500;
BA_ "GenMsgCycleTime" BO_ 2566762750 500;
BA_ "GenMsgCycleTime" BO_ 2566763006 500;
BA_ "GenMsgCycleTime" BO_ 2566763262 500;
BA_ "GenMsgCycleTime" BO_ 2566763518 500;
BA_ "GenMsgCycleTime" BO_ 2566763774 500;
BA_ "GenMsgCycleTime" BO_ 2566767102 500;
BA_ "GenMsgCycleTime" BO_ 2566767870 100;
BA_ "GenMsgCycleTime" BO_ 2566768638 500;
BA_ "GenMsgCycleTime" BO_ 2566768894 1000;
BA_ "GenMsgCycleTime" BO_ 2566769406 1000;
BA_ "GenMsgCycleTime" BO_ 2566769662 500;
BA_ "GenMsgCycleTime" BO_ 2365443326 1000;
BA_ "GenMsgCycleTime" BO_ 2566770174 200;
BA_ "GenMsgCycleTime" BO_ 2566770942 500;
BA_ "GenMsgCycleTime" BO_ 2633880062 10000;
BA_ "GenMsgCycleTime" BO_ 2566771710 1000;
BA_ "GenMsgCycleTime" BO_ 2566771966 10000;
BA_ "GenMsgCycleTime" BO_ 2365445886 100;
BA_ "GenMsgCycleTime" BO_ 2365446142 100;
BA_ "GenMsgCycleTime" BO_ 2365446398 100;
BA_ "GenMsgCycleTime" BO_ 2365446654 100;
BA_ "GenMsgCycleTime" BO_ 2365446910 100;
BA_ "GenMsgCycleTime" BO_ 2365447166 100;
BA_ "GenMsgCycleTime" BO_ 2566774014 1000;
BA_ "GenMsgCycleTime" BO_ 2633883646 500;
BA_ "GenMsgCycleTime" BO_ 2566775038 1000;
BA_ "GenMsgCycleTime" BO_ 2566775294 1000;
BA_ "GenMsgCycleTime" BO_ 2566775550 1000;
BA_ "GenMsgCycleTime" BO_ 2566775806 250;
BA_ "GenMsgCycleTime" BO_ 2566776062 500;
BA_ "GenMsgCycleTime" BO_ 2566776318 1000;
BA_ "GenMsgCycleTime" BO_ 2365449982 100;
BA_ "GenMsgCycleTime" BO_ 2365450238 100;
BA_ "GenMsgCycleTime" BO_ 2365450494 100;
BA_ "GenMsgCycleTime" BO_ 2365450750 100;
BA_ "GenMsgCycleTime" BO_ 2365451006 100;
BA_ "GenMsgCycleTime" BO_ 2365451262 100;
BA_ "GenMsgCycleTime" BO_ 2365451518 100;
BA_ "GenMsgCycleTime" BO_ 2365451774 100;
BA_ "GenMsgCycleTime" BO_ 2365452030 100;
BA_ "GenMsgCycleTime" BO_ 2365452286 100;
BA_ "GenMsgCycleTime" BO_ 2365452542 100;
BA_ "GenMsgCycleTime" BO_ 2365452798 100;
BA_ "GenMsgCycleTime" BO_ 2365453054 100;
BA_ "GenMsgCycleTime" BO_ 2365453310 100;
BA_ "GenMsgCycleTime" BO_ 2365453566 100;
BA_ "GenMsgCycleTime" BO_ 2365453822 100;
BA_ "GenMsgCycleTime" BO_ 2365454078 100;
BA_ "GenMsgCycleTime" BO_ 2365454334 100;
BA_ "GenMsgCycleTime" BO_ 2365454590 100;
BA_ "GenMsgCycleTime" BO_ 2365454846 100;
BA_ "GenMsgCycleTime" BO_ 2365455102 100;
BA_ "GenMsgCycleTime" BO_ 2365455358 100;
BA_ "GenMsgCycleTime" BO_ 2365455614 100;
BA_ "GenMsgCycleTime" BO_ 2365455870 100;
BA_ "GenMsgCycleTime" BO_ 2365456126 100;
BA_ "GenMsgCycleTime" BO_ 2365456382 100;
BA_ "GenMsgCycleTime" BO_ 2365456638 100;
BA_ "GenMsgCycleTime" BO_ 2365456894 100;
BA_ "GenMsgCycleTime" BO_ 2365457150 100;
BA_ "GenMsgCycleTime" BO_ 2365457406 100;
BA_ "GenMsgCycleTime" BO_ 2365457662 100;
BA_ "GenMsgCycleTime" BO_ 2365457918 100;
BA_ "GenMsgCycleTime" BO_ 2365458174 100;
BA_ "GenMsgCycleTime" BO_ 2566785022 500;
BA_ "GenMsgCycleTime" BO_ 2365473278 1000;
BA_ "GenMsgCycleTime" BO_ 2566802174 100;
BA_ "GenMsgCycleTime" BO_ 2566802430 5000;
BA_ "GenMsgCycleTime" BO_ 2566802686 500;
BA_ "GenMsgCycleTime" BO_ 2566803198 100;
BA_ "GenMsgCycleTime" BO_ 2566803454 100;
BA_ "GenMsgCycleTime" BO_ 2566803710 1000;
BA_ "GenMsgCycleTime" BO_ 2566803966 250;
BA_ "GenMsgCycleTime" BO_ 2566804222 100;
BA_ "GenMsgCycleTime" BO_ 2566804478 5000;
BA_ "GenMsgCycleTime" BO_ 2566804734 5000;
BA_ "SigType" SG_ 2633861886 J2012DTC 3;
BA_ "SigType" SG_ 2566766590 MilepostIdentification 3;
BA_ "SigType" SG_ 2566768126 ECUHardwareID 3;
BA_ "SigType" SG_ 2566768126 ECUDateOfManufacture 3;
BA_ "SigType" SG_ 2633880062 FMSStandardSWVersionSupported 3;
BA_ "SigType" SG_ 2566787070 LanguageCodeCommand 3;
VAL_ 2633861886 J2012DTCStatus 0 "DTC is previously active" 1 "DTC is active" ;
VAL_ 2566754558 AETCDataCollectionStandard 0 "SAE J1995" 1 "Not Defined" 15 "Not Available" ;
VAL_ 2566754814 GeneratorCircuitBreakerStatus 0 "Open" 1 "Closed" 2 "Locked Out" 3 "Transitioning to Open state" 4 "Transitioning to Closed state" 5 "Available for SAE assignment" 6 "Error" 7 "Not Available" ;
VAL_ 2566754814 UtilityCircuitBreakerStatus 0 "Open" 1 "Closed" 2 "Locked Out" 3 "Transitioning to Open state" 4 "Transitioning to Closed state" 5 "Available for SAE assignment" 6 "Error" 7 "Not Available" ;
VAL_ 2566754814 AutomaticTransferSwitchStatus 0 "Normal position" 1 "Emergency position" 2 "Available for SAE assignment" 3 "Transitioning to Normal position" 4 "Transitioning to Emergency position" 5 "Available for SAE assignment" 6 "Error" 7 "Not Available" ;
VAL_ 2566754814 EngineSpeedGovernorMode 0 "Isochronous Mode" 1 "Droop Mode" 2 "Error" 3 "Not Available" ;
VAL_ 2566754814 BusTieBreaker1 0 "Open" 1 "Closed" 2 "Locked Out" 3 "Transitioning to Open state" 4 "Transitioning to Closed state" 5 "Available for SAE assignment" 6 "Error" 7 "Not Available" ;
VAL_ 2566754814 BusTieBreaker2 0 "Open" 1 "Closed" 2 "Locked Out" 3 "Transitioning to Open state" 4 "Transitioning to Closed state" 5 "Available for SAE assignment" 6 "Error" 7 "Not Available" ;
VAL_ 2566754814 PackageCircuitBreakerStatus 0 "Open" 1 "Closed" 2 "Locked Out" 3 "Transitioning to Open state" 4 "Transitioning to Closed state" 5 "Available for SAE assignment" 6 "Error" 7 "Not Available" ;
VAL_ 2566754814 StationaryInverterCircBrkrStatus 0 "Open" 1 "Closed" 2 "Locked Out" 3 "Transitioning to Open state" 4 "Transitioning to Closed state" 5 "Available for SAE assignment" 6 "Error" 7 "Not Available" ;
VAL_ 2365428478 EngineOperatingState 0 "Engine Stopped" 1 "Pre-Start" 2 "Starting" 3 "Warm-Up" 4 "Running" 5 "Cool-down" 6 "Engine Stopping" 7 "Post-Run" 8 "available for SAE assignment" 14 "<reserved>" 15 "not available" ;
VAL_ 2365428478 FuelPumpPrimerControl 0 "Deactivate" 1 "Activate" 2 "Reserved" 3 "Unavailable" ;
VAL_ 2365428478 EngineStarterMotorRelayControl 0 "Off" 1 "On" 2 "Reserved for SAE assignment" 3 "Don't care/take no action" ;
VAL_ 2365428478 EngineFuelShutoffVentControl 0 "Closed" 1 "Open" 2 "Reserved" 3 "Don't care / take no action" ;
VAL_ 2365428478 EngineFuelShutoff1Control 0 "Open (fuel supplied to engine)" 1 "Closed (no fuel supplied to engine)" 2 "Reserved" 3 "Don't care / take no action" ;
VAL_ 2365428478 EngineFuelShutoff2Control 0 "Open (fuel supplied to engine)" 1 "Closed (no fuel supplied to engine)" 2 "Reserved" 3 "Don't care / take no action" ;
VAL_ 2365428478 EngFuelShutoffValveLeakTestCtrl 0 "Off (reset / no test in process)" 1 "On (test in process / test complete)" 2 "Reserved" 3 "Don't care / take no action" ;
VAL_ 2365428478 EngineOilPrimingPumpControl 0 "Off" 1 "On" 2 "Reserved" 3 "unavailable" ;
VAL_ 2365428478 EngineOilPreHeaterControl 0 "Off" 1 "On" 2 "Reserved" 3 "Don't care / take no action" ;
VAL_ 2365428478 EngElectrclSystemPwrConservCtrl 0 "Off" 1 "On" 2 "Reserved" 3 "unavailable" ;
VAL_ 2365428478 EnginePreHeaterControl 0 "Off" 1 "On" 2 "Reserved" 3 "unavailable" ;
VAL_ 2365428478 EngineCoolantPumpControl 0 "Off" 1 "On" 2 "Reserved" 3 "Don't care / take no action" ;
VAL_ 2365428478 EngineControlledShutdownRequest 0 "Off" 1 "On" 2 "Reserved" 3 "Don't care / take no action" ;
VAL_ 2365428478 EngineEmrgncyShutdownIndication 0 "Off" 1 "On" 2 "Reserved" 3 "Don't care / take no action" ;
VAL_ 2365428478 EngColdAmbientElevatedIdleStatus 0 "No Idle Elevation Active" 1 "Idle Elevation Active" 2 "Reserved for SAE assignment" 3 "Unavailable" ;
VAL_ 2365428734 RequestedEngineControlMode 0 "Normal Engine Shutdown" 1 "Rapid Engine Shutdown" 2 "Emergency Engine Shutdown" 3 "Normal Engine Start" 4 "Rapid Engine Start" 5 "available for SAE assignment" 14 "<reserved>" 15 "Don't Care / Take No Action" ;
VAL_ 2365428734 GeneratorCtrlNotInAutoStartState 0 "Inactive" 1 "Active" 2 "Error" 3 "Not available" ;
VAL_ 2365428734 GenNotReadyToAutoParallelState 0 "Inactive" 1 "Active" 2 "Error" 3 "Not available" ;
VAL_ 2365428734 GeneratorGoverningSpeedCommand 0 "Rated Speed" 1 "Low Idle Speed" 2 "Reserved" 3 "Don't care / take no action" ;
VAL_ 2365428734 GeneratorFrequencySelection 0 "50 Hz" 1 "60 Hz" 2 "400 Hz" 3 "SAE Reserved" 14 "Unknown" 15 "Don't care /take no action" ;
VAL_ 2566755838 TrnsmOilFilterRestrictionSw 0 "No restriction" 1 "Restriction exists on oil filter" 2 "Error" 3 "Not available" ;
VAL_ 2566755838 TransmissionOilLevelSwitch 0 "Empty" 1 "Full or not empty" 2 "Error" 3 "Not available" ;
VAL_ 2566755838 TransmissionOverheatIndicator 0 "Transmission Overheat Indicator is off" 1 "Transmission Overheat Indicator is on continuously" 2 "Transmission Overheat Indicator is flashing" 3 "Not available" ;
VAL_ 2566755838 TransmissionOilLvl2CntdownTimer 0 "less than 1 minute" 1 "One minute" 2 "Two minutes" 3 "Three minutes" 4 "Four minutes" 5 "Five minutes" 6 "Six minutes" 7 "Seven minutes" 8 "Eight minutes" 9 "Nine minutes" 10 "Ten minutes" 11 "Eleven minutes" 12 "Twelve minutes" 13 "Thirteen minutes" 14 "Error" 15 "Not Available" ;
VAL_ 2566755838 TransmissionOilLvl2MeasureStatus 0 "Conditions valid for transmission oil level measurement" 1 "Conditions not valid - Settling timer still counting down" 2 "Conditions not valid - Transmission in gear" 3 "Conditions not valid - Transmission fluid temperature too low" 4 "Conditions not valid - Transmission fluid temperature too high" 5 "Conditions not valid - Vehicle moving" 6 "Conditions not valid - Vehicle not level" 7 "Conditions not valid - Engine speed too low" 8 "Conditions not valid - Engine speed too high" 9 "Conditions not valid - No request for reading" 10 "Not defined" 11 "Not defined" 12 "Not defined" 13 "Conditions not valid" 14 "Error" 15 "Not available" ;
VAL_ 2566757374 Aftrtrtmnt1DslExhstFluidProperty 0 "Urea concentration too high" 1 "Urea concentration too low" 2 "Fluid is diesel" 3 "Diesel exhaust fluid is proper mixture" 4 "Reserved for SAE assignment" 12 "Diesel exhaust fluid, but concentration cannot be determined" 13 "Not able to determine fluid property" 14 "Error with diesel exhaust fluid property detection" 15 "Not available" ;
VAL_ 2566758142 Aftertreatment2AirSystemRelay 0 "Not active" 1 "Active" 2 "Reserved for SAE assignment" 3 "Not available" ;
VAL_ 2566758142 Aftrtrtmnt2AtomizationAirActr 0 "Not active" 1 "Active" 2 "Reserved for SAE assignment" 3 "Not available" ;
VAL_ 2566758142 Aftertreatment2PurgeAirActuator 0 "Not active" 1 "Active" 2 "Reserved for SAE assignment" 3 "Not available" ;
VAL_ 2566758142 Aftertreatment2AirEnableActuator 0 "Not active" 1 "Active" 2 "Reserved for SAE assignment" 3 "Not available" ;
VAL_ 2566758398 Aftertreatment1AirSystemRelay 0 "Not active" 1 "Active" 2 "Reserved for SAE assignment" 3 "Not available" ;
VAL_ 2566758398 Aftrtrtmnt1AtomizationAirActr 0 "Not active" 1 "Active" 2 "Reserved for SAE assignment" 3 "Not available" ;
VAL_ 2566758398 Aftertreatment1PurgeAirActuator 0 "Not active" 1 "Active" 2 "Reserved for SAE assignment" 3 "Not available" ;
VAL_ 2566758398 Aftertreatment1AirEnableActuator 0 "Not active" 1 "Active" 2 "Reserved for SAE assignment" 3 "Not available" ;
VAL_ 2566758654 Aftertreatment2FuelDrainActuator 0 "Not active" 1 "Active" 2 "Reserved for SAE assignment" 3 "Not available" ;
VAL_ 2566758654 Aftertreatment2Ignition 0 "Not active" 1 "Active" 2 "Reserved for SAE assignment" 3 "Not available" ;
VAL_ 2566758654 Aftrtrtmnt2RegenerationStatus 0 "Not active" 1 "Active" 2 "Reserved for SAE assignment" 3 "Not available" ;
VAL_ 2566758654 Aftertreatment2FuelEnableActr 0 "Not active" 1 "Active" 2 "Reserved for SAE assignment" 3 "Not available" ;
VAL_ 2566758910 Aftertreatment1FuelDrainActuator 0 "Not active" 1 "Active" 2 "Reserved for SAE assignment" 3 "Not available" ;
VAL_ 2566758910 Aftertreatment1Ignition 0 "Not active" 1 "Active" 2 "Reserved for SAE assignment" 3 "Not available" ;
VAL_ 2566758910 Aftrtrtmnt1RegenerationStatus 0 "Not active" 1 "Active" 2 "Reserved for SAE assignment" 3 "Not available" ;
VAL_ 2566758910 Aftertreatment1FuelEnableActr 0 "Not active" 1 "Active" 2 "Reserved for SAE assignment" 3 "Not available" ;
VAL_ 2432541694 EngTurboCmprBypssActr1TempStat 0 "High Most severe" 1 "High Least severe" 2 "In Range" 3 "Low Least severe" 4 "Low Most severe" 5 "Not Defined" 6 "Error" 7 "Not available" ;
VAL_ 2566759678 EnblSwitchTransferCsOutptShftPTO 0 "Enable switch off - PTO operation not desired" 1 "Enable switch on - PTO operation desired" 2 "Error" 3 "Not available" ;
VAL_ 2566759678 EnblSwTransmissionOutptShftPTO 0 "Enable switch off - PTO operation not desired" 1 "Enable switch on - PTO operation desired" 2 "Error" 3 "Not available" ;
VAL_ 2566759678 EnblSwTransmissionInputShftPTO2 0 "Enable switch off - PTO operation not desired" 1 "Enable switch on - PTO operation desired" 2 "Error" 3 "Not available" ;
VAL_ 2566759678 EnblSwTransmissionInputShftPTO1 0 "Enable switch off - PTO operation not desired" 1 "Enable switch on - PTO operation desired" 2 "Error" 3 "Not available" ;
VAL_ 2566759678 EnableSwitchPTOEngineFlywheel 0 "Enable switch off - PTO operation not desired" 1 "Enable switch on - PTO operation desired" 2 "Error" 3 "Not available" ;
VAL_ 2566759678 EnableSwitchPTOEngineAccssryDrv1 0 "Enable switch off - PTO operation not desired" 1 "Enable switch on - PTO operation desired" 2 "Error" 3 "Not available" ;
VAL_ 2566759678 EnableSwitchPTOEngineAccssryDrv2 0 "Enable switch off - PTO operation not desired" 1 "Enable switch on - PTO operation desired" 2 "Error" 3 "Not available" ;
VAL_ 2566759678 EngmntConsntTrnsfrCsOutptShftPTO 0 "Consent not given" 1 "Consent given" 2 "Error" 3 "Not available" ;
VAL_ 2566759678 EngmntConsntTrnsmOutptShftPTO 0 "Consent not given" 1 "Consent given" 2 "Error" 3 "Not available" ;
VAL_ 2566759678 EngmntConsntTrnsmInputShftPTO2 0 "Consent not given" 1 "Consent given" 2 "Error" 3 "Not available" ;
VAL_ 2566759678 EngmntConsntTrnsmInputShftPTO1 0 "Consent not given" 1 "Consent given" 2 "Error" 3 "Not available" ;
VAL_ 2566759678 EngmntConsntPTOEngineFlywheel 0 "Consent not given" 1 "Consent given" 2 "Error" 3 "Not available" ;
VAL_ 2566759678 EngmntConsntPTOEngineAccssryDrv1 0 "Consent not given" 1 "Consent given" 2 "Error" 3 "Not available" ;
VAL_ 2566759678 EngmntConsntPTOEngineAccssryDrv2 0 "Consent not given" 1 "Consent given" 2 "Error" 3 "Not available" ;
VAL_ 2566759678 EngmntStatTransferCsOutptShftPTO 0 "Drive not engaged" 1 "Drive is engaged" 2 "Error" 3 "Not available" ;
VAL_ 2566759678 EngmntStatTrnsmOutptShftPTO 0 "Drive not engaged" 1 "Drive is engaged" 2 "Error" 3 "Not available" ;
VAL_ 2566759678 EngmntStatTrnsmInputShftPTO2 0 "Drive not engaged" 1 "Drive is engaged" 2 "Error" 3 "Not available" ;
VAL_ 2566759678 EngmntStatTrnsmInputShftPTO1 0 "Drive not engaged" 1 "Drive is engaged" 2 "Error" 3 "Not available" ;
VAL_ 2566759678 EngmntStatusPTOEngineFlywheel 0 "Drive not engaged" 1 "Drive engaged" 2 "Error" 3 "Not available" ;
VAL_ 2566759678 EngmntStatusPTOEngineAccssryDrv1 0 "Drive not engaged" 1 "Drive engaged" 2 "Error" 3 "Not available" ;
VAL_ 2566759678 EngmntStatusPTOEngineAccssryDrv2 0 "Drive not engaged" 1 "Drive engaged" 2 "Error" 3 "Not available" ;
VAL_ 2566759678 AtLeastOnePTOEngaged 0 "No PTO drive is engaged" 1 "At least one PTO drive is engaged" 2 "Error" 3 "Not available" ;
VAL_ 2566759934 LockStatusOfDoor1 0 "Unlocked" 1 "Locked" 2 "Error" 3 "Not available" ;
VAL_ 2566759934 OpenStatusOfDoor1 0 "Door closed" 1 "Door opened" 2 "Error" 3 "Not available" ;
VAL_ 2566759934 EnableStatusOfDoor1 0 "Door disabled" 1 "Door enabled" 2 "Error" 3 "Not available" ;
VAL_ 2566759934 LockStatusOfDoor2 0 "Unlocked" 1 "Locked" 2 "Error" 3 "Not available" ;
VAL_ 2566759934 OpenStatusOfDoor2 0 "Door closed" 1 "Door opened" 2 "Error" 3 "Not available" ;
VAL_ 2566759934 EnableStatusOfDoor2 0 "Door disabled" 1 "Door enabled" 2 "Error" 3 "Not available" ;
VAL_ 2566759934 LockStatusOfDoor3 0 "Unlocked" 1 "Locked" 2 "Error" 3 "Not available" ;
VAL_ 2566759934 OpenStatusOfDoor3 0 "Door closed" 1 "Door opened" 2 "Error" 3 "Not available" ;
VAL_ 2566759934 EnableStatusOfDoor3 0 "Door disabled" 1 "Door enabled" 2 "Error" 3 "Not available" ;
VAL_ 2566759934 LockStatusOfDoor4 0 "Unlocked" 1 "Locked" 2 "Error" 3 "Not available" ;
VAL_ 2566759934 OpenStatusOfDoor4 0 "Door closed" 1 "Door opened" 2 "Error" 3 "Not available" ;
VAL_ 2566759934 EnableStatusOfDoor4 0 "Door disabled" 1 "Door enabled" 2 "Error" 3 "Not available" ;
VAL_ 2566759934 LockStatusOfDoor5 0 "Unlocked" 1 "Locked" 2 "Error" 3 "Not available" ;
VAL_ 2566759934 OpenStatusOfDoor5 0 "Door closed" 1 "Door opened" 2 "Error" 3 "Not available" ;
VAL_ 2566759934 EnableStatusOfDoor5 0 "Door disabled" 1 "Door enabled" 2 "Error" 3 "Not available" ;
VAL_ 2566759934 LockStatusOfDoor6 0 "Unlocked" 1 "Locked" 2 "Error" 3 "Not available" ;
VAL_ 2566759934 OpenStatusOfDoor6 0 "Door closed" 1 "Door opened" 2 "Error" 3 "Not available" ;
VAL_ 2566759934 EnableStatusOfDoor6 0 "Door disabled" 1 "Door enabled" 2 "Error" 3 "Not available" ;
VAL_ 2566759934 LockStatusOfDoor7 0 "Unlocked" 1 "Locked" 2 "Error" 3 "Not available" ;
VAL_ 2566759934 OpenStatusOfDoor7 0 "Door closed" 1 "Door opened" 2 "Error" 3 "Not available" ;
VAL_ 2566759934 EnableStatusOfDoor7 0 "Door disabled" 1 "Door enabled" 2 "Error" 3 "Not available" ;
VAL_ 2566759934 LockStatusOfDoor8 0 "Unlocked" 1 "Locked" 2 "Error" 3 "Not available" ;
VAL_ 2566759934 OpenStatusOfDoor8 0 "Door closed" 1 "Door opened" 2 "Error" 3 "Not available" ;
VAL_ 2566759934 EnableStatusOfDoor8 0 "Door disabled" 1 "Door enabled" 2 "Error" 3 "Not available" ;
VAL_ 2566759934 LockStatusOfDoor9 0 "Unlocked" 1 "Locked" 2 "Error" 3 "Not available" ;
VAL_ 2566759934 OpenStatusOfDoor9 0 "Door closed" 1 "Door opened" 2 "Error" 3 "Not available" ;
VAL_ 2566759934 EnableStatusOfDoor9 0 "Door disabled" 1 "Door enabled" 2 "Error" 3 "Not available" ;
VAL_ 2566759934 LockStatusOfDoor10 0 "Unlocked" 1 "Locked" 2 "Error" 3 "Not available" ;
VAL_ 2566759934 OpenStatusOfDoor10 0 "Door closed" 1 "Door opened" 2 "Error" 3 "Not available" ;
VAL_ 2566759934 EnableStatusOfDoor10 0 "Door disabled" 1 "Door enabled" 2 "Error" 3 "Not available" ;
VAL_ 2633869310 VoltageRegulatorLoadCmpnstnMode 0 "load compensation disabled" 1 "Voltage droop compensation enabled" 2 "IR line drop compensation enabled" 3 "Reserved" 4 "Reserved" 5 "Reserved" 6 "Reserved" 7 "Not available" ;
VAL_ 2633869310 VltgRgltrVArPwrFactorOprtngMde 0 "VAr/Power Factor regulation disabled" 1 "Power factor regulation enabled" 2 "VAr regulation enabled" 3 "Reserved" 4 "Reserved" 5 "Reserved" 6 "Reserved" 7 "Not available" ;
VAL_ 2633869310 VltgRgltrUnderFreqCmpnstnEnbld 0 "Underfrequency compensation disabled" 1 "Underfrequency compensation enabled" 2 "Reserved" 3 "Not available" ;
VAL_ 2633869310 VoltageRegulatorSoftStartState 0 "Soft start is inactive" 1 "Soft start is active" 2 "Reserved" 3 "Not available" ;
VAL_ 2633869310 VoltageRegulatorEnabled 0 "Not regulating voltage" 1 "Regulating voltage" 2 "Reserved" 3 "Not available" ;
VAL_ 2566760702 NetworkTransceiverStatus2 0 "Off" 1 "On" 2 "Not Authorized to Operate on Network" 3 "Reserved for Future Assignment" 251 "Reserved" 254 "Error" 255 "Not Available" ;
VAL_ 2566760702 NetworkServiceStatus2 0 "Local Service" 1 "Roaming Service" 2 "Service not available" 3 "Not Authorized to Operate on Service" 4 "Reserved for Future Assignment" 251 "Reserved" 254 "Error" 255 "Not Available" ;
VAL_ 2566760702 NetworkAntennaStatus2 0 "Off" 1 "On" 2 "Reserved for Future Assignment" 251 "Reserved" 254 "Error" 255 "Not Available" ;
VAL_ 2566760702 WirelessCommNetworkType2 0 "Cellular network #1" 1 "Cellular network #2" 2 "Wireless LAN #1" 3 "Wireless LAN #2" 4 "Satellite network" 5 "Reserved for Future Assignment" 251 "Reserved" 254 "Error" 255 "Not Available" ;
VAL_ 2566760958 NetworkTransceiverStatus1 0 "Off" 1 "On" 2 "Not Authorized to Operate on Network" 3 "Reserved for Future Assignment" 251 "Reserved" 254 "Error" 255 "Not Available" ;
VAL_ 2566760958 NetworkServiceStatus1 0 "Local Service" 1 "Roaming Service" 2 "Service not available" 3 "Not Authorized to Operate on Service" 4 "Reserved for Future Assignment" 251 "Reserved" 254 "Error" 255 "Not Available" ;
VAL_ 2566760958 NetworkAntennaStatus1 0 "Off" 1 "On" 2 "Reserved for Future Assignment" 251 "Reserved" 254 "Error" 255 "Not Available" ;
VAL_ 2566760958 WirelessCommNetworkType1 0 "Cellular network #1" 1 "Cellular network #2" 2 "Wireless LAN #1" 3 "Wireless LAN #2" 4 "Satellite network" 5 "Reserved for Future Assignment" 251 "Reserved" 254 "Error" 255 "Not Available" ;
VAL_ 2566762238 FifthWheelErrorStatus 0 "Improper Couple" 1 "Locks Closed / No Kingpin at Startup" 2 "Kingpin / Locks Open at Startup" 3 "Not Used" 4 "Not Used" 5 "Coupling Sequence Error" 6 "Coupling Sequence Error / Kingpin" 7 "Coupling Timing Error" 8 "Kingpin Missing More Than 5 Seconds" 9 "Kingpin / Lock Open (Handle Pulled)" 10 "Not Used" 11 "Not Used" 12 "Not Used" 13 "Not Used" 14 "Not Used" 15 "Not available" ;
VAL_ 2566762238 FifthWheelLockRdyToCoupleIndictr 0 "Lock not open, not ready to couple" 1 "Lock open, ready to couple" 2 "Error" 3 "Not Available" ;
VAL_ 2566762238 FifthWheelLockCoupleStatIndictr 0 "Incomplete or bad couple" 1 "Successful couple detected" 2 "Error" 3 "Not Available" ;
VAL_ 2566762238 FifthWheelSliderLockIndicator 0 "Not Locked" 1 "Locked" 2 "Error" 3 "Not available" ;
VAL_ 2566764030 ProtectLamp 0 "Lamp Off" 1 "Lamp On" 2 "Reserved" 3 "Not available" ;
VAL_ 2566764030 AmberWarningLamp 0 "Lamp Off" 1 "Lamp On" 2 "Reserved" 3 "Not available" ;
VAL_ 2566764030 RedStopLamp 0 "Lamp Off" 1 "Lamp On" 2 "Reserved" 3 "Not available" ;
VAL_ 2566764030 MalfunctionIndicatorLamp 0 "Lamp Off" 1 "Lamp On" 2 "Short MIL for WWH OBD" 3 "Not available" ;
VAL_ 2566764030 FlashProtectLamp 0 "Slow Flash (1 Hz, 50 % duty cycle)" 1 "Fast Flash (2 Hz or faster, 50% duty cycle)" 2 "Reserved" 3 "Unavailable / Do Not Flash" ;
VAL_ 2566764030 FlashAmberWarningLamp 0 "Slow Flash (1 Hz, 50 % duty cycle)" 1 "Fast Flash (2 Hz or faster, 50% duty cycle)" 2 "Reserved" 3 "Unavailable / Do Not Flash" ;
VAL_ 2566764030 FlashRedStopLamp 0 "Slow Flash (1 Hz, 50 % duty cycle)" 1 "Fast Flash (2 Hz or faster, 50% duty cycle)" 2 "Reserved" 3 "Unavailable / Do Not Flash" ;
VAL_ 2566764030 FlashMalfunctionIndicatorLamp 0 "Slow Flash (1 Hz, 50 % duty cycle)" 1 "Fast Flash (2 Hz or faster, 50% duty cycle)" 2 "Class C DTC" 3 "Unavailable / Do Not Flash" ;
VAL_ 2566764030 SPNConversionMethod 0 "Convert SPN per Version 4" 1 "Convert SPN per Version 1, 2 or 3" ;
VAL_ 2566764542 SPNConversionMethod 0 "Convert SPN per Version 4" 1 "Convert SPN per Version 1, 2 or 3" ;
VAL_ 2566765310 FareboxEmergencyStatus 0 "Non-emergency condition" 1 "Emergency condition" 2 "Error Condition" 3 "Not available" ;
VAL_ 2566765310 FareboxAlarmIdentifier 0 "Voltage dropout" 1 "Voltage restored" 2 "Probe started" 3 "Probe completed" 4 "Cashbox removed" 5 "Cashbox restored" 6 "Cashbox door timeout" 7 "Cashbox opened" 8 "Insufficient fare accepted" 9 "Coinbox 75% full" 10 "Coinbox full" 11 "Currency box 75% full" 12 "Currency box less than 75% full" 13 "Currency box full" 14 "Card/pass box 75% full" 15 "Card/pass box less than 75% full" 16 "Card/pass box full" 17 "Coin de-jam operated" 18 "Farebox set in manual bypass" 19 "Farebox reset to automatic mode" 20 "Pass/transfer jam" 21 "Pass/transfer jam cleared" 22 "Paper currency jam" 23 "Paper currency jam cleared" 24 "Maintenance access in service" 25 "Maintenance access out of service" 26 "Reserved" 97 "Agency defined" ;
VAL_ 2566765566 TransactionType 0 "Cash" 1 "Token" 2 "Ticket" 3 "Pass" 4 "Card" 5 "Permit" 6 "Transfer" 7 "Free" 8 "Reserved for assignment" 12 "Agency defined" ;
VAL_ 2566765566 TypeOfFare 0 "Cash/No detail" 1 "Token A" 2 "Token B" 3 "Ticket A" 4 "Ticket B" 5 "Pass A" 6 "Pass B" 7 "Reserved for assignment" 11 "Agency defined" ;
VAL_ 2566765566 PaymentDetails 0 "Not an upgrade" 1 "Cash" 2 "Token" 3 "Ticket" 4 "Pass" 5 "Card" 6 "Reserved for assignment" 11 "Agency defined" ;
VAL_ 2566765566 TypeOfService 0 "Local service" 1 "Express service" 2 "Agency defined" ;
VAL_ 2566765566 TransferType 0 "North" 1 "South" 2 "East" 3 "West" 4 "In" 5 "Out" 6 "Agency defined" ;
VAL_ 2566765822 FareboxServiceStatus 0 "Farebox out of service" 1 "Farebox in service" 2 "Error Condition" 3 "Not available" ;
VAL_ 2566765822 TripStatus 0 "Undefined" 1 "Trip start" 2 "Trip end" 3 "Undefined" 4 "Undefined" 5 "Layover start" 6 "Layover end" 7 "Undefined" ;
VAL_ 2566765822 TripDirection 0 "North" 1 "South" 2 "East" 3 "West" 4 "In" 5 "Out" 6 "Agency defined" ;
VAL_ 2566765822 FarePresets 0 "Agency defined" 16 "Reserved for assignment" ;
VAL_ 2566766078 RangeCodeEnable 0 "Range code not used for interleaved data" 1 "Range code used for interleaved data" 2 "Error condition" 3 "Not available" ;
VAL_ 2566766078 TransitRouteIDUsage 0 "Transit route ID not used" 1 "Transit route ID used" 2 "Error condition" 3 "Not available" ;
VAL_ 2566766078 IntersectionPreemptionRqResponse 0 "Message is a request directed to the emitter" 1 "Message is a response from the emitter" 2 "Error condition" 3 "Not available" ;
VAL_ 2566766078 PriorityOfResponseSentByEmitter 0 "Reserved" 1 "Low priority" 2 "Probe priority" 3 "High priority" 4 "Reserved" 9 "Priority set by hardware to low priority" 10 "Priority set by hardware to probe priority" 11 "Priority set by hardware to high priority" 12 "Reserved" 14 "Error condition" 15 "Not available" ;
VAL_ 2566766078 TransitDoorEnable 0 "Ignore transit door status" 1 "Transit door status override" 2 "Error condition" 3 "Not available" ;
VAL_ 2566766078 StrobeActivationControlStatus 0 "Deactivate strobe" 1 "Activate strobe" 2 "Error condition" 3 "Not available" ;
VAL_ 2566766846 TypeOfPassengerCount 0 "absolute passenger count" 1 "boarding passenger" 2 "exiting passenger" 3 "boarding passenger (second passenger stream)" 4 "exiting passenger (second passenger stream)" 5 "reserved for future assignment" 251 "reserved" 254 "error indicator" 255 "not available" ;
VAL_ 2566766846 SilentAlarmStatus 0 "Off" 1 "On" 2 "Error condition" 3 "Not available" ;
VAL_ 2566766846 VehicleUseStatus 0 "Normal use" 1 "Unauthorized use" 2 "Error condition" 3 "Not available" ;
VAL_ 2566766846 TransitRunStatus 0 "Off" 1 "On" 2 "Error condition" 3 "Not available" ;
VAL_ 2566767358 FuelType 0 "NONE" 1 "GAS" 2 "METH" 3 "ETH" 4 "DSL" 5 "LPG" 6 "CNG" 7 "PROP" 8 "ELEC" 9 "BI_GAS" 10 "BI_METH" 11 "BI_ETH" 12 "BI_LPG" 13 "BI_CNG" 14 "BI_PROP" 15 "BI_ELEC" 16 "BI_MIX" 17 "HYB_GAS" 18 "HYB_ETH" 19 "HYB_DSL" 20 "HYB_ELEC" 21 "HYB_MIX" 22 "HYB_REG" 23 "NG" 24 "BI_NG" 25 "BI_DSL" 26 "NG_COMP" 27 "DUA_DSL_CNG" 28 "DUA_DSL_LNG" 29 "FUEL_CELL" 30 "HYDRO_COM_ENG" 31 "Kerosene" 32 "ISO/SAE reserved" 254 "Error" 255 "Not available" ;
VAL_ 2566767358 EngineFuelIsolationControl 0 "Gaseous Fuel Migration is Prevented" 1 "Gaseous Fuel is Used" 2 "Reserved" 3 "Don't care / take no action" ;
VAL_ 2566767870 BrakeTemperatureWarning 0 "Not Active" 1 "Active" 2 "Reserved" 3 "not available" ;
VAL_ 2566767870 HaltBrakeMode 0 "Inactive" 1 "Active" 2 "Active, but not functioning properly" 3 "Not defined" 6 "Halt brake not functional" 7 "Not available" ;
VAL_ 2566767870 HillHolderMode 0 "Inactive" 1 "Active" 2 "Active change to inactive" 3 "Active activate brake" 4 "Reserved" 5 "Reserved" 6 "Hill holder not functional" 7 "Not available" ;
VAL_ 2566767870 FoundationBrakeUse 0 "Foundation brakes not in use" 1 "Foundation brakes in use" 2 "Reserved" 3 "Not available" ;
VAL_ 2566767870 XBRSystemState 0 "Any external brake" 1 "Only external brake XBR Priority 00b" 2 "No external brake" 3 "not available" ;
VAL_ 2566767870 XBRActiveControlMode 0 "No brake" 1 "Driver's brake" 2 "Addition mode of XBR" 3 "Maximum mode of XBR" 4 "Reserved for SAE assignment" 15 "Not available" ;
VAL_ 2566767870 ParkingBrakeActuatorFullyActvtd 0 "Parking Brake Actuator not fully activated" 1 "Parking Brake Actuator fully activated" 2 "Error" 3 "Not available" ;
VAL_ 2566767870 EmergencyBrakingActive 0 "inactive" 1 "active" 2 "reserved" 3 "not available" ;
VAL_ 2566767870 RailroadMode 0 "Inactive (Driving mode: Steer Axle on ground)" 1 "Active (Railroad mode: Steer Axle lifted off ground)" 2 "Error" 3 "Not available" ;
VAL_ 2566768382 EngineStartEnableDevice1 0 "start enable OFF" 1 "start enable ON" 2 "reserved" 3 "not available" ;
VAL_ 2566768382 EngineStartEnableDevice2 0 "start enable OFF" 1 "start enable ON" 2 "reserved" 3 "not available" ;
VAL_ 2566768382 EngineStartEnableDevice1Conf 0 "no start enable device 1 installed" 1 "glow plugs installed" 2 "fuelled start installed" 3 "ether injection installed" 4 "electric intake air heater installed" 5 "reserved" 15 "not available" ;
VAL_ 2566768382 EngineStartEnableDevice2Conf 0 "no start enable device 2 installed" 1 "glow plugs installed" 2 "fuelled start installed" 3 "ether injection installed" 4 "electric intake air heater installed" 5 "reserved" 15 "not available" ;
VAL_ 2566768382 EngineColdStartFuelIgniterRelay 0 "Off" 1 "On" 2 "Reserved" 3 "Don't care/take no action" ;
VAL_ 2566768382 EngColdStartFuelIgntrRelayFdbck 0 "Off" 1 "On" 2 "Error" 3 "Not available" ;
VAL_ 2566768638 EngineAuxiliaryGovernorState 0 "Control State is Auxiliary Governor disabled" 1 "Control State is Auxiliary Governor enabled" 2 "SAE reserved" 3 "Not available" ;
VAL_ 2566768638 EngineMultiUnitSyncState 0 "Control State is Functionality disabled (off)" 1 "Control State is Functionality enabled (on)" 2 "SAE reserved" 3 "Not available" ;
VAL_ 2566768638 EngineAltLowIdleSelectState 0 "Normal idle state" 1 "Alternate idle state" 2 "SAE reserved" 3 "not available" ;
VAL_ 2566768638 EngineAlternateRatingSelectState 0 "Control state is Maximum Power Fueling" 1 "Control state is Alternate Power Fueling 1" 2 "Control state is Alternate Power Fueling 2" 3 "Control state is Alternate Power Fueling 3" 4 "Control state is Alternate Power Fueling 4 thru 253" 254 "SAE reserved" 255 "Not available" ;
VAL_ 2566768638 EngineDroopAccl1SelectState 0 "Control state is Normal Droop Setting" 1 "Control state is one of Droop Setting 1 through 13" 14 "SAE reserved" 15 "Not available" ;
VAL_ 2566768638 EngineAltDroopAccl2SelectState 0 "Control's state is Normal Droop Setting" 1 "Control's state is One of Alternate Droop Setting" 14 "SAE reserved" 15 "Not available" ;
VAL_ 2566768638 EngineDroopRemoteAcclSelectState 0 "Control state is Normal Droop Setting" 1 "Control state is one of Droop Setting 1 through 13" 14 "SAE reserved" 15 "Not available" ;
VAL_ 2566768638 EngineDroopAuxInputSelectState 0 "Control state is Normal Droop Setting" 1 "Control state is one of Droop Setting 1 through 13" 14 "SAE reserved" 15 "Not available" ;
VAL_ 2566768638 EngineTorqueCurveSelection 0 "Torque is not selected" 1 "Torque Curve 1 is selected" 2 "Torque Curve 2 is selected" 3 "Torque Curve 3...13  is selected" 14 "Error" 15 "Not supported" ;
VAL_ 2566768638 EngineOperatingModeSelection 0 "Engine not operating in a specific Engine Operating Mode" 1 "Engine Operating Mode 1 is selected" 2 "Engine Operating Mode 2 is selected" 3 "Engine Operating Mode 3 is selected" 4 "Engine Operating Mode 4 is selected" 5 "Engine Operating Mode 5 is selected" 6 "Engine Operating Mode 6 is selected" 7 "Engine Operating Mode 7 is selected" 8 "Engine Operating Mode 8 is selected" 9 "Engine Operating Mode 9 is selected" 10 "Engine Operating Mode 10 is selected" 11 "Engine Operating Mode 11 is selected" 12 "Engine Operating Mode 12 is selected" 13 "Engine Operating Mode 13 is selected" 14 "Error" 15 "Not available" ;
VAL_ 2566768894 EngOprtrPrmryIntrmedSpdSlctState 0 "Control state for ISC is not requested" 1 "Control state is ISC Setting 1" 2 "Control state is ISC Setting 2" 3 "Control state is ISC Setting 3" 4 "Control state is ISC Setting 4" 5 "Control state is ISC Setting 5" 6 "Control state is ISC Setting 6" 7 "Control state is ISC Setting 7" 8 "Control state is ISC Setting 8" 9 "Control state is ISC Setting 9" 10 "Control state is ISC Setting 10" 11 "Control state is ISC Setting 11" 12 "Control state is ISC Setting 12" 13 "Control state is ISC Setting 13" 14 "SAE reserved" 15 "not available" ;
VAL_ 2566769406 EngOprtrPrmryIntrmedSpeedSelect 0 "ISC functionality is not requested" 1 "ISC Setting 1 is selected" 2 "ISC Setting 2 is selected" 3 "ISC Setting 3 is selected" 4 "ISC Setting 4 is selected" 5 "ISC Setting 5 is selected" 6 "ISC Setting 6 is selected" 7 "ISC Setting 7 is selected" 8 "ISC Setting 8 is selected" 9 "ISC Setting 9 is selected" 10 "ISC Setting 10 is selected" 11 "ISC Setting 11 is selected" 12 "ISC Setting 12 is selected" 13 "ISC Setting 13 is selected" 14 "error condition" 15 "not available" ;
VAL_ 2566769662 EngineAuxiliaryGovernorSwitch 0 "Auxiliary Governor is disabled" 1 "Auxiliary Governor is enabled" 2 "Error condition" 3 "Not available" ;
VAL_ 2566769662 EngineSynchronizationSwitch 0 "Functionality is disabled (off)" 1 "Functionality is enabled (on)" 2 "Error" 3 "Not available or Unused" ;
VAL_ 2566769662 EngineAlternateLowIdleSwitch 0 "Default low idle point is selected" 1 "Alternate low idle point is selected" 2 "Error" 3 "Not available or Unused" ;
VAL_ 2566769662 EngineAlternateRatingSelect 0 "Maximum Power Fueling" 1 "Alternate Power Fueling 1" 2 "Alternate Power Fueling 2" 3 "Alternate Power Fueling 3" 4 "Alternate Power Fueling 4..253" 254 "Error condition." 255 "Not available" ;
VAL_ 2566769662 EngineDroopAccelerator1Select 0 "Normal Droop Setting is selected" 1 "One of Droop Setting 1 through 13 is selected" 14 "Error condition" 15 "Not available" ;
VAL_ 2566769662 EngineDroopAccelerator2Select 0 "Normal Droop Setting is selected" 1 "One of Droop Setting 1 through 13 is selected" 14 "Error condition" 15 "Not available" ;
VAL_ 2566769662 EngineDroopRemoteAcclSelect 0 "Normal Droop Setting is selected" 1 "One of Droop Setting 1 through 13 is selected" 14 "Error condition" 15 "Not available" ;
VAL_ 2566769662 EngineDroopAuxiliaryInputSelect 0 "Normal Droop Setting is selected" 1 "One of Droop Setting 1 through 13 is selected" 14 "Error condition" 15 "Not available" ;
VAL_ 2566769662 EngineTorqueCurveSelectionCmd 0 "Torque is not selected" 1 "Torque Curve 1 is selected" 2 "Torque Curve 2 is selected" 3 "Torque Curve 3..13 is selected" 14 "SAE reserved" 15 "Not supported" ;
VAL_ 2566769662 EngineOperatingModeCommand 0 "Not presently requesting a specific Engine Operating Mode be used" 1 "Engine Operating Mode 1 is requested" 2 "Engine Operating Mode 2 is requested" 3 "Engine Operating Mode 3 is requested" 4 "Engine Operating Mode 4 is requested" 5 "Engine Operating Mode 5 is requested" 6 "Engine Operating Mode 6 is requested" 7 "Engine Operating Mode 7 is requested" 8 "Engine Operating Mode 8 is requested" 9 "Engine Operating Mode 9 is requested" 10 "Engine Operating Mode 10 is requested" 11 "Engine Operating Mode 11 is requested" 12 "Engine Operating Mode 12 is requested" 13 "Engine Operating Mode 13 is requested" 14 "SAE Reserved" 15 "Not available / Take no action" ;
VAL_ 2365443326 WorkLightSwitch 0 "Off" 1 "Work Light Combination #1 On" 2 "Work Light Combination #2 On" 3 "Work Light Combination #3 On" 4 "Work Light Combination #4 On" 5 "Reserved" 14 "Error" 15 "Not available (do not change)" ;
VAL_ 2365443326 MainLightSwitch 0 "Off" 1 "Park On" 2 "Headlight On" 3 "Headlight and Park On" 4 "Automatic Lights" 5 "Reserved" 8 "Delayed Off" 9 "Reserved" 14 "Error" 15 "Not available (do not change)" ;
VAL_ 2365443326 TurnSignalSwitch 0 "No Turn being signaled" 1 "Left Turn to be Flashing" 2 "Right turn to be Flashing" 3 "Reserved" 14 "Error" 15 "Not available" ;
VAL_ 2365443326 HazardLightSwitch 0 "Hazard Lamps to be Off" 1 "Hazard Lamps to be Flashing" 2 "Error" 3 "Not available (do not change)" ;
VAL_ 2365443326 HighLowBeamSwitch 0 "Low Beam Selected" 1 "High Beam Selected" 2 "Error" 3 "Not available (do not change)" ;
VAL_ 2365443326 ExteriorLampCheckSwitch 0 "Exterior lamp check inactive" 1 "Exterior lamp check active" 2 "Error" 3 "Not available" ;
VAL_ 2365443326 HeadlampEmergencyFlashSwitch 0 "Headlamp emergency flash inactive" 1 "Headlamp emergency flash active" 2 "Error" 3 "Not available" ;
VAL_ 2566770174 FrontNonOperatorWiperSwitch 0 "Off" 1 "Low" 2 "Medium" 3 "High" 4 "Delayed 1" 5 "Delayed 2" 6 "Mist" 7 "Reserved" 15 "Not available" ;
VAL_ 2566770174 FrontOperatorWiperSwitch 0 "Off" 1 "Low" 2 "Medium" 3 "High" 4 "Delayed 1" 5 "Delayed 2" 6 "Mist" 7 "Reserved" 15 "Not available" ;
VAL_ 2566770174 RearWiperSwitch 0 "Off" 1 "Low" 2 "Medium" 3 "High" 4 "Delayed 1" 5 "Delayed 2" 6 "Mist" 7 "Reserved" 15 "Not available" ;
VAL_ 2566770174 FrontNonOperatorWasherSwitch 0 "Off" 1 "Low" 2 "Medium" 3 "High" 4 "Reserved" 7 "Not available (do not change)" ;
VAL_ 2566770174 FrontOperatorWasherSwitch 0 "Off" 1 "Low" 2 "Medium" 3 "High" 4 "Reserved" 7 "Not available (do not change)" ;
VAL_ 2566770174 RearWasherFunction 0 "Off" 1 "Low" 2 "Medium" 3 "High" 4 "Reserved" 7 "Not available (do not change)" ;
VAL_ 2633880062 FMSStandardDiagnosticsSupported 0 "Diagnostics Is Not Supported" 1 "Diagnostics Is Supported" 2 "Reserved" 3 "Don't care" ;
VAL_ 2633880062 FMSStandardRequestsSupported 0 "On request mode is not supported" 1 "On request mode is supported" 2 "Reserved" 3 "Don't care" ;
VAL_ 2566771966 TransferCaseSelectorSwitch 0 "2 wheel high (Normal or 'On Highway' Range)" 1 "4 wheel high (Normal or 'On Highway' Range)" 2 "Neutral" 3 "2 wheel low (or 'Off Highway' Range)" 4 "4 wheel low (or 'Off Highway' Range)" 5 "Reserved for SAE assignment" 6 "Error indicator" 7 "Not available" ;
VAL_ 2566771966 AfttreatmentSCRDosingModeCommand 0 "Standard SCR Dosing Mode" 1 "Reduced SCR Dosing Mode" 2 "Reserved" 3 "Reserved" 4 "Reserved" 5 "Reserved" 6 "Reserved for status error value" 7 "Don't care/Take no Action" ;
VAL_ 2566771966 MomentaryOperatorKeySwitch 0 "Button is not depressed by the operator" 1 "Button is depressed by the operator" 2 "Error" 3 "Not Available" ;
VAL_ 2566771966 FifthWheelReleaseControl 0 "Coupler Locked" 1 "Coupler Unlocked" 2 "Error" 3 "Not Available" ;
VAL_ 2566771966 FifthWhlReleaseCtrlSecurityLckt 0 "Fifth wheel release Disabled" 1 "Fifth wheel release Enabled" 2 "Error" 3 "Not Available" ;
VAL_ 2566771966 VehicleTrailerStatus 0 "Trailer is not detected" 1 "Trailer is detected" 2 "Error" 3 "Not available" ;
VAL_ 2566771966 OperatorKeyDetected 0 "No key detected" 1 "Key is detected" 2 "Error" 3 "Not Available" ;
VAL_ 2566771966 TransmissionOilLevelRequest 0 "No transmission oil level reading desired" 1 "Transmission oil level reading desired" 2 "Reserved" 3 "Don't care / take no action" ;
VAL_ 2566771966 OperatorKeySwitchAccessoryPower 0 "Accessory power state is not active" 1 "Accessory power state active" 2 "Error" 3 "Not Available" ;
VAL_ 2566771966 OperatorKeySwitchIgnitionPower 0 "Ignition state is not active" 1 "Ignition state is active" 2 "Error" 3 "Not Available" ;
VAL_ 2566771966 OperatorKeySwitchStart 0 "Start state is not active" 1 "Start state is active" 2 "Error" 3 "Not Available" ;
VAL_ 2566771966 OprtrKeySwitchDelayedBattryOff 0 "Delayed battery off state not active" 1 "Battery power will be removed after delay" 2 "Error" 3 "Not Available" ;
VAL_ 2566772222 EngVarGmtryTurboAirCtrlShtoffVlv 0 "VGT Air Control Shutoff Valve is Off" 1 "VGT Air Control Shutoff Valve is On" 2 "Reserved" 3 "Not available" ;
VAL_ 2566772222 EngineFuelControlMode 0 "Open loop" 1 "Closed loop" 2 "SAE reserved" 3 "Not available" ;
VAL_ 2566772222 EngVariableGmtryTurbo1CtrlMde 0 "Open loop" 1 "Closed loop" 2 "SAE reserved" 3 "Not available" ;
VAL_ 2365445886 Jystck1XAxsNeutralPositionStatus 0 "Not in Neutral Position" 1 "In Neutral Position" 2 "Error Indicator" 3 "Not Available" ;
VAL_ 2365445886 Jystck1XAxsLvrLftNegPosStatus 0 "Not on negative side of Neutral" 1 "On negative side of Neutral" 2 "Error Indicator" 3 "Not Available" ;
VAL_ 2365445886 Jystck1XAxsLvrRightPstvPosStatus 0 "Not on Positive side of Neutral" 1 "On positive side of Neutral" 2 "Error Indicator" 3 "Not Available" ;
VAL_ 2365445886 Jystck1YAxsNeutralPositionStatus 0 "Not in Neutral Position" 1 "In Neutral Position" 2 "Error Indicator" 3 "Not Available" ;
VAL_ 2365445886 Jystck1YAxsLvrBackNegPosStatus 0 "Not on negative side of Neutral" 1 "On negative side of Neutral" 2 "Error Indicator" 3 "Not Available" ;
VAL_ 2365445886 Jystck1YAxsLvrFrwdPstvPosStatus 0 "Not on Positive side of Neutral" 1 "On positive side of Neutral" 2 "Error Indicator" 3 "Not Available" ;
VAL_ 2365445886 Jystck1YAxsDetentPositionStatus 0 "Not in the Detent Position" 1 "In the Detent Position" 2 "Error Indicator" 3 "Not Available" ;
VAL_ 2365445886 Jystck1XAxsDetentPositionStatus 0 "Not in the Detent Position" 1 "In the Detent Position" 2 "Error Indicator" 3 "Not Available" ;
VAL_ 2365445886 Joystick1Button4PressedStatus 0 "Button not pressed" 1 "Button pressed" 2 "Error Indicator" 3 "Not Available" ;
VAL_ 2365445886 Joystick1Button3PressedStatus 0 "Button not pressed" 1 "Button pressed" 2 "Error Indicator" 3 "Not Available" ;
VAL_ 2365445886 Joystick1Button2PressedStatus 0 "Button not pressed" 1 "Button pressed" 2 "Error Indicator" 3 "Not Available" ;
VAL_ 2365445886 Joystick1Button1PressedStatus 0 "Button not pressed" 1 "Button pressed" 2 "Error Indicator" 3 "Not Available" ;
VAL_ 2365445886 Joystick1Button8PressedStatus 0 "Button not pressed" 1 "Button pressed" 2 "Error Indicator" 3 "Not Available" ;
VAL_ 2365445886 Joystick1Button7PressedStatus 0 "Button not pressed" 1 "Button pressed" 2 "Error Indicator" 3 "Not Available" ;
VAL_ 2365445886 Joystick1Button6PressedStatus 0 "Button not pressed" 1 "Button pressed" 2 "Error Indicator" 3 "Not Available" ;
VAL_ 2365445886 Joystick1Button5PressedStatus 0 "Button not pressed" 1 "Button pressed" 2 "Error Indicator" 3 "Not Available" ;
VAL_ 2365445886 Joystick1Button12PressedStatus 0 "Button not pressed" 1 "Button pressed" 2 "Error Indicator" 3 "Not Available" ;
VAL_ 2365445886 Joystick1Button11PressedStatus 0 "Button not pressed" 1 "Button pressed" 2 "Error Indicator" 3 "Not Available" ;
VAL_ 2365445886 Joystick1Button10PressedStatus 0 "Button not pressed" 1 "Button pressed" 2 "Error Indicator" 3 "Not Available" ;
VAL_ 2365445886 Joystick1Button9PressedStatus 0 "Button not pressed" 1 "Button pressed" 2 "Error Indicator" 3 "Not Available" ;
VAL_ 2365446142 Jystck1GrpXAxsNtrlPositionStatus 0 "Not in Neutral Position" 1 "In Neutral Position" 2 "Error Indicator" 3 "Not Available" ;
VAL_ 2365446142 Jystck1GrpXAxsLvrLftNegPosStatus 0 "Not on negative side of Neutral" 1 "On negative side of Neutral" 2 "Error Indicator" 3 "Not Available" ;
VAL_ 2365446142 Jystck1GrpXAxsLvrRghtPstvPosStat 0 "Not on Positive side of Neutral" 1 "On positive side of Neutral" 2 "Error Indicator" 3 "Not Available" ;
VAL_ 2365446142 Jystck1GrpYAxsNtrlPositionStatus 0 "Not in Neutral Position" 1 "In Neutral Position" 2 "Error Indicator" 3 "Not Available" ;
VAL_ 2365446142 Jystck1GrpYAxsLvrBackNegPosStat 0 "Not on negative side of Neutral" 1 "On negative side of Neutral" 2 "Error Indicator" 3 "Not Available" ;
VAL_ 2365446142 Jystck1GrpYAxsLvrFrwdPstvPosStat 0 "Not on Positive side of Neutral" 1 "On positive side of Neutral" 2 "Error Indicator" 3 "Not Available" ;
VAL_ 2365446142 Jystck1ThetaAxsNtrlPosStatus 0 "Not in Neutral Position" 1 "In Neutral Position" 2 "Error Indicator" 3 "Not Available" ;
VAL_ 2365446142 Jystck1ThtAxsCntrClckwsNegPsStat 0 "Not on negative side of Neutral" 1 "On negative side of Neutral" 2 "Error Indicator" 3 "Not Available" ;
VAL_ 2365446142 Jystck1ThetaAxsClckwsPstvPosStat 0 "Not on Positive side of Neutral" 1 "On positive side of Neutral" 2 "Error Indicator" 3 "Not Available" ;
VAL_ 2365446142 Jystck1ThetaAxsDetentPosStatus 0 "Not in the Detent Position" 1 "In the Detent Position" 2 "Error Indicator" 3 "Not Available" ;
VAL_ 2365446142 Jystck1GrpYAxsDetentPosStatus 0 "Not in the Detent Position" 1 "In the Detent Position" 2 "Error Indicator" 3 "Not Available" ;
VAL_ 2365446142 Jystck1GrpXAxsDetentPosStatus 0 "Not in the Detent Position" 1 "In the Detent Position" 2 "Error Indicator" 3 "Not Available" ;
VAL_ 2365446142 Joystick1Button16PressedStatus 0 "Button not pressed" 1 "Button pressed" 2 "Error Indicator" 3 "Not Available" ;
VAL_ 2365446142 Joystick1Button15PressedStatus 0 "Button not pressed" 1 "Button pressed" 2 "Error Indicator" 3 "Not Available" ;
VAL_ 2365446142 Joystick1Button14PressedStatus 0 "Button not pressed" 1 "Button pressed" 2 "Error Indicator" 3 "Not Available" ;
VAL_ 2365446142 Joystick1Button13PressedStatus 0 "Button not pressed" 1 "Button pressed" 2 "Error Indicator" 3 "Not Available" ;
VAL_ 2365446398 Jystck2XAxsNeutralPositionStatus 0 "Not in Neutral Position" 1 "In Neutral Position" 2 "Error Indicator" 3 "Not Available" ;
VAL_ 2365446398 Jystck2XAxsLvrLftNegPosStatus 0 "Not on negative side of Neutral" 1 "On negative side of Neutral" 2 "Error Indicator" 3 "Not Available" ;
VAL_ 2365446398 Jystck2XAxsLvrRightPstvPosStatus 0 "Not on Positive side of Neutral" 1 "On positive side of Neutral" 2 "Error Indicator" 3 "Not Available" ;
VAL_ 2365446398 Jystck2YAxsNeutralPositionStatus 0 "Not in Neutral Position" 1 "In Neutral Position" 2 "Error Indicator" 3 "Not Available" ;
VAL_ 2365446398 Jystck2YAxsLvrBackNegPosStatus 0 "Not on negative side of Neutral" 1 "On negative side of Neutral" 2 "Error Indicator" 3 "Not Available" ;
VAL_ 2365446398 Jystck2YAxsLvrFrwdPstvPosStatus 0 "Not on Positive side of Neutral" 1 "On positive side of Neutral" 2 "Error Indicator" 3 "Not Available" ;
VAL_ 2365446398 Jystck2YAxsDetentPositionStatus 0 "Not in the Detent Position" 1 "In the Detent Position" 2 "Error Indicator" 3 "Not Available" ;
VAL_ 2365446398 Jystck2XAxsDetentPositionStatus 0 "Not in the Detent Position" 1 "In the Detent Position" 2 "Error Indicator" 3 "Not Available" ;
VAL_ 2365446398 Joystick2Button4PressedStatus 0 "Button not pressed" 1 "Button pressed" 2 "Error Indicator" 3 "Not Available" ;
VAL_ 2365446398 Joystick2Button3PressedStatus 0 "Button not pressed" 1 "Button pressed" 2 "Error Indicator" 3 "Not Available" ;
VAL_ 2365446398 Joystick2Button2PressedStatus 0 "Button not pressed" 1 "Button pressed" 2 "Error Indicator" 3 "Not Available" ;
VAL_ 2365446398 Joystick2Button1PressedStatus 0 "Button not pressed" 1 "Button pressed" 2 "Error Indicator" 3 "Not Available" ;
VAL_ 2365446398 Joystick2Button8PressedStatus 0 "Button not pressed" 1 "Button pressed" 2 "Error Indicator" 3 "Not Available" ;
VAL_ 2365446398 Joystick2Button7PressedStatus 0 "Button not pressed" 1 "Button pressed" 2 "Error Indicator" 3 "Not Available" ;
VAL_ 2365446398 Joystick2Button6PressedStatus 0 "Button not pressed" 1 "Button pressed" 2 "Error Indicator" 3 "Not Available" ;
VAL_ 2365446398 Joystick2Button5PressedStatus 0 "Button not pressed" 1 "Button pressed" 2 "Error Indicator" 3 "Not Available" ;
VAL_ 2365446398 Joystick2Button12PressedStatus 0 "Button not pressed" 1 "Button pressed" 2 "Error Indicator" 3 "Not Available" ;
VAL_ 2365446398 Joystick2Button11PressedStatus 0 "Button not pressed" 1 "Button pressed" 2 "Error Indicator" 3 "Not Available" ;
VAL_ 2365446398 Joystick2Button10PressedStatus 0 "Button not pressed" 1 "Button pressed" 2 "Error Indicator" 3 "Not Available" ;
VAL_ 2365446398 Joystick2Button9PressedStatus 0 "Button not pressed" 1 "Button pressed" 2 "Error Indicator" 3 "Not Available" ;
VAL_ 2365446654 Jystck2GrpXAxsNtrlPositionStatus 0 "Not on negative side of Neutral" 1 "On negative side of Neutral" 2 "Error Indicator" 3 "Not Available" ;
VAL_ 2365446654 Jystck2GrpXAxsLvrLftNegPosStatus 0 "Not on negative side of Neutral" 1 "On negative side of Neutral" 2 "Error Indicator" 3 "Not Available" ;
VAL_ 2365446654 Jystck2GrpXAxsLvrRghtPstvPosStat 0 "Not on Positive side of Neutral" 1 "On positive side of Neutral" 2 "Error Indicator" 3 "Not Available" ;
VAL_ 2365446654 Jystck2GrpYAxsNtrlPositionStatus 0 "Not in Neutral Position" 1 "In Neutral Position" 2 "Error Indicator" 3 "Not Available" ;
VAL_ 2365446654 Jystck2GrpYAxsLvrBackNegPosStat 0 "Not on negative side of Neutral" 1 "On negative side of Neutral" 2 "Error Indicator" 3 "Not Available" ;
VAL_ 2365446654 Jystck2GrpYAxsLvrFrwdPstvPosStat 0 "Not on Positive side of Neutral" 1 "On positive side of Neutral" 2 "Error Indicator" 3 "Not Available" ;
VAL_ 2365446654 Jystck2ThetaAxsNtrlPosStatus 0 "Not in Neutral Position" 1 "In Neutral Position" 2 "Error Indicator" 3 "Not Available" ;
VAL_ 2365446654 Jystck2ThtAxsCntrClckwsNegPsStat 0 "Not on negative side of Neutral" 1 "On negative side of Neutral" 2 "Error Indicator" 3 "Not Available" ;
VAL_ 2365446654 Jystck2ThetaAxsClckwsPstvPosStat 0 "Not on Positive side of Neutral" 1 "On positive side of Neutral" 2 "Error Indicator" 3 "Not Available" ;
VAL_ 2365446654 Jystck2ThetaAxsDetentPosStatus 0 "Not in the Detent Position" 1 "In the Detent Position" 2 "Error Indicator" 3 "Not Available" ;
VAL_ 2365446654 Jystck2GrpYAxsDetentPosStatus 0 "Not in the Detent Position" 1 "In the Detent Position" 2 "Error Indicator" 3 "Not Available" ;
VAL_ 2365446654 Jystck2GrpXAxsDetentPosStatus 0 "Not in the Detent Position" 1 "In the Detent Position" 2 "Error Indicator" 3 "Not Available" ;
VAL_ 2365446654 Joystick2Button16PressedStatus 0 "Button not pressed" 1 "Button pressed" 2 "Error Indicator" 3 "Not Available" ;
VAL_ 2365446654 Joystick2Button15PressedStatus 0 "Button not pressed" 1 "Button pressed" 2 "Error Indicator" 3 "Not Available" ;
VAL_ 2365446654 Joystick2Button14PressedStatus 0 "Button not pressed" 1 "Button pressed" 2 "Error Indicator" 3 "Not Available" ;
VAL_ 2365446654 Joystick2Button13PressedStatus 0 "Button not pressed" 1 "Button pressed" 2 "Error Indicator" 3 "Not Available" ;
VAL_ 2365446910 Jystck3XAxsNeutralPositionStatus 0 "Not in Neutral Position" 1 "In Neutral Position" 2 "Error Indicator" 3 "Not Available" ;
VAL_ 2365446910 Jystck3XAxsLvrLftNegPosStatus 0 "Not on negative side of Neutral" 1 "On negative side of Neutral" 2 "Error Indicator" 3 "Not Available" ;
VAL_ 2365446910 Jystck3XAxsLvrRightPstvPosStatus 0 "Not on Positive side of Neutral" 1 "On positive side of Neutral" 2 "Error Indicator" 3 "Not Available" ;
VAL_ 2365446910 Jystck3YAxsNeutralPositionStatus 0 "Not in Neutral Position" 1 "In Neutral Position" 2 "Error Indicator" 3 "Not Available" ;
VAL_ 2365446910 Jystck3YAxsLvrBackNegPosStatus 0 "Not on negative side of Neutral" 1 "On negative side of Neutral" 2 "Error Indicator" 3 "Not Available" ;
VAL_ 2365446910 Jystck3YAxsLvrFrwdPstvPosStatus 0 "Not on Positive side of Neutral" 1 "On positive side of Neutral" 2 "Error Indicator" 3 "Not Available" ;
VAL_ 2365446910 Jystck3YAxsDetentPositionStatus 0 "Not in the Detent Position" 1 "In the Detent Position" 2 "Error Indicator" 3 "Not Available" ;
VAL_ 2365446910 Jystck3XAxsDetentPositionStatus 0 "Not in the Detent Position" 1 "In the Detent Position" 2 "Error Indicator" 3 "Not Available" ;
VAL_ 2365446910 Joystick3Button4PressedStatus 0 "Button not pressed" 1 "Button pressed" 2 "Error Indicator" 3 "Not Available" ;
VAL_ 2365446910 Joystick3Button3PressedStatus 0 "Button not pressed" 1 "Button pressed" 2 "Error Indicator" 3 "Not Available" ;
VAL_ 2365446910 Joystick3Button2PressedStatus 0 "Button not pressed" 1 "Button pressed" 2 "Error Indicator" 3 "Not Available" ;
VAL_ 2365446910 Joystick3Button1PressedStatus 0 "Button not pressed" 1 "Button pressed" 2 "Error Indicator" 3 "Not Available" ;
VAL_ 2365446910 Joystick3Button8PressedStatus 0 "Button not pressed" 1 "Button pressed" 2 "Error Indicator" 3 "Not Available" ;
VAL_ 2365446910 Joystick3Button7PressedStatus 0 "Button not pressed" 1 "Button pressed" 2 "Error Indicator" 3 "Not Available" ;
VAL_ 2365446910 Joystick3Button6PressedStatus 0 "Button not pressed" 1 "Button pressed" 2 "Error Indicator" 3 "Not Available" ;
VAL_ 2365446910 Joystick3Button5PressedStatus 0 "Button not pressed" 1 "Button pressed" 2 "Error Indicator" 3 "Not Available" ;
VAL_ 2365446910 Joystick3Button12PressedStatus 0 "Button not pressed" 1 "Button pressed" 2 "Error Indicator" 3 "Not Available" ;
VAL_ 2365446910 Joystick3Button11PressedStatus 0 "Button not pressed" 1 "Button pressed" 2 "Error Indicator" 3 "Not Available" ;
VAL_ 2365446910 Joystick3Button10PressedStatus 0 "Button not pressed" 1 "Button pressed" 2 "Error Indicator" 3 "Not Available" ;
VAL_ 2365446910 Joystick3Button9PressedStatus 0 "Button not pressed" 1 "Button pressed" 2 "Error Indicator" 3 "Not Available" ;
VAL_ 2365447166 Jystck3GrpXAxsNtrlPositionStatus 0 "Not on negative side of Neutral" 1 "On negative side of Neutral" 2 "Error Indicator" 3 "Not Available" ;
VAL_ 2365447166 Jystck3GrpXAxsLvrLftNegPosStatus 0 "Not on negative side of Neutral" 1 "On negative side of Neutral" 2 "Error Indicator" 3 "Not Available" ;
VAL_ 2365447166 Jystck3GrpXAxsLvrRghtPstvPosStat 0 "Not on Positive side of Neutral" 1 "On positive side of Neutral" 2 "Error Indicator" 3 "Not Available" ;
VAL_ 2365447166 Jystck3GrpYAxsNtrlPositionStatus 0 "Not in Neutral Position" 1 "In Neutral Position" 2 "Error Indicator" 3 "Not Available" ;
VAL_ 2365447166 Jystck3GrpYAxsLvrBackNegPosStat 0 "Not on negative side of Neutral" 1 "On negative side of Neutral" 2 "Error Indicator" 3 "Not Available" ;
VAL_ 2365447166 Jystck3GrpYAxsLvrFrwdPstvPosStat 0 "Not on Positive side of Neutral" 1 "On positive side of Neutral" 2 "Error Indicator" 3 "Not Available" ;
VAL_ 2365447166 Jystck3ThetaAxsNtrlPosStatus 0 "Not in Neutral Position" 1 "In Neutral Position" 2 "Error Indicator" 3 "Not Available" ;
VAL_ 2365447166 Jystck3ThtAxsCntrClckwsNegPsStat 0 "Not on negative side of Neutral" 1 "On negative side of Neutral" 2 "Error Indicator" 3 "Not Available" ;
VAL_ 2365447166 Jystck3ThetaAxsClckwsPstvPosStat 0 "Not on Positive side of Neutral" 1 "On positive side of Neutral" 2 "Error Indicator" 3 "Not Available" ;
VAL_ 2365447166 Jystck3ThetaAxsDetentPosStatus 0 "Not in the Detent Position" 1 "In the Detent Position" 2 "Error Indicator" 3 "Not Available" ;
VAL_ 2365447166 Jystck3GrpYAxsDetentPosStatus 0 "Not in the Detent Position" 1 "In the Detent Position" 2 "Error Indicator" 3 "Not Available" ;
VAL_ 2365447166 Jystck3GrpXAxsDetentPosStatus 0 "Not in the Detent Position" 1 "In the Detent Position" 2 "Error Indicator" 3 "Not Available" ;
VAL_ 2365447166 Joystick3Button16PressedStatus 0 "Button not pressed" 1 "Button pressed" 2 "Error Indicator" 3 "Not Available" ;
VAL_ 2365447166 Joystick3Button15PressedStatus 0 "Button not pressed" 1 "Button pressed" 2 "Error Indicator" 3 "Not Available" ;
VAL_ 2365447166 Joystick3Button14PressedStatus 0 "Button not pressed" 1 "Button pressed" 2 "Error Indicator" 3 "Not Available" ;
VAL_ 2365447166 Joystick3Button13PressedStatus 0 "Button not pressed" 1 "Button pressed" 2 "Error Indicator" 3 "Not Available" ;
VAL_ 2566774014 EngThrottleSyncMdeStat 0 "Not Synchronized" 1 "Synchronized Center" 2 "Synchronized Port" 3 "Synchronized Starboard" 4 "Synchronized Master" 5 "Reserved" 15 "Take no action" ;
VAL_ 2566774014 TrollingModeStatus 0 "Trolling mode is off" 1 "Trolling mode is active" 2 "Reserved" 3 "Take no action" ;
VAL_ 2566774014 SlowVesselModeStatus 0 "Slow vessel mode is OFF." 1 "Slow vessel mode is ACTIVE." 2 "Reserved" 3 "Take no action" ;
VAL_ 2566774014 EngineMarineOperatingModeStatus 0 "Maintenance Mode" 1 "Electrical Power Generation (EPG) mode" 2 "Propulsion Constant Speed Mode" 3 "Propulsion Variable Speed Mode" 4 "Propulsion Constant Speed Heavy Sea Mode" 5 "Propulsion Variable Speed Heavy Sea Mode" 6 "Error" 7 "Not available" ;
VAL_ 2633883646 FrontWheelDriveActuatorStatus 0 "Front Wheel Drive Actuator not engaged" 1 "Front Wheel Drive Actuator engaged" 2 "Error" 3 "Not Available" ;
VAL_ 2566775294 AirConditionerCompressorStatus 0 "Air Conditioner Compressor is OFF" 1 "Air Conditioner Compressor is ON" 2 "Error" 3 "Not Available" ;
VAL_ 2365449982 HydrBrkPressWarningStateCircuit1 0 "Pressure level sufficient" 1 "Pressure level below warning level" 2 "Error indicator" 3 "Not available" ;
VAL_ 2365449982 HydrBrkPressWarningStateCircuit2 0 "Pressure level sufficient" 1 "Pressure level below warning level" 2 "Error indicator" 3 "Not available" ;
VAL_ 2365449982 HydrBrkPressSupplyStateCircuit1 0 "Supply is not reliable" 1 "Supply is reliable" 2 "Error indicator" 3 "Not available" ;
VAL_ 2365449982 HydrBrkPressSupplyStateCircuit2 0 "Supply is not reliable" 1 "Supply is reliable" 2 "Error indicator" 3 "Not available" ;
VAL_ 2365449982 HydrBrkSystemAudibleWarningCmd 0 "Audible warning off" 1 "Audible warning on" 2 "Reserved" 3 "Don't care" ;
VAL_ 2365449982 HydraulicBrakeFluidLevelSwitch 0 "Fluid level is not sufficient" 1 "Fluid level is sufficient" 2 "Error indicator" 3 "Not available" ;
VAL_ 2365450238 Bus1UtilityDeadBus 0 "Bus is not dead" 1 "Bus is dead" 2 "Error" 3 "Not Available or Not Installed" ;
VAL_ 2365450238 Bus1UtilityPhaseMatch 0 "Phases do not match" 1 "Phases match" 2 "Error" 3 "Not Available or Not Installed" ;
VAL_ 2365450238 Bus1UtilityFrequencyMatch 0 "Frequencies do not match" 1 "Frequencies match" 2 "Error" 3 "Not Available or Not Installed" ;
VAL_ 2365450238 Bus1UtilityVoltageMatch 0 "Voltages do not match" 1 "Voltages match" 2 "Error" 3 "Not Available or Not Installed" ;
VAL_ 2365450238 Bus1UtilityInSync 0 "Not synchronized" 1 "Synchronized" 2 "Error" 3 "Not Available or Not Installed" ;
VAL_ 2365450494 Bus1GeneratorDeadBus 0 "Bus is not dead" 1 "Bus is dead" 2 "Error" 3 "Not Available or Not Installed" ;
VAL_ 2365450494 Bus1GeneratorPhaseMatch 0 "Phases do not match" 1 "Phases match" 2 "Error" 3 "Not Available or Not Installed" ;
VAL_ 2365450494 Bus1GeneratorFrequencyMatch 0 "Frequencies do not match" 1 "Frequencies match" 2 "Error" 3 "Not Available or Not Installed" ;
VAL_ 2365450494 Bus1GeneratorVoltageMatch 0 "Voltages do not match" 1 "Voltages match" 2 "Error" 3 "Not Available or Not Installed" ;
VAL_ 2365450494 Bus1GeneratorInSync 0 "Not synchronized" 1 "Synchronized" 2 "Error" 3 "Not Available or Not Installed" ;
VAL_ 2365452030 UtilityPhaseCPowerFactorLagging 0 "Leading" 1 "Lagging" 2 "Error" 3 "Not Available or Not Installed" ;
VAL_ 2365452798 UtilityPhaseBPowerFactorLagging 0 "Leading" 1 "Lagging" 2 "Error" 3 "Not Available or Not Installed" ;
VAL_ 2365453566 UtilityPhaseAPowerFactorLagging 0 "Leading" 1 "Lagging" 2 "Error" 3 "Not Available or Not Installed" ;
VAL_ 2365454334 UtilityOverallPowerFactorLagging 0 "Leading" 1 "Lagging" 2 "Error" 3 "Not Available or Not Installed" ;
VAL_ 2365455358 GenPhaseCPowerFactorLagging 0 "Leading" 1 "Lagging" 2 "Error" 3 "Not Available or Not Installed" ;
VAL_ 2365456126 GenPhaseBPowerFactorLagging 0 "Leading" 1 "Lagging" 2 "Error" 3 "Not Available or Not Installed" ;
VAL_ 2365456894 GenPhaseAPowerFactorLagging 0 "Leading" 1 "Lagging" 2 "Error" 3 "Not Available or Not Installed" ;
VAL_ 2365457662 GenOverallPowerFactorLagging 0 "Leading" 1 "Lagging" 2 "Error" 3 "Not Available or Not Installed" ;
VAL_ 2566787070 TimeCommand 0 "24 hour" 1 "12 hour (am/ pm)" 2 "Reserved" 3 "No action" ;
VAL_ 2566787070 DecimalSymbolCommand 0 "Comma is used" 1 "Point is used" 2 "Reserved" 3 "No action" ;
VAL_ 2566787070 DateCommand 0 "ddmmyyyy" 1 "ddyyyymm" 2 "mmyyyydd" 3 "mmddyyyy" 4 "yyyymmdd" 5 "yyyyddmm" 6 "Reserved" ;
VAL_ 2566787070 MassUnitCommand 0 "Metric (tonne, kg, ...)" 1 "Imperial (long tons-UK, pounds, ....)" 2 "Tons/pounds (short tons-US, pounds, ...)" 3 "No action" ;
VAL_ 2566787070 VolumeUnitCommand 0 "Metric (litre)" 1 "Imperial (gallon)" 2 "US (gallon)" 3 "No action" ;
VAL_ 2566787070 AreaUnitCommand 0 "Metric (ha or m2)" 1 "Imperial (acres or feet2)" 2 "Reserved" 3 "No action" ;
VAL_ 2566787070 DistanceUnitCommand 0 "Metric (km, m, ...)" 1 "Imperial (miles, feet, ..)" 2 "Reserved" 3 "No action" ;
VAL_ 2566787326 AuxValve0State 0 "Blocked" 1 "Extend" 2 "Retract" 3 "Floating" 4 "Reserved" 15 "Don't Care" ;
VAL_ 2566787326 AuxValve0FailSafeMode 0 "Block" 1 "Float" 2 "Error indication" 3 "Not available" ;
VAL_ 2566787326 AuxiliaryValve0ExitReasonCode 0 "No reason/all clear" 1 "Operator presence not detected" 2 "Implement released control of function" 3 "Operator override of function" 4 "Operator control not in valid position" 5 "Remote command timeout" 6 "Remote command out of range/invalid" 7 "Function not calibrated" 8 "Operator control fault" 9 "Function fault" 10 "Reserved" 20 "Hydraulic oil level too low" 21 "Valve locked out" 22 "Reserved" 41 "Manufacturer Specific" 62 "Error" 63 "Not available/not installed" ;
VAL_ 2566787582 AuxValve1State 0 "Blocked" 1 "Extend" 2 "Retract" 3 "Floating" 4 "Reserved" 15 "Don't Care" ;
VAL_ 2566787582 AuxValve1FailSafeMode 0 "Block" 1 "Float" 2 "Error indication" 3 "Not available" ;
VAL_ 2566787582 AuxiliaryValve1ExitReasonCode 0 "No reason/all clear" 1 "Operator presence not detected" 2 "Implement released control of function" 3 "Operator override of function" 4 "Operator control not in valid position" 5 "Remote command timeout" 6 "Remote command out of range/invalid" 7 "Function not calibrated" 8 "Operator control fault" 9 "Function fault" 10 "Reserved" 20 "Hydraulic oil level too low" 21 "Valve locked out" 22 "Reserved" 41 "Manufacturer Specific" 62 "Error" 63 "Not available/not installed" ;
VAL_ 2566787838 AuxValve2State 0 "Blocked" 1 "Extend" 2 "Retract" 3 "Floating" 4 "Reserved" 15 "Don't Care" ;
VAL_ 2566787838 AuxValve2FailSafeMode 0 "Block" 1 "Float" 2 "Error indication" 3 "Not available" ;
VAL_ 2566787838 AuxiliaryValve2ExitReasonCode 0 "No reason/all clear" 1 "Operator presence not detected" 2 "Implement released control of function" 3 "Operator override of function" 4 "Operator control not in valid position" 5 "Remote command timeout" 6 "Remote command out of range/invalid" 7 "Function not calibrated" 8 "Operator control fault" 9 "Function fault" 10 "Reserved" 20 "Hydraulic oil level too low" 21 "Valve locked out" 22 "Reserved" 41 "Manufacturer Specific" 62 "Error" 63 "Not available/not installed" ;
VAL_ 2566788094 AuxValve3State 0 "Blocked" 1 "Extend" 2 "Retract" 3 "Floating" 4 "Reserved" 15 "Don't Care" ;
VAL_ 2566788094 AuxValve3FailSafeMode 0 "Block" 1 "Float" 2 "Error indication" 3 "Not available" ;
VAL_ 2566788094 AuxiliaryValve3ExitReasonCode 0 "No reason/all clear" 1 "Operator presence not detected" 2 "Implement released control of function" 3 "Operator override of function" 4 "Operator control not in valid position" 5 "Remote command timeout" 6 "Remote command out of range/invalid" 7 "Function not calibrated" 8 "Operator control fault" 9 "Function fault" 10 "Reserved" 20 "Hydraulic oil level too low" 21 "Valve locked out" 22 "Reserved" 41 "Manufacturer Specific" 62 "Error" 63 "Not available/not installed" ;
VAL_ 2566788350 AuxValve4State 0 "Blocked" 1 "Extend" 2 "Retract" 3 "Floating" 4 "Reserved" 15 "Don't Care" ;
VAL_ 2566788350 AuxValve4FailSafeMode 0 "Block" 1 "Float" 2 "Error indication" 3 "Not available" ;
VAL_ 2566788350 AuxiliaryValve4ExitReasonCode 0 "No reason/all clear" 1 "Operator presence not detected" 2 "Implement released control of function" 3 "Operator override of function" 4 "Operator control not in valid position" 5 "Remote command timeout" 6 "Remote command out of range/invalid" 7 "Function not calibrated" 8 "Operator control fault" 9 "Function fault" 10 "Reserved" 20 "Hydraulic oil level too low" 21 "Valve locked out" 22 "Reserved" 41 "Manufacturer Specific" 62 "Error" 63 "Not available/not installed" ;
VAL_ 2566788606 AuxValve5State 0 "Blocked" 1 "Extend" 2 "Retract" 3 "Floating" 4 "Reserved" 15 "Don't Care" ;
VAL_ 2566788606 AuxValve5FailSafeMode 0 "Block" 1 "Float" 2 "Error indication" 3 "Not available" ;
VAL_ 2566788606 AuxiliaryValve5ExitReasonCode 0 "No reason/all clear" 1 "Operator presence not detected" 2 "Implement released control of function" 3 "Operator override of function" 4 "Operator control not in valid position" 5 "Remote command timeout" 6 "Remote command out of range/invalid" 7 "Function not calibrated" 8 "Operator control fault" 9 "Function fault" 10 "Reserved" 20 "Hydraulic oil level too low" 21 "Valve locked out" 22 "Reserved" 41 "Manufacturer Specific" 62 "Error" 63 "Not available/not installed" ;
VAL_ 2566788862 AuxValve6State 0 "Blocked" 1 "Extend" 2 "Retract" 3 "Floating" 4 "Reserved" 15 "Don't Care" ;
VAL_ 2566788862 AuxValve6FailSafeMode 0 "Block" 1 "Float" 2 "Error indication" 3 "Not available" ;
VAL_ 2566788862 AuxiliaryValve6ExitReasonCode 0 "No reason/all clear" 1 "Operator presence not detected" 2 "Implement released control of function" 3 "Operator override of function" 4 "Operator control not in valid position" 5 "Remote command timeout" 6 "Remote command out of range/invalid" 7 "Function not calibrated" 8 "Operator control fault" 9 "Function fault" 10 "Reserved" 20 "Hydraulic oil level too low" 21 "Valve locked out" 22 "Reserved" 41 "Manufacturer Specific" 62 "Error" 63 "Not available/not installed" ;
VAL_ 2566789118 AuxValve7State 0 "Blocked" 1 "Extend" 2 "Retract" 3 "Floating" 4 "Reserved" 15 "Don't Care" ;
VAL_ 2566789118 AuxValve7FailSafeMode 0 "Block" 1 "Float" 2 "Error indication" 3 "Not available" ;
VAL_ 2566789118 AuxiliaryValve7ExitReasonCode 0 "No reason/all clear" 1 "Operator presence not detected" 2 "Implement released control of function" 3 "Operator override of function" 4 "Operator control not in valid position" 5 "Remote command timeout" 6 "Remote command out of range/invalid" 7 "Function not calibrated" 8 "Operator control fault" 9 "Function fault" 10 "Reserved" 20 "Hydraulic oil level too low" 21 "Valve locked out" 22 "Reserved" 41 "Manufacturer Specific" 62 "Error" 63 "Not available/not installed" ;
VAL_ 2566789374 AuxValve8State 0 "Blocked" 1 "Extend" 2 "Retract" 3 "Floating" 4 "Reserved" 15 "Don't Care" ;
VAL_ 2566789374 AuxValve8FailSafeMode 0 "Block" 1 "Float" 2 "Error indication" 3 "Not available" ;
VAL_ 2566789374 AuxiliaryValve8ExitReasonCode 0 "No reason/all clear" 1 "Operator presence not detected" 2 "Implement released control of function" 3 "Operator override of function" 4 "Operator control not in valid position" 5 "Remote command timeout" 6 "Remote command out of range/invalid" 7 "Function not calibrated" 8 "Operator control fault" 9 "Function fault" 10 "Reserved" 20 "Hydraulic oil level too low" 21 "Valve locked out" 22 "Reserved" 41 "Manufacturer Specific" 62 "Error" 63 "Not available/not installed" ;
VAL_ 2566789630 AuxValve9State 0 "Blocked" 1 "Extend" 2 "Retract" 3 "Floating" 4 "Reserved" 15 "Don't Care" ;
VAL_ 2566789630 AuxValve9FailSafeMode 0 "Block" 1 "Float" 2 "Error indication" 3 "Not available" ;
VAL_ 2566789630 AuxiliaryValve9ExitReasonCode 0 "No reason/all clear" 1 "Operator presence not detected" 2 "Implement released control of function" 3 "Operator override of function" 4 "Operator control not in valid position" 5 "Remote command timeout" 6 "Remote command out of range/invalid" 7 "Function not calibrated" 8 "Operator control fault" 9 "Function fault" 10 "Reserved" 20 "Hydraulic oil level too low" 21 "Valve locked out" 22 "Reserved" 41 "Manufacturer Specific" 62 "Error" 63 "Not available/not installed" ;
VAL_ 2566789886 AuxValve10State 0 "Blocked" 1 "Extend" 2 "Retract" 3 "Floating" 4 "Reserved" 15 "Don't Care" ;
VAL_ 2566789886 AuxValve10FailSafeMode 0 "Block" 1 "Float" 2 "Error indication" 3 "Not available" ;
VAL_ 2566789886 AuxiliaryValve10ExitReasonCode 0 "No reason/all clear" 1 "Operator presence not detected" 2 "Implement released control of function" 3 "Operator override of function" 4 "Operator control not in valid position" 5 "Remote command timeout" 6 "Remote command out of range/invalid" 7 "Function not calibrated" 8 "Operator control fault" 9 "Function fault" 10 "Reserved" 20 "Hydraulic oil level too low" 21 "Valve locked out" 22 "Reserved" 41 "Manufacturer Specific" 62 "Error" 63 "Not available/not installed" ;
VAL_ 2566790142 AuxValve11State 0 "Blocked" 1 "Extend" 2 "Retract" 3 "Floating" 4 "Reserved" 15 "Don't Care" ;
VAL_ 2566790142 AuxValve11FailSafeMode 0 "Block" 1 "Float" 2 "Error indication" 3 "Not available" ;
VAL_ 2566790142 AuxiliaryValve11ExitReasonCode 0 "No reason/all clear" 1 "Operator presence not detected" 2 "Implement released control of function" 3 "Operator override of function" 4 "Operator control not in valid position" 5 "Remote command timeout" 6 "Remote command out of range/invalid" 7 "Function not calibrated" 8 "Operator control fault" 9 "Function fault" 10 "Reserved" 20 "Hydraulic oil level too low" 21 "Valve locked out" 22 "Reserved" 41 "Manufacturer Specific" 62 "Error" 63 "Not available/not installed" ;
VAL_ 2566790398 AuxValve12State 0 "Blocked" 1 "Extend" 2 "Retract" 3 "Floating" 4 "Reserved" 15 "Don't Care" ;
VAL_ 2566790398 AuxValve12FailSafeMode 0 "Block" 1 "Float" 2 "Error indication" 3 "Not available" ;
VAL_ 2566790398 AuxiliaryValve12ExitReasonCode 0 "No reason/all clear" 1 "Operator presence not detected" 2 "Implement released control of function" 3 "Operator override of function" 4 "Operator control not in valid position" 5 "Remote command timeout" 6 "Remote command out of range/invalid" 7 "Function not calibrated" 8 "Operator control fault" 9 "Function fault" 10 "Reserved" 20 "Hydraulic oil level too low" 21 "Valve locked out" 22 "Reserved" 41 "Manufacturer Specific" 62 "Error" 63 "Not available/not installed" ;
VAL_ 2566790654 AuxValve13State 0 "Blocked" 1 "Extend" 2 "Retract" 3 "Floating" 4 "Reserved" 15 "Don't Care" ;
VAL_ 2566790654 AuxValve13FailSafeMode 0 "Block" 1 "Float" 2 "Error indication" 3 "Not available" ;
VAL_ 2566790654 AuxiliaryValve13ExitReasonCode 0 "No reason/all clear" 1 "Operator presence not detected" 2 "Implement released control of function" 3 "Operator override of function" 4 "Operator control not in valid position" 5 "Remote command timeout" 6 "Remote command out of range/invalid" 7 "Function not calibrated" 8 "Operator control fault" 9 "Function fault" 10 "Reserved" 20 "Hydraulic oil level too low" 21 "Valve locked out" 22 "Reserved" 41 "Manufacturer Specific" 62 "Error" 63 "Not available/not installed" ;
VAL_ 2566790910 AuxValve14State 0 "Blocked" 1 "Extend" 2 "Retract" 3 "Floating" 4 "Reserved" 15 "Don't Care" ;
VAL_ 2566790910 AuxValve14FailSafeMode 0 "Block" 1 "Float" 2 "Error indication" 3 "Not available" ;
VAL_ 2566790910 AuxiliaryValve14ExitReasonCode 0 "No reason/all clear" 1 "Operator presence not detected" 2 "Implement released control of function" 3 "Operator override of function" 4 "Operator control not in valid position" 5 "Remote command timeout" 6 "Remote command out of range/invalid" 7 "Function not calibrated" 8 "Operator control fault" 9 "Function fault" 10 "Reserved" 20 "Hydraulic oil level too low" 21 "Valve locked out" 22 "Reserved" 41 "Manufacturer Specific" 62 "Error" 63 "Not available/not installed" ;
VAL_ 2566791166 AuxValve15State 0 "Blocked" 1 "Extend" 2 "Retract" 3 "Floating" 4 "Reserved" 15 "Don't Care" ;
VAL_ 2566791166 AuxValve15FailSafeMode 0 "Block" 1 "Float" 2 "Reserved" 3 "Don't Care" ;
VAL_ 2566791166 AuxiliaryValve15ExitReasonCode 0 "No reason/all clear" 1 "Operator presence not detected" 2 "Implement released control of function" 3 "Operator override of function" 4 "Operator control not in valid position" 5 "Remote command timeout" 6 "Remote command out of range/invalid" 7 "Function not calibrated" 8 "Operator control fault" 9 "Function fault" 10 "Reserved" 20 "Hydraulic oil level too low" 21 "Valve locked out" 22 "Reserved" 41 "Manufacturer Specific" 62 "Error" 63 "Not available/not installed" ;
VAL_ 2566795518 AuxValve0StateCommand 0 "Block" 1 "Extend" 2 "Retract" 3 "Float" 4 "Reserved" 15 "Don't Care" ;
VAL_ 2566795518 AuxValve0FailSafeModeCommand 0 "Block" 1 "Float" 2 "Reserved" 3 "Don't Care" ;
VAL_ 2566795774 AuxValve1StateCommand 0 "Block" 1 "Extend" 2 "Retract" 3 "Float" 4 "Reserved" 15 "Don't Care" ;
VAL_ 2566795774 AuxValve1FailSafeModeCommand 0 "Block" 1 "Float" 2 "Reserved" 3 "Don't Care" ;
VAL_ 2566796030 AuxValve2StateCommand 0 "Block" 1 "Extend" 2 "Retract" 3 "Float" 4 "Reserved" 15 "Don't Care" ;
VAL_ 2566796030 AuxValve2FailSafeModeCommand 0 "Block" 1 "Float" 2 "Reserved" 3 "Don't Care" ;
VAL_ 2566796286 AuxValve3StateCommand 0 "Block" 1 "Extend" 2 "Retract" 3 "Float" 4 "Reserved" 15 "Don't Care" ;
VAL_ 2566796286 AuxValve3FailSafeModeCommand 0 "Block" 1 "Float" 2 "Reserved" 3 "Don't Care" ;
VAL_ 2566796542 AuxValve4StateCommand 0 "Block" 1 "Extend" 2 "Retract" 3 "Float" 4 "Reserved" 15 "Don't Care" ;
VAL_ 2566796542 AuxValve4FailSafeModeCommand 0 "Block" 1 "Float" 2 "Reserved" 3 "Don't Care" ;
VAL_ 2566796798 AuxValve5StateCommand 0 "Block" 1 "Extend" 2 "Retract" 3 "Float" 4 "Reserved" 15 "Don't Care" ;
VAL_ 2566796798 AuxValve5FailSafeModeCommand 0 "Block" 1 "Float" 2 "Reserved" 3 "Don't Care" ;
VAL_ 2566797054 AuxValve6StateCommand 0 "Block" 1 "Extend" 2 "Retract" 3 "Float" 4 "Reserved" 15 "Don't Care" ;
VAL_ 2566797054 AuxValve6FailSafeModeCommand 0 "Block" 1 "Float" 2 "Reserved" 3 "Don't Care" ;
VAL_ 2566797310 AuxValve7StateCommand 0 "Block" 1 "Extend" 2 "Retract" 3 "Float" 4 "Reserved" 15 "Don't Care" ;
VAL_ 2566797310 AuxValve7FailSafeModeCommand 0 "Block" 1 "Float" 2 "Reserved" 3 "Don't Care" ;
VAL_ 2566797566 AuxValve8StateCommand 0 "Block" 1 "Extend" 2 "Retract" 3 "Float" 4 "Reserved" 15 "Don't Care" ;
VAL_ 2566797566 AuxValve8FailSafeModeCommand 0 "Block" 1 "Float" 2 "Reserved" 3 "Don't Care" ;
VAL_ 2566797822 AuxValve9StateCommand 0 "Block" 1 "Extend" 2 "Retract" 3 "Float" 4 "Reserved" 15 "Don't Care" ;
VAL_ 2566797822 AuxValve9FailSafeModeCommand 0 "Block" 1 "Float" 2 "Reserved" 3 "Don't Care" ;
VAL_ 2566798078 AuxValve10StateCommand 0 "Block" 1 "Extend" 2 "Retract" 3 "Float" 4 "Reserved" 15 "Don't Care" ;
VAL_ 2566798078 AuxValve10FailSafeModeCommand 0 "Block" 1 "Float" 2 "Reserved" 3 "Don't Care" ;
VAL_ 2566798334 AuxValve11StateCommand 0 "Block" 1 "Extend" 2 "Retract" 3 "Float" 4 "Reserved" 15 "Don't Care" ;
VAL_ 2566798334 AuxValve11FailSafeModeCommand 0 "Block" 1 "Float" 2 "Reserved" 3 "Don't Care" ;
VAL_ 2566798590 AuxValve12StateCommand 0 "Block" 1 "Extend" 2 "Retract" 3 "Float" 4 "Reserved" 15 "Don't Care" ;
VAL_ 2566798590 AuxValve12FailSafeModeCommand 0 "Block" 1 "Float" 2 "Reserved" 3 "Don't Care" ;
VAL_ 2566798846 AuxValve13StateCommand 0 "Block" 1 "Extend" 2 "Retract" 3 "Float" 4 "Reserved" 15 "Don't Care" ;
VAL_ 2566798846 AuxValve13FailSafeModeCommand 0 "Block" 1 "Float" 2 "Reserved" 3 "Don't Care" ;
VAL_ 2566799102 AuxValve14StateCommand 0 "Block" 1 "Extend" 2 "Retract" 3 "Float" 4 "Reserved" 15 "Don't Care" ;
VAL_ 2566799102 AuxValve14FailSafeModeCommand 0 "Block" 1 "Float" 2 "Reserved" 3 "Don't Care" ;
VAL_ 2566799358 AuxValve15StateCommand 0 "Block" 1 "Extend" 2 "Retract" 3 "Float" 4 "Reserved" 15 "Don't Care" ;
VAL_ 2566799358 AuxValve15FailSafeModeCommand 0 "Block" 1 "Float" 2 "Reserved" 3 "Don't Care" ;
VAL_ 2566799614 RunningLight 0 "De-activated" 1 "Activated" 2 "Fault Detected" 3 "Not Available" ;
VAL_ 2566799614 AlternateBeamHeadLightData 0 "De-activated" 1 "Activated" 2 "Fault Detected" 3 "Not Available" ;
VAL_ 2566799614 LowBeamHeadLightData 0 "De-activated" 1 "Activated" 2 "Fault Detected" 3 "Not Available" ;
VAL_ 2566799614 HighBeamHeadLightData 0 "De-activated" 1 "Activated" 2 "Fault Detected" 3 "Not Available" ;
VAL_ 2566799614 TractorFrontFogLights 0 "De-activated" 1 "Activated" 2 "Fault Detected" 3 "Not Available" ;
VAL_ 2566799614 RotatingBeaconLight 0 "De-activated" 1 "Activated" 2 "Fault Detected" 3 "Not Available" ;
VAL_ 2566799614 RightTurnSignalLights 0 "De-activated" 1 "Activated" 2 "Fault Detected" 3 "Not Available" ;
VAL_ 2566799614 LeftTurnSignalLights 0 "De-activated" 1 "Activated" 2 "Fault Detected" 3 "Not Available" ;
VAL_ 2566799614 BackUpLightAndAlarmHorn 0 "De-activated" 1 "Activated" 2 "Fault Detected" 3 "Not Available" ;
VAL_ 2566799614 CenterStopLight 0 "De-activated" 1 "Activated" 2 "Fault Detected" 3 "Not Available" ;
VAL_ 2566799614 RightStopLight 0 "De-activated" 1 "Activated" 2 "Fault Detected" 3 "Not Available" ;
VAL_ 2566799614 LeftStopLight 0 "De-activated" 1 "Activated" 2 "Fault Detected" 3 "Not Available" ;
VAL_ 2566799614 ImplementClearanceLight 0 "De-activated" 1 "Activated" 2 "Fault Detected" 3 "Not Available" ;
VAL_ 2566799614 TractorClearanceLight 0 "De-activated" 1 "Activated" 2 "Fault Detected" 3 "Not Available" ;
VAL_ 2566799614 ImplementMarkerLight 0 "De-activated" 1 "Activated" 2 "Fault Detected" 3 "Not Available" ;
VAL_ 2566799614 TractorMarkerLight 0 "De-activated" 1 "Activated" 2 "Fault Detected" 3 "Not Available" ;
VAL_ 2566799614 RearFogLights 0 "De-activated" 1 "Activated" 2 "Fault Detected" 3 "Not Available" ;
VAL_ 2566799614 TractorUndersideMntdWorkLights 0 "De-activated" 1 "Activated" 2 "Fault Detected" 3 "Not Available" ;
VAL_ 2566799614 TractorRearLowMountedWorkLights 0 "De-activated" 1 "Activated" 2 "Fault Detected" 3 "Not Available" ;
VAL_ 2566799614 TractorRearHighMountedWorkLights 0 "De-activated" 1 "Activated" 2 "Fault Detected" 3 "Not Available" ;
VAL_ 2566799614 TractorSideLowMountedWorkLights 0 "De-activated" 1 "Activated" 2 "Fault Detected" 3 "Not Available" ;
VAL_ 2566799614 TractorSideHighMountedWorkLights 0 "De-activated" 1 "Activated" 2 "Fault Detected" 3 "Not Available" ;
VAL_ 2566799614 TractorFrontLowMountedWorkLights 0 "De-activated" 1 "Activated" 2 "Fault Detected" 3 "Not Available" ;
VAL_ 2566799614 TractorFrntHighMountedWorkLights 0 "De-activated" 1 "Activated" 2 "Fault Detected" 3 "Not Available" ;
VAL_ 2566799614 ImplementOEMOption2Light 0 "De-activated" 1 "Activated" 2 "Fault Detected" 3 "Not Available" ;
VAL_ 2566799614 ImplementOEMOption1Light 0 "De-activated" 1 "Activated" 2 "Fault Detected" 3 "Not Available" ;
VAL_ 2566799614 ImplementRightFacingWorkLight 0 "De-activated" 1 "Activated" 2 "Fault Detected" 3 "Not Available" ;
VAL_ 2566799614 ImplementLeftForwardWorkLight 0 "De-activated" 1 "Activated" 2 "Fault Detected" 3 "Not Available" ;
VAL_ 2566799614 ImplementRightForwardWorkLight 0 "De-activated" 1 "Activated" 2 "Fault Detected" 3 "Not Available" ;
VAL_ 2566799614 ImplementLeftFacingWorkLight 0 "De-activated" 1 "Activated" 2 "Fault Detected" 3 "Not Available" ;
VAL_ 2566799614 ImplementRearWorkLight 0 "De-activated" 1 "Activated" 2 "Fault Detected" 3 "Not Available" ;
VAL_ 2365473278 RunningLightCommand 0 "De-activate" 1 "Activate" 2 "Reserved" 3 "Don't Care" ;
VAL_ 2365473278 AlternateBeamHeadLightCommand 0 "De-activate" 1 "Activate" 2 "Reserved" 3 "Don't Care" ;
VAL_ 2365473278 LowBeamHeadLightCommand 0 "De-activate" 1 "Activate" 2 "Reserved" 3 "Don't Care" ;
VAL_ 2365473278 HighBeamHeadLightCommand 0 "De-activate" 1 "Activate" 2 "Reserved" 3 "Don't Care" ;
VAL_ 2365473278 TractorFrontFogLightsCommand 0 "De-activate" 1 "Activate" 2 "Reserved" 3 "Don't Care" ;
VAL_ 2365473278 RotatingBeaconLightCommand 0 "De-activate" 1 "Activate" 2 "Reserved" 3 "Don't Care" ;
VAL_ 2365473278 RightTurnSignalLightsCommand 0 "De-activate" 1 "Activate" 2 "Reserved" 3 "Don't Care" ;
VAL_ 2365473278 LeftTurnSignalLightsCommand 0 "De-activate" 1 "Activate" 2 "Reserved" 3 "Don't Care" ;
VAL_ 2365473278 BackUpLightAndAlarmHornCommand 0 "De-activate" 1 "Activate" 2 "Reserved" 3 "Don't Care" ;
VAL_ 2365473278 CenterStopLightCommand 0 "De-activate" 1 "Activate" 2 "Reserved" 3 "Don't Care" ;
VAL_ 2365473278 RightStopLightCommand 0 "De-activate" 1 "Activate" 2 "Reserved" 3 "Don't Care" ;
VAL_ 2365473278 LeftStopLightCommand 0 "De-activate" 1 "Activate" 2 "Reserved" 3 "Don't Care" ;
VAL_ 2365473278 ImplementClearanceLightCommand 0 "De-activate" 1 "Activate" 2 "Reserved" 3 "Don't Care" ;
VAL_ 2365473278 TractorClearanceLightCommand 0 "De-activate" 1 "Activate" 2 "Reserved" 3 "Don't Care" ;
VAL_ 2365473278 ImplementMarkerLightCommand 0 "De-activate" 1 "Activate" 2 "Reserved" 3 "Don't Care" ;
VAL_ 2365473278 TractorMarkerLightCommand 0 "De-activate" 1 "Activate" 2 "Reserved" 3 "Don't Care" ;
VAL_ 2365473278 RearFogLightCommand 0 "De-activate" 1 "Activate" 2 "Reserved" 3 "Don't Care" ;
VAL_ 2365473278 TractorUnderSdeMntdWorkLightsCmd 0 "De-activate" 1 "Activate" 2 "Reserved" 3 "Don't Care" ;
VAL_ 2365473278 TractorRearLowMntdWorkLightsCmd 0 "De-activate" 1 "Activate" 2 "Reserved" 3 "Don't Care" ;
VAL_ 2365473278 TractorRearHghMntdWorkLightsCmd 0 "De-activate" 1 "Activate" 2 "Reserved" 3 "Don't Care" ;
VAL_ 2365473278 TractorSideLowMntdWorkLightsCmd 0 "De-activate" 1 "Activate" 2 "Reserved" 3 "Don't Care" ;
VAL_ 2365473278 TractorSideHghMntdWorkLightsCmd 0 "De-activate" 1 "Activate" 2 "Reserved" 3 "Don't Care" ;
VAL_ 2365473278 TractorFrntLowMntdWorkLightsCmd 0 "De-activate" 1 "Activate" 2 "Reserved" 3 "Don't Care" ;
VAL_ 2365473278 TractorFrntHghMntdWorkLightsCmd 0 "De-activate" 1 "Activate" 2 "Reserved" 3 "Don't Care" ;
VAL_ 2365473278 ImplementOEMOption2LightCommand 0 "De-activate" 1 "Activate" 2 "Reserved" 3 "Don't Care" ;
VAL_ 2365473278 ImplementOEMOption1LightCommand 0 "De-activate" 1 "Activate" 2 "Reserved" 3 "Don't Care" ;
VAL_ 2365473278 ImplementRightFacingWorkLightCmd 0 "De-activate" 1 "Activate" 2 "Reserved" 3 "Don't Care" ;
VAL_ 2365473278 ImplementLeftForwardWorkLightCmd 0 "De-activate" 1 "Activate" 2 "Reserved" 3 "Don't Care" ;
VAL_ 2365473278 LightingDataRequestCommand 0 "De-activate" 1 "Activate" 2 "Reserved" 3 "Don't Care" ;
VAL_ 2365473278 ImplementRightFrwdWorkLightCmd 0 "De-activate" 1 "Activate" 2 "Reserved" 3 "Don't Care" ;
VAL_ 2365473278 ImplementLeftFacingWorkLightCmd 0 "De-activate" 1 "Activate" 2 "Reserved" 3 "Don't Care" ;
VAL_ 2365473278 ImplementRearWorkLightCommand 0 "De-activate" 1 "Activate" 2 "Reserved" 3 "Don't Care" ;
VAL_ 2566800126 RearPowerTakeOffEngagementCmd 0 "Disengage Power take off" 1 "Engage Power take off" 2 "Reserved" 3 "Don't Care" ;
VAL_ 2566800126 FrontPowerTakeOffEngagementCmd 0 "Disengage Power take off" 1 "Engage Power take off" 2 "Reserved" 3 "Don't Care" ;
VAL_ 2566800126 RearPowerTakeOffEconomyModeCmd 0 "Disengage Power take off's economy mode" 1 "Engage Power take off's economy mode" 2 "Reserved" 3 "Don't Care" ;
VAL_ 2566800126 FrontPowerTakeOffEconomyModeCmd 0 "Disengage Power take off's economy mode" 1 "Engage Power take off's economy mode" 2 "Reserved" 3 "Don't Care" ;
VAL_ 2566800126 RearPowerTakeOffModeCommand 0 "Select 540 rpm mode" 1 "Select 1000 rpm mode" 2 "Reserved" 3 "Don't Care" ;
VAL_ 2566800126 FrontPowerTakeOffModeCommand 0 "Select 540 rpm mode" 1 "Select 1000 rpm mode" 2 "Reserved" 3 "Don't Care" ;
VAL_ 2566800382 RearPowerTakeOffEconomyMode 0 "Power take off economy mode is disengaged" 1 "Power take off economy mode is engaged" 2 "Error indication" 3 "Not available" ;
VAL_ 2566800382 RearPowerTakeOffMode 0 "Power take off mode is 540" 1 "Power take off mode is 1000" 2 "Error indication" 3 "Not available" ;
VAL_ 2566800382 RearPowerTakeOffEngagement 0 "Power take off disengaged" 1 "Power take off engaged" 2 "Error indication" 3 "Not available" ;
VAL_ 2566800382 RearPTOExitReasonCode 0 "No reason/all clear" 1 "Operator presence not detected" 2 "Implement released control of function" 3 "Operator override of function" 4 "Operator control not in valid position" 5 "Remote command timeout" 6 "Remote command out of range/invalid" 7 "Function not calibrated" 8 "Operator control fault" 9 "Function fault" 10 "Reserved" 20 "Hydraulic oil level too low" 21 "Valve locked out" 22 "Reserved" 41 "Manufacturer Specific" 62 "Error" 63 "Not available/not installed" ;
VAL_ 2566800638 FrontPowerTakeOffEconomyMode 0 "Power take off economy mode is disengaged" 1 "Power take off economy mode is engaged" 2 "Error indication" 3 "Not available" ;
VAL_ 2566800638 FrontPowerTakeOffMode 0 "Power take off mode is 540" 1 "Power take off mode is 1000" 2 "Error indication" 3 "Not available" ;
VAL_ 2566800638 FrontPowerTakeOffEngagement 0 "Power take off disengaged" 1 "Power take off engaged" 2 "Error indication" 3 "Not available" ;
VAL_ 2566800638 FrontHitchExitReasonCode 0 "No reason/all clear" 1 "Operator presence not detected" 2 "Implement released control of function" 3 "Operator override of function" 4 "Operator control not in valid position" 5 "Remote command timeout" 6 "Remote command out of range/invalid" 7 "Function not calibrated" 8 "Operator control fault" 9 "Function fault" 10 "Reserved" 20 "Hydraulic oil level too low" 21 "Valve locked out" 22 "Reserved" 41 "Manufacturer Specific" 62 "Error" 63 "Not available/not installed" ;
VAL_ 2566800638 FrontPTOExitReasonCode 0 "No reason/all clear" 1 "Operator presence not detected" 2 "Implement released control of function" 3 "Operator override of function" 4 "Operator control not in valid position" 5 "Remote command timeout" 6 "Remote command out of range/invalid" 7 "Function not calibrated" 8 "Operator control fault" 9 "Function fault" 10 "Reserved" 20 "Hydraulic oil level too low" 21 "Valve locked out" 22 "Reserved" 41 "Manufacturer Specific" 62 "Error" 63 "Not available/not installed" ;
VAL_ 2566800894 RearHitchInWorkIndication 0 "Hitch position is out-of-work" 1 "Hitch position is in-work" 2 "Error indication" 3 "Not available" ;
VAL_ 2566800894 RearHitchExitReasonCode 0 "No reason/all clear" 1 "Operator presence not detected" 2 "Implement released control of function" 3 "Operator override of function" 4 "Operator control not in valid position" 5 "Remote command timeout" 6 "Remote command out of range/invalid" 7 "Function not calibrated" 8 "Operator control fault" 9 "Function fault" 10 "Reserved" 20 "Hydraulic oil level too low" 21 "Valve locked out" 22 "Reserved" 41 "Manufacturer Specific" 62 "Error" 63 "Not available/not installed" ;
VAL_ 2566801150 FrontHitchInWorkIndication 0 "Hitch position is out-of-work" 1 "Hitch position is in-work" 2 "Error indication" 3 "Not available" ;
VAL_ 2566801406 MaintainAcuatorPower 0 "No Further Requirement for PWR" 1 "Requirement for 2 more seconds of PWR" 2 "Reserved" 3 "Don't Care" ;
VAL_ 2566801406 MaintainECUPower 0 "No Further Requirement for ECU_PWR" 1 "Requirement for 2 more seconds of ECU_PWR" 2 "Reserved" 3 "Don't Care" ;
VAL_ 2566801406 ImplementWorkState 0 "Implement is Not ready for field work" 1 "Implement is ready for field work" 2 "Error indication" 3 "Not available" ;
VAL_ 2566801406 ImplementParkState 0 "Implement may Not be disconnected" 1 "Implement may be disconnected" 2 "Error indication" 3 "Not available" ;
VAL_ 2566801406 ImplementTransportState 0 "Implement may Not be transported" 1 "Implement may be transported" 2 "Error indication" 3 "Not available" ;
VAL_ 2566801662 WheelBasedDirection 0 "Reverse" 1 "Forward" 2 "Error indication" 3 "Not available" ;
VAL_ 2566801662 KeySwitchNOTOFF 0 "Key Switch Off" 1 "Key Switch Not Off" 2 "Error indication" 3 "Not available" ;
VAL_ 2566801918 GroundBasedDirection 0 "Reverse" 1 "Forward" 2 "Error indication" 3 "Not available" ;
VAL_ 2566802174 TrnsmCurrentRngDisplayBlankStat 0 "Not Blanked" 1 "Blanked" 2 "Error" 3 "Supported" ;
VAL_ 2566802174 TransmissionServiceIndicator 0 "Transmission Service Indicator is off" 1 "Transmission Service Indicator is on continuously" 2 "Transmission Service Indicator is flashing" 3 "Not available" ;
VAL_ 2566802174 TrnsmRqedRngDisplayBlankStat 0 "Inactive" 1 "Active" 2 "Reserved" 3 "Take no action" ;
VAL_ 2566802174 TrnsmRqedRngDisplayFlashStat 0 "Inactive" 1 "Active" 2 "Reserved" 3 "Take no action" ;
VAL_ 2566802174 TransmissionReadyForBrakeRelease 0 "Transmission Not Ready for Brake Release" 1 "Transmission Ready for Brake Release" 2 "Error" 3 "Not available" ;
VAL_ 2566802174 ActiveShiftConsoleIndicator 0 "Primary shift console is active" 1 "Secondary shift console is active" 2 "Reserved" 3 "Not available" ;
VAL_ 2566802174 TransmissionEngineCrankEnable 0 "Cranking disabled" 1 "Cranking enabled" 2 "Error" 3 "Not available" ;
VAL_ 2566802174 TransmissionShiftInhibitIndictr 0 "Inactive" 1 "Active (on continuously)" 2 "Active (flashing)" 3 "Take no action" ;
VAL_ 2566802174 TransmissionMode4Indicator 0 "Transmission Mode 4 not active" 1 "Transmission Mode 4 Active" 2 "Error" 3 "Not available" ;
VAL_ 2566802174 TransmissionMode3Indicator 0 "Transmission Mode 3 not active" 1 "Transmission Mode 3 Active" 2 "Error" 3 "Not available" ;
VAL_ 2566802174 TransmissionMode2Indicator 0 "Transmission Mode 2 not active" 1 "Transmission Mode 2 Active" 2 "Error" 3 "Not available" ;
VAL_ 2566802174 TransmissionMode1Indicator 0 "Transmission Mode 1 not active" 1 "Transmission Mode 1 Active" 2 "Error" 3 "Not available" ;
VAL_ 2566802174 TransmissionMode5Indicator 0 "Transmission Mode 5 not active" 1 "Transmission Mode 5 active" 2 "Error" 3 "Not available" ;
VAL_ 2566802174 TransmissionMode6Indicator 0 "Transmission Mode 6 not active" 1 "Transmission Mode 6 active" 2 "Error" 3 "Not available" ;
VAL_ 2566802174 TransmissionMode7Indicator 0 "Transmission Mode 7 not active" 1 "Transmission Mode 7 active" 2 "Error" 3 "Not available" ;
VAL_ 2566802174 TransmissionMode8Indicator 0 "Transmission Mode 8 not active" 1 "Transmission Mode 8 active" 2 "Error" 3 "Not available" ;
VAL_ 2566802174 TrnsmReverseGearShftInhbtStat 0 "Reverse gear shifts are currently allowed" 1 "Reverse gear shifts are currently inhibited" 2 "Error" 3 "Not Available" ;
VAL_ 2566802174 TransmissionWarningIndicator 0 "Transmission Warning Indicator is off" 1 "Transmission Warning Indicator is on continuously" 2 "Transmission Warning Indicator is flashing" 3 "Not available" ;
VAL_ 2566802174 TransmissionMode9Indicator 0 "Transmission Mode 9 not active" 1 "Transmission Mode 9 active" 2 "Error indicator" 3 "Not available" ;
VAL_ 2566802174 TransmissionMode10Indicator 0 "Transmission Mode 10 not active" 1 "Transmission Mode 10 active" 2 "Error indicator" 3 "Not available" ;
VAL_ 2566802174 TrnsmAirSupplyPressIndictr 0 "Normal Pressure Range" 1 "Low pressure" 2 "Very low pressure" 3 "No pressure" 4 "Over pressure" 5 "Not defined" 6 "Error indicator" 7 "Not available" ;
VAL_ 2566802174 TransmissionAutoNeutralState 0 "No request received - conditions are such that an Auto-Neutral request would be honored." 1 "No request received - conditions are such that an Auto-Neutral request would NOT be honored." 2 "Auto-Neutral request received - shift to Auto-Neutral state is pending." 3 "Auto-Neutral request received - shift to Auto-Neutral state has been achieved." 4 "Auto-Neutral request received - shift to Auto-Neutral state is inhibited." 5 "Reserved" 6 "Error" 7 "Not Available" ;
VAL_ 2566802174 TransmissionManualModeIndicator 0 "Transmission is not in a Manual Mode" 1 "Transmission is in a Manual Mode" 2 "Reserved" 3 "Not Available" ;
VAL_ 2566802174 TransmissionLoadReductionIndictr 0 "Transmission Load Reduction is not active" 1 "Transmission Load Reduction is active" 2 "Error" 3 "Not Available" ;
VAL_ 2566802174 TrnsmPreDefinedRngLmtIndictr 0 "Pre-defined range limit is not in effect" 1 "Pre-defined range limit is in effect" 2 "Error" 3 "Not Available" ;
VAL_ 2566802174 TransmissionCoastModeIndicator 0 "Transmission Coast Mode is not active" 1 "Transmission Coast Mode is active" 2 "Error" 3 "Not Available" ;
VAL_ 2566802686 RearBlackOutMarkerSelect 0 "Off" 1 "On" 2 "Reserved" 3 "Not Supported" ;
VAL_ 2566802686 FrontBlackOutMarkerLampSelect 0 "Off" 1 "On" 2 "Reserved" 3 "Not Supported" ;
VAL_ 2566802686 ConvoyLampSelect 0 "Off" 1 "On" 2 "Reserved" 3 "Not Supported" ;
VAL_ 2566802686 ConvoyDrivingLampSelect 0 "Off" 1 "On" 2 "Reserved" 3 "Not Supported" ;
VAL_ 2566802686 BlackOutBrakeStopLampSelect 0 "Off" 1 "On" 2 "Reserved" 3 "Not Supported" ;
VAL_ 2566802686 NightVisionIlluminatorSelect 0 "Off" 1 "On" 2 "Reserved" 3 "Not Supported" ;
VAL_ 2566802686 BlackOutWorkLampSelect 0 "Off" 1 "On" 2 "Reserved" 3 "Not Supported" ;
VAL_ 2566803198 PositionOfDoors 0 "At least 1 door is open" 1 "Closing last door" 2 "All doors close" 3 "Not defined" 14 "Error" 15 "Not available" ;
VAL_ 2566803198 RampWheelChairLiftPosition 0 "Inside bus" 1 "Outside bus" 2 "Error" 3 "Not available" ;
VAL_ 2566803198 Status2OfDoors 0 "all bus doors are disabled" 1 "at least 1 bus door enabled" 2 "error" 3 "not available" ;
VAL_ 2566803454 VDCInformationSignal 0 "Off" 1 "On" 2 "Reserved" 3 "Don't care/take no action" ;
VAL_ 2566803454 VDCFullyOperational 0 "Not fully operational" 1 "Fully operational" 2 "Reserved" 3 "Don't care/Take no action" ;
VAL_ 2566803454 VDCBrakeLightRequest 0 "Turn brake light not on" 1 "Turn brake light on" 2 "Reserved" 3 "Don't care/Take no action" ;
VAL_ 2566803454 ROPEngineControlActive 0 "ROP engine control passive but installed" 1 "ROP engine control active" 2 "Reserved" 3 "Don't care/Take no action" ;
VAL_ 2566803454 ROPBrakeControlActive 0 "ROP brake control passive but installed" 1 "ROP brake control active" 2 "Reserved" 3 "Don't care/Take no action" ;
VAL_ 2566803454 YCEngineControlActive 0 "YC engine control passive but installed" 1 "YC engine control active" 2 "Reserved" 3 "Don't care/Take no action" ;
VAL_ 2566803454 YCBrakeControlActive 0 "YC brake control passive but installed" 1 "YC brake control active" 2 "Reserved" 3 "Don't care/Take no action" ;
VAL_ 2566803454 TrailerVDCActive 0 "VDC passive, but installed" 1 "VDC active" 2 "Reserved" 3 "Not availble or not installed" ;
VAL_ 2566803966 ACCUsageDemand 0 "driver demand for not using" 1 "driver demand for using" 2 "reserved" 3 "don't care" ;
VAL_ 2566803966 RequestedACCDistanceMode 0 "Requested ACC Distance Mode #1" 1 "Requested ACC Distance Mode #2" 2 "Requested ACC Distance Mode #3" 3 "Requested ACC Distance Mode #4" 4 "Requested ACC Distance Mode #5" 5 "not defined" 6 "error condition" 7 "not available" ;
